VERSION "HNNBNNNYNNNNNNNNNNNNNNNNNNNNNNNNNNNNNNNNNN/4/%%%/4/'%**4NNN///"

NS_ :

BS_:

BU_: BAP_Tester BCM1 Gateway Gateway_PAG Klima_MSB Lift_VA VAS_L VAS_R

BO_ 2589283621 Klima_17: 8 BCM1
 SG_ KL_NV_Energie_Anf : 12|8@1+ (10,0) [0|2530] "Unit_WattHour"  Gateway,Gateway_PAG
 SG_ KL_FlHz_Soll_VL : 20|3@1+ (1,0) [0|6] "Unit_None"  BCM1,Gateway,Gateway_PAG
 SG_ KL_FlHz_Soll_HL : 23|3@1+ (1,0) [0|6] "Unit_None"  BCM1,Gateway,Gateway_PAG
 SG_ KL_FlHz_Soll_VR : 26|3@1+ (1,0) [0|6] "Unit_None"  BCM1,Gateway,Gateway_PAG
 SG_ KL_FlHz_Soll_HR : 29|3@1+ (1,0) [0|6] "Unit_None"  BCM1,Gateway,Gateway_PAG
 SG_ KL_Umluft_Connect_status : 32|3@1+ (1.0,0.0) [0.0|7] ""  Gateway,Gateway_PAG
 SG_ KL_ECO_PRO_Aktiv : 35|1@1+ (1.0,0.0) [0.0|1] ""  Gateway,Gateway_PAG
 SG_ KL_QBit_Sonnenintensitaet : 36|1@1+ (1.0,0.0) [0.0|1] ""  Gateway,Gateway_PAG
 SG_ KL_ZR_Anforderung : 37|2@1+ (1.0,0.0) [0.0|3] ""  Gateway,Gateway_PAG
 SG_ KL_ACmax_Aktiv : 39|1@1+ (1.0,0.0) [0.0|1] ""  Gateway,Gateway_PAG
 SG_ KL_Defrost_Aktiv : 40|1@1+ (1.0,0.0) [0.0|1] ""  Gateway,Gateway_PAG
 SG_ KL_ECO_Aktiv : 41|1@1+ (1.0,0.0) [0.0|1] ""  Gateway,Gateway_PAG
 SG_ KL_Status_Klimastil : 42|2@1+ (1.0,0.0) [0.0|3] ""  Gateway,Gateway_PAG
 SG_ KL_Kundeneingriff_Geblaese : 44|1@1+ (1.0,0.0) [0.0|1] ""  Gateway,Gateway_PAG
 SG_ KL_Thermischer_Bedarf : 45|3@1+ (1.0,0.0) [0.0|7] ""  Gateway,Gateway_PAG
 SG_ KL_Eps_Innen : 48|8@1+ (0.5,-50) [-50.0|50.0] "Unit_DegreCelsi"  Gateway,Gateway_PAG
 SG_ KL_Sonnenintensitaet : 56|8@1+ (10,0) [0|1000] "Unit_WattPerMeterSquar"  Gateway,Gateway_PAG

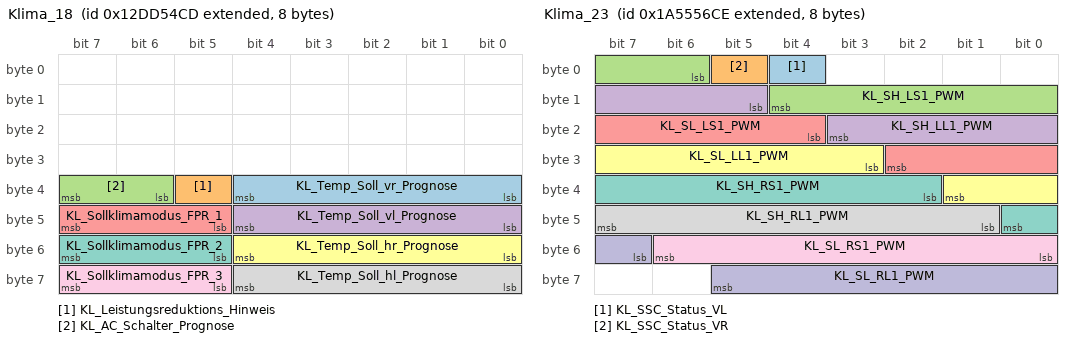
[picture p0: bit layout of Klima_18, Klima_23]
BO_ 2463978701 Klima_18: 8 BCM1
 SG_ KL_Temp_Soll_vr_Prognose : 32|5@1+ (0.5,15.5) [15.5|30.0] "Unit_DegreCelsi"  Gateway,Gateway_PAG
 SG_ KL_Leistungsreduktions_Hinweis : 37|1@1+ (1.0,0.0) [0.0|1] ""  Gateway,Gateway_PAG
 SG_ KL_AC_Schalter_Prognose : 38|2@1+ (1.0,0.0) [0.0|3] ""  Gateway,Gateway_PAG
 SG_ KL_Temp_Soll_vl_Prognose : 40|5@1+ (0.5,15.5) [15.5|30.0] "Unit_DegreCelsi"  Gateway,Gateway_PAG
 SG_ KL_Sollklimamodus_FPR_1 : 45|3@1+ (1.0,0.0) [0.0|7] ""  Gateway,Gateway_PAG
 SG_ KL_Temp_Soll_hr_Prognose : 48|5@1+ (0.5,15.5) [15.5|30.0] "Unit_DegreCelsi"  Gateway,Gateway_PAG
 SG_ KL_Sollklimamodus_FPR_2 : 53|3@1+ (1.0,0.0) [0.0|7] ""  Gateway,Gateway_PAG
 SG_ KL_Temp_Soll_hl_Prognose : 56|5@1+ (0.5,15.5) [15.5|30.0] "Unit_DegreCelsi"  Gateway,Gateway_PAG
 SG_ KL_Sollklimamodus_FPR_3 : 61|3@1+ (1.0,0.0) [0.0|7] ""  Gateway,Gateway_PAG

BO_ 2589283689 Klima_19: 8 Klima_MSB
 SG_ KL_FANonly_Aktiv : 63|1@1+ (1.0,0.0) [0.0|1] ""  Gateway_PAG

BO_ 2589284046 Klima_23: 8 Klima_MSB
 SG_ KL_SSC_Status_VL : 4|1@1+ (1.0,0.0) [0.0|1] ""  BCM1
 SG_ KL_SSC_Status_VR : 5|1@1+ (1.0,0.0) [0.0|1] ""  BCM1
 SG_ KL_SH_LS1_PWM : 6|7@1+ (1,0) [0|100] "Unit_PerCent"  BCM1
 SG_ KL_SH_LL1_PWM : 13|7@1+ (1,0) [0|100] "Unit_PerCent"  BCM1
 SG_ KL_SL_LS1_PWM : 20|7@1+ (1,0) [0|100] "Unit_PerCent"  BCM1
 SG_ KL_SL_LL1_PWM : 27|7@1+ (1,0) [0|100] "Unit_PerCent"  BCM1
 SG_ KL_SH_RS1_PWM : 34|7@1+ (1,0) [0|100] "Unit_PerCent"  BCM1
 SG_ KL_SH_RL1_PWM : 41|7@1+ (1,0) [0|100] "Unit_PerCent"  BCM1
 SG_ KL_SL_RS1_PWM : 48|7@1+ (1,0) [0|100] "Unit_PerCent"  BCM1
 SG_ KL_SL_RL1_PWM : 55|7@1+ (1,0) [0|100] "Unit_PerCent"  BCM1

BO_ 992 Klima_hinten_01: 8 BCM1
 SG_ KL_Fond_Fuss_Temp_hl : 0|10@1+ (0.1,-5) [-5.0|97.1] "Unit_DegreCelsi"  Gateway,Gateway_PAG
 SG_ KL_SL_Soll_hl : 10|3@1+ (1.0,0.0) [0.0|7] ""  BCM1,Gateway,Gateway_PAG
 SG_ KL_SL_Soll_hr : 13|3@1+ (1.0,0.0) [0.0|7] ""  BCM1,Gateway,Gateway_PAG
 SG_ KL_Fond_Fuss_Temp_hr : 16|10@1+ (0.1,-5) [-5.0|97.1] "Unit_DegreCelsi"  Gateway,Gateway_PAG
 SG_ KL_SH_Soll_hl : 26|3@1+ (1.0,0.0) [0.0|7] ""  BCM1,Gateway,Gateway_PAG
 SG_ KL_SH_Soll_hr : 29|3@1+ (1.0,0.0) [0.0|7] ""  BCM1,Gateway,Gateway_PAG
 SG_ KL_MA_Temp_hl : 32|10@1+ (0.1,-5) [-5.0|97.1] "Unit_DegreCelsi"  Gateway,Gateway_PAG
 SG_ KL_SIH_Takt_hl : 42|1@1+ (1.0,0.0) [0.0|1] ""  Gateway,Gateway_PAG
 SG_ KL_SIH_Takt_hr : 43|1@1+ (1.0,0.0) [0.0|1] ""  Gateway,Gateway_PAG
 SG_ KL_Fehler_Umluft : 44|1@1+ (1.0,0.0) [0.0|1] ""  Gateway,Gateway_PAG
 SG_ KL_RAB : 45|1@1+ (1.0,0.0) [0.0|1] ""  Gateway,Gateway_PAG
 SG_ KL_Fond_Absperrventil : 46|1@1+ (1.0,0.0) [0.0|1] ""  Gateway,Gateway_PAG
 SG_ KL_Fond_KD_Fehler : 47|1@1+ (1.0,0.0) [0.0|1] ""  Gateway,Gateway_PAG
 SG_ KL_MA_Temp_hr : 48|10@1+ (0.1,-5) [-5.0|97.1] "Unit_DegreCelsi"  Gateway,Gateway_PAG
 SG_ KL_Fehler_Fussraum_Klappen : 58|2@1+ (1.0,0.0) [0.0|3] ""  Gateway,Gateway_PAG
 SG_ KL_Fehler_Temp_Klappen : 60|2@1+ (1.0,0.0) [0.0|3] ""  Gateway,Gateway_PAG
 SG_ KL_Fehler_Temp_MA_Klappen : 62|2@1+ (1.0,0.0) [0.0|3] ""  Gateway,Gateway_PAG

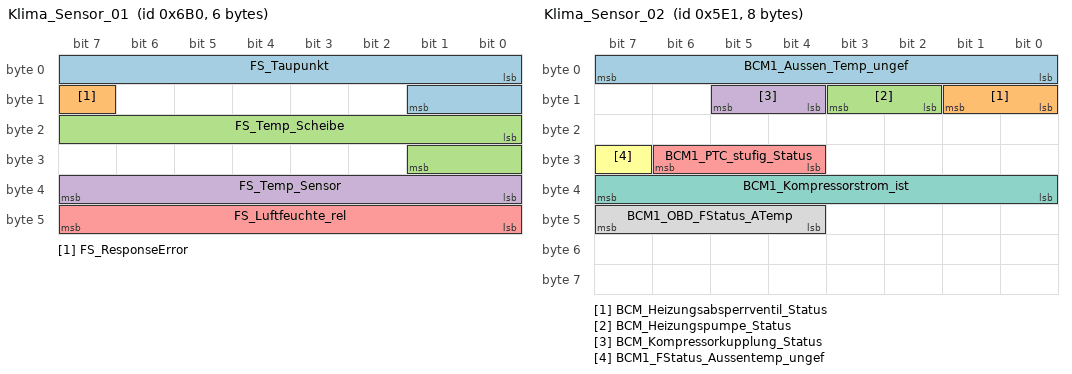
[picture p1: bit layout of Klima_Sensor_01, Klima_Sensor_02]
BO_ 1712 Klima_Sensor_01: 6 BCM1
 SG_ FS_Taupunkt : 0|10@1+ (0.1,-39.6) [-39.5|60.4] "Unit_DegreCelsi"  Gateway,Gateway_PAG,Klima_MSB
 SG_ FS_ResponseError : 15|1@1+ (1.0,0.0) [0.0|1] ""  Gateway,Gateway_PAG,Klima_MSB
 SG_ FS_Temp_Scheibe : 16|10@1+ (0.1,-39.6) [-39.5|60.4] "Unit_DegreCelsi"  Gateway,Gateway_PAG,Klima_MSB
 SG_ FS_Temp_Sensor : 32|8@1+ (0.5,-40) [-39.5|87.0] "Unit_DegreCelsi"  Gateway,Gateway_PAG,Klima_MSB
 SG_ FS_Luftfeuchte_rel : 40|8@1+ (0.5,-0.5) [0.0|100.0] "Unit_PerCent"  Gateway,Gateway_PAG,Klima_MSB

BO_ 1505 Klima_Sensor_02: 8 BCM1
 SG_ BCM1_Aussen_Temp_ungef : 0|8@1+ (0.5,-50) [-50.0|76.0] "Unit_DegreCelsi"  Gateway,Gateway_PAG,Klima_MSB,VAS_L,VAS_R
 SG_ BCM_Heizungsabsperrventil_Status : 8|2@1+ (1.0,0.0) [0.0|3] ""  Gateway,Gateway_PAG,Klima_MSB
 SG_ BCM_Heizungspumpe_Status : 10|2@1+ (1.0,0.0) [0.0|3] ""  Gateway,Gateway_PAG,Klima_MSB
 SG_ BCM_Kompressorkupplung_Status : 12|2@1+ (1.0,0.0) [0.0|3] ""  Gateway,Gateway_PAG,Klima_MSB
 SG_ BCM1_PTC_stufig_Status : 28|3@1+ (1.0,0.0) [0.0|7] ""  Gateway,Gateway_PAG,Klima_MSB
 SG_ BCM1_FStatus_Aussentemp_ungef : 31|1@1+ (1.0,0.0) [0.0|1] ""  Gateway,Gateway_PAG,Klima_MSB,VAS_L,VAS_R
 SG_ BCM1_Kompressorstrom_ist : 32|8@1+ (4,0) [0|1000] "Unit_MilliAmper"  Gateway,Gateway_PAG,Klima_MSB
 SG_ BCM1_OBD_FStatus_ATemp : 44|4@1+ (1.0,0.0) [0.0|15] ""  Gateway,Gateway_PAG,Klima_MSB

BO_ 1717 Klima_Sensor_03: 8 BCM1
 SG_ FSA_Taupunkt : 0|10@1+ (0.1,-40) [-40.0|60.0] "Unit_DegreCelsi"  Gateway,Gateway_PAG
 SG_ FSA_Err_Defekt_Tsens_TF : 10|1@1+ (1.0,0.0) [0.0|1] ""  Gateway,Gateway_PAG
 SG_ FSA_Luftfeuchte_TNCTOC : 11|1@1+ (1.0,0.0) [0.0|1] ""  Gateway,Gateway_PAG
 SG_ FSA_Luftfeuchte_TF : 12|1@1+ (1.0,0.0) [0.0|1] ""  Gateway,Gateway_PAG
 SG_ FSA_Err_Unterspannung_TF : 13|1@1+ (1.0,0.0) [0.0|1] ""  Gateway,Gateway_PAG
 SG_ FSA_Err_RAMROM_Check_TF : 14|1@1+ (1.0,0.0) [0.0|1] ""  Gateway,Gateway_PAG
 SG_ FSA_ResponseError : 15|1@1+ (1.0,0.0) [0.0|1] ""  Gateway,Gateway_PAG
 SG_ FSA_Temp_Luft : 16|10@1+ (0.1,-40) [-40.0|61.0] "Unit_DegreCelsi"  Gateway,Gateway_PAG
 SG_ FSA_Err_RAMROM_Check_TNCTOC : 26|1@1+ (1.0,0.0) [0.0|1] ""  Gateway,Gateway_PAG
 SG_ FSA_Lokal_Bus_elektr_Fehler : 27|1@1+ (1.0,0.0) [0.0|1] ""  Gateway,Gateway_PAG
 SG_ FSA_Timeout : 28|1@1+ (1.0,0.0) [0.0|1] ""  Gateway,Gateway_PAG
 SG_ FSA_Lokal_Bus_Unterbrechung : 29|1@1+ (1.0,0.0) [0.0|1] ""  Gateway,Gateway_PAG
 SG_ FSA_Err_Ueberspannung_TF : 30|1@1+ (1.0,0.0) [0.0|1] ""  Gateway,Gateway_PAG
 SG_ FSA_Luftfeuchte_rel : 32|8@1+ (0.5,0) [0.0|126.0] "Unit_PerCent"  Gateway,Gateway_PAG
 SG_ FSA_HW : 40|4@1+ (1,0) [0|15] ""  Gateway,Gateway_PAG
 SG_ FSA_SW : 44|4@1+ (1,0) [0|15] ""  Gateway,Gateway_PAG
 SG_ FSA_Temp_Sensor : 48|11@1+ (0.1,-40) [-40.0|90.0] "Unit_DegreCelsi"  Gateway,Gateway_PAG
 SG_ FSA_Sensorheizung_Status : 59|1@1+ (1.0,0.0) [0.0|1] ""  Gateway,Gateway_PAG
 SG_ FSA_Err_Defekt_HumSense_TF : 60|1@1+ (1.0,0.0) [0.0|1] ""  Gateway,Gateway_PAG
 SG_ FSA_Err_Defekt_HumSens_TNCTOC : 61|1@1+ (1.0,0.0) [0.0|1] ""  Gateway,Gateway_PAG
 SG_ FSA_ErrMemState : 62|2@1+ (1.0,0.0) [0.0|3] ""  Gateway,Gateway_PAG

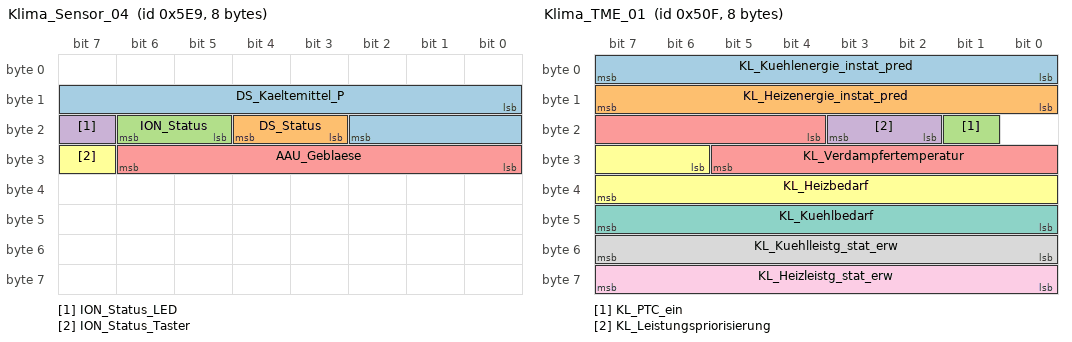
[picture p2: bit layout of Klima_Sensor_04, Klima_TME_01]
BO_ 1513 Klima_Sensor_04: 8 BCM1
 SG_ DS_Kaeltemittel_P : 8|11@1+ (0.0161,0) [0.0000|32.9245] "Unit_Bar"  Gateway,Gateway_PAG
 SG_ DS_Status : 19|2@1+ (1.0,0.0) [0.0|3] ""  Gateway,Gateway_PAG
 SG_ ION_Status : 21|2@1+ (1.0,0.0) [0.0|3] ""  Gateway,Gateway_PAG
 SG_ ION_Status_LED : 23|1@1+ (1.0,0.0) [0.0|1] ""  Gateway,Gateway_PAG
 SG_ AAU_Geblaese : 24|7@1+ (1,0) [0|100] "Unit_PerCent"  Gateway,Gateway_PAG
 SG_ ION_Status_Taster : 31|1@1+ (1.0,0.0) [0.0|1] ""  Gateway,Gateway_PAG

BO_ 1295 Klima_TME_01: 8 BCM1
 SG_ KL_Kuehlenergie_instat_pred : 0|8@1+ (25,0) [0|6325] "Unit_WattHour"  Gateway,Gateway_PAG
 SG_ KL_Heizenergie_instat_pred : 8|8@1+ (25,0) [0|6325] "Unit_WattHour"  Gateway,Gateway_PAG
 SG_ KL_PTC_ein : 17|1@1+ (1.0,0.0) [0.0|1] ""  Gateway,Gateway_PAG
 SG_ KL_Leistungspriorisierung : 18|2@1+ (1.0,0.0) [0.0|3] ""  Gateway,Gateway_PAG
 SG_ KL_Verdampfertemperatur : 20|10@1+ (0.1,-20) [-20.0|70.0] "Unit_DegreCelsi"  Gateway,Gateway_PAG
 SG_ KL_Heizbedarf : 30|10@1+ (0.1,0) [0.1|90.0] "Unit_DegreCelsi"  Gateway,Gateway_PAG
 SG_ KL_Kuehlbedarf : 40|8@1+ (0.1,0) [0.0|25.0] "Unit_DegreCelsi"  Gateway,Gateway_PAG
 SG_ KL_Kuehlleistg_stat_erw : 48|8@1+ (50,0) [0|12650] "Unit_Watt"  Gateway,Gateway_PAG
 SG_ KL_Heizleistg_stat_erw : 56|8@1+ (50,0) [0|12650] "Unit_Watt"  Gateway,Gateway_PAG

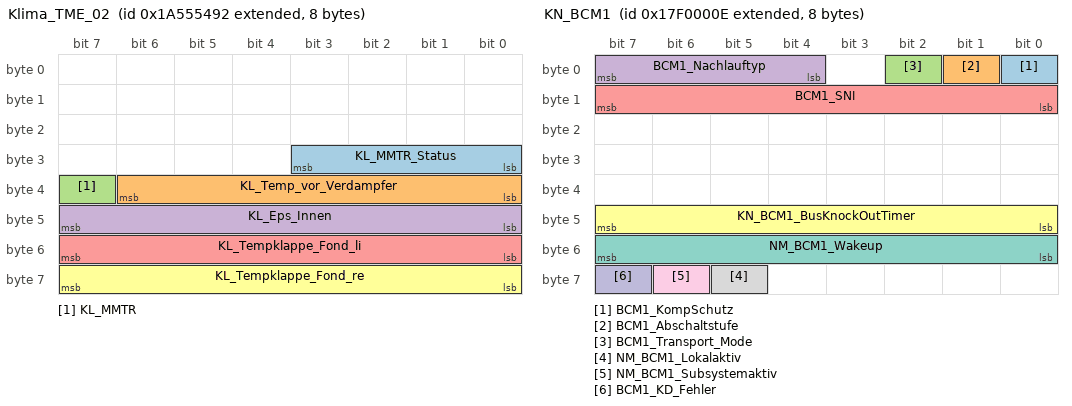
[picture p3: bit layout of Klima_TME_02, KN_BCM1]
BO_ 2589283474 Klima_TME_02: 8 BCM1
 SG_ KL_MMTR_Status : 24|4@1+ (1.0,0.0) [0.0|15] ""  Gateway,Gateway_PAG
 SG_ KL_Temp_vor_Verdampfer : 32|7@1+ (1,-20) [-20|70] "Unit_DegreCelsi"  Gateway,Gateway_PAG
 SG_ KL_MMTR : 39|1@1+ (1.0,0.0) [0.0|1] ""  Gateway,Gateway_PAG
 SG_ KL_Eps_Innen : 40|8@1+ (0.5,-50) [-50.0|50.0] "Unit_DegreCelsi"  Gateway,Gateway_PAG
 SG_ KL_Tempklappe_Fond_li : 48|8@1+ (0.5,0) [0.0|100.0] "Unit_PerCent"  Gateway,Gateway_PAG
 SG_ KL_Tempklappe_Fond_re : 56|8@1+ (0.5,0) [0.0|100.0] "Unit_PerCent"  Gateway,Gateway_PAG

BO_ 2549088270 KN_BCM1: 8 BCM1
 SG_ BCM1_KompSchutz : 0|1@1+ (1.0,0.0) [0.0|1] ""  Vector__XXX
 SG_ BCM1_Abschaltstufe : 1|1@1+ (1.0,0.0) [0.0|1] ""  Vector__XXX
 SG_ BCM1_Transport_Mode : 2|1@1+ (1.0,0.0) [0.0|1] ""  Vector__XXX
 SG_ BCM1_Nachlauftyp : 4|4@1+ (1.0,0.0) [0.0|15] ""  Gateway,Gateway_PAG
 SG_ BCM1_SNI : 8|8@1+ (1.0,0.0) [0.0|255] ""  Gateway,Gateway_PAG
 SG_ KN_BCM1_BusKnockOutTimer : 40|8@1+ (1,0) [0|254] "Unit_Minut"  Gateway,Gateway_PAG
 SG_ NM_BCM1_Wakeup : 48|8@1+ (1.0,0.0) [0.0|255] ""  Vector__XXX
 SG_ NM_BCM1_Lokalaktiv : 61|1@1+ (1.0,0.0) [0.0|1] ""  Gateway,Gateway_PAG
 SG_ NM_BCM1_Subsystemaktiv : 62|1@1+ (1.0,0.0) [0.0|1] ""  Gateway,Gateway_PAG
 SG_ BCM1_KD_Fehler : 63|1@1+ (1.0,0.0) [0.0|1] ""  Gateway,Gateway_PAG

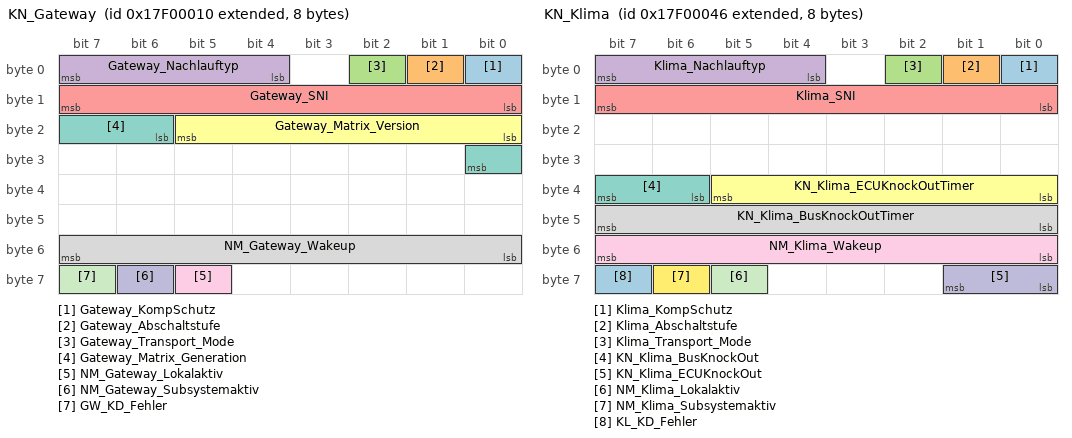
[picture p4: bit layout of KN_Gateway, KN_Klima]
BO_ 2549088272 KN_Gateway: 8 Gateway
 SG_ Gateway_KompSchutz : 0|1@1+ (1.0,0.0) [0.0|1] ""  Vector__XXX
 SG_ Gateway_Abschaltstufe : 1|1@1+ (1.0,0.0) [0.0|1] ""  Vector__XXX
 SG_ Gateway_Transport_Mode : 2|1@1+ (1.0,0.0) [0.0|1] ""  Vector__XXX
 SG_ Gateway_Nachlauftyp : 4|4@1+ (1.0,0.0) [0.0|15] ""  Vector__XXX
 SG_ Gateway_SNI : 8|8@1+ (1.0,0.0) [0.0|255] ""  Vector__XXX
 SG_ Gateway_Matrix_Version : 16|6@1+ (1,0) [0|63] "Unit_None"  Vector__XXX
 SG_ Gateway_Matrix_Generation : 22|3@1+ (1,0) [0|7] "Unit_None"  Vector__XXX
 SG_ NM_Gateway_Wakeup : 48|8@1+ (1.0,0.0) [0.0|255] ""  Vector__XXX
 SG_ NM_Gateway_Lokalaktiv : 61|1@1+ (1.0,0.0) [0.0|1] ""  Vector__XXX
 SG_ NM_Gateway_Subsystemaktiv : 62|1@1+ (1.0,0.0) [0.0|1] ""  Vector__XXX
 SG_ GW_KD_Fehler : 63|1@1+ (1.0,0.0) [0.0|1] ""  Vector__XXX

BO_ 2549088326 KN_Klima: 8 Klima_MSB
 SG_ Klima_KompSchutz : 0|1@1+ (1.0,0.0) [0.0|1] ""  Vector__XXX
 SG_ Klima_Abschaltstufe : 1|1@1+ (1.0,0.0) [0.0|1] ""  Vector__XXX
 SG_ Klima_Transport_Mode : 2|1@1+ (1.0,0.0) [0.0|1] ""  Vector__XXX
 SG_ Klima_Nachlauftyp : 4|4@1+ (1.0,0.0) [0.0|15] ""  Gateway,Gateway_PAG
 SG_ Klima_SNI : 8|8@1+ (1.0,0.0) [0.0|255] ""  Gateway,Gateway_PAG
 SG_ KN_Klima_ECUKnockOutTimer : 32|6@1+ (1,0) [0|62] "Unit_Minut"  Gateway,Gateway_PAG
 SG_ KN_Klima_BusKnockOut : 38|2@1+ (1.0,0.0) [0.0|3] ""  Gateway,Gateway_PAG
 SG_ KN_Klima_BusKnockOutTimer : 40|8@1+ (1,0) [0|254] ""  Gateway,Gateway_PAG
 SG_ NM_Klima_Wakeup : 48|8@1+ (1.0,0.0) [0.0|255] ""  Vector__XXX
 SG_ KN_Klima_ECUKnockOut : 56|2@1+ (1.0,0.0) [0.0|3] ""  Gateway,Gateway_PAG
 SG_ NM_Klima_Lokalaktiv : 61|1@1+ (1.0,0.0) [0.0|1] ""  Gateway,Gateway_PAG
 SG_ NM_Klima_Subsystemaktiv : 62|1@1+ (1.0,0.0) [0.0|1] ""  Gateway,Gateway_PAG
 SG_ KL_KD_Fehler : 63|1@1+ (1.0,0.0) [0.0|1] ""  Gateway,Gateway_PAG

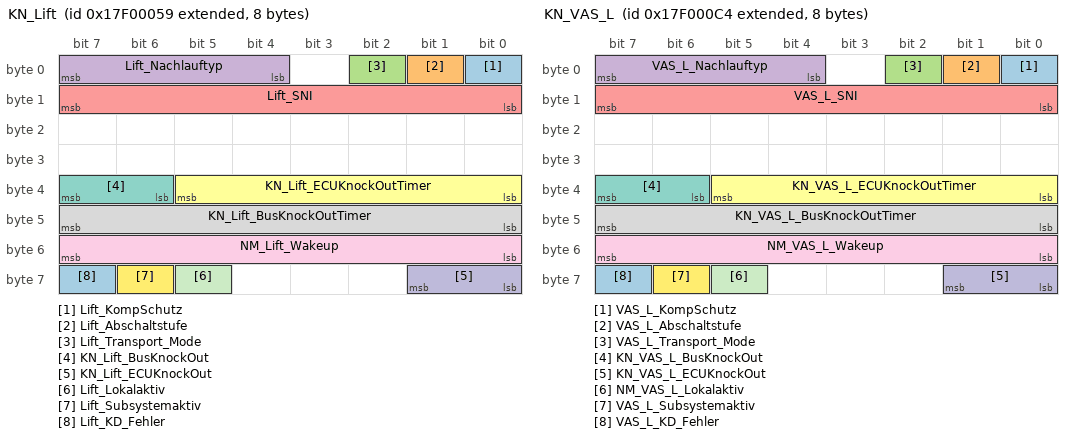
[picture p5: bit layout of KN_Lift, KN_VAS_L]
BO_ 2549088345 KN_Lift: 8 Lift_VA
 SG_ Lift_KompSchutz : 0|1@1+ (1.0,0.0) [0.0|1] ""  Vector__XXX
 SG_ Lift_Abschaltstufe : 1|1@1+ (1.0,0.0) [0.0|1] ""  Vector__XXX
 SG_ Lift_Transport_Mode : 2|1@1+ (1.0,0.0) [0.0|1] ""  Vector__XXX
 SG_ Lift_Nachlauftyp : 4|4@1+ (1.0,0.0) [0.0|15] ""  Gateway,Gateway_PAG
 SG_ Lift_SNI : 8|8@1+ (1.0,0.0) [0.0|255] ""  Gateway,Gateway_PAG
 SG_ KN_Lift_ECUKnockOutTimer : 32|6@1+ (1,0) [0|62] "Unit_Minut"  Gateway
 SG_ KN_Lift_BusKnockOut : 38|2@1+ (1.0,0.0) [0.0|3] ""  Gateway
 SG_ KN_Lift_BusKnockOutTimer : 40|8@1+ (1,0) [0|254] ""  Gateway
 SG_ NM_Lift_Wakeup : 48|8@1+ (1.0,0.0) [0.0|255] ""  Vector__XXX
 SG_ KN_Lift_ECUKnockOut : 56|2@1+ (1.0,0.0) [0.0|3] ""  Gateway
 SG_ Lift_Lokalaktiv : 61|1@1+ (1.0,0.0) [0.0|1] ""  Gateway,Gateway_PAG
 SG_ Lift_Subsystemaktiv : 62|1@1+ (1.0,0.0) [0.0|1] ""  Gateway
 SG_ Lift_KD_Fehler : 63|1@1+ (1.0,0.0) [0.0|1] ""  Gateway,Gateway_PAG

BO_ 2549088452 KN_VAS_L: 8 VAS_L
 SG_ VAS_L_KompSchutz : 0|1@1+ (1.0,0.0) [0.0|1] ""  Vector__XXX
 SG_ VAS_L_Abschaltstufe : 1|1@1+ (1.0,0.0) [0.0|1] ""  Vector__XXX
 SG_ VAS_L_Transport_Mode : 2|1@1+ (1.0,0.0) [0.0|1] ""  Vector__XXX
 SG_ VAS_L_Nachlauftyp : 4|4@1+ (1.0,0.0) [0.0|15] ""  Gateway,Gateway_PAG
 SG_ VAS_L_SNI : 8|8@1+ (1.0,0.0) [0.0|255] ""  Gateway,Gateway_PAG
 SG_ KN_VAS_L_ECUKnockOutTimer : 32|6@1+ (1,0) [0|62] ""  Gateway,Gateway_PAG
 SG_ KN_VAS_L_BusKnockOut : 38|2@1+ (1.0,0.0) [0.0|3] ""  Gateway,Gateway_PAG
 SG_ KN_VAS_L_BusKnockOutTimer : 40|8@1+ (1,0) [0|254] ""  Gateway,Gateway_PAG
 SG_ NM_VAS_L_Wakeup : 48|8@1+ (1.0,0.0) [0.0|255] ""  Vector__XXX
 SG_ KN_VAS_L_ECUKnockOut : 56|2@1+ (1.0,0.0) [0.0|3] ""  Gateway,Gateway_PAG
 SG_ NM_VAS_L_Lokalaktiv : 61|1@1+ (1.0,0.0) [0.0|1] ""  Gateway,Gateway_PAG
 SG_ VAS_L_Subsystemaktiv : 62|1@1+ (1.0,0.0) [0.0|1] ""  Vector__XXX
 SG_ VAS_L_KD_Fehler : 63|1@1+ (1.0,0.0) [0.0|1] ""  Gateway,Gateway_PAG

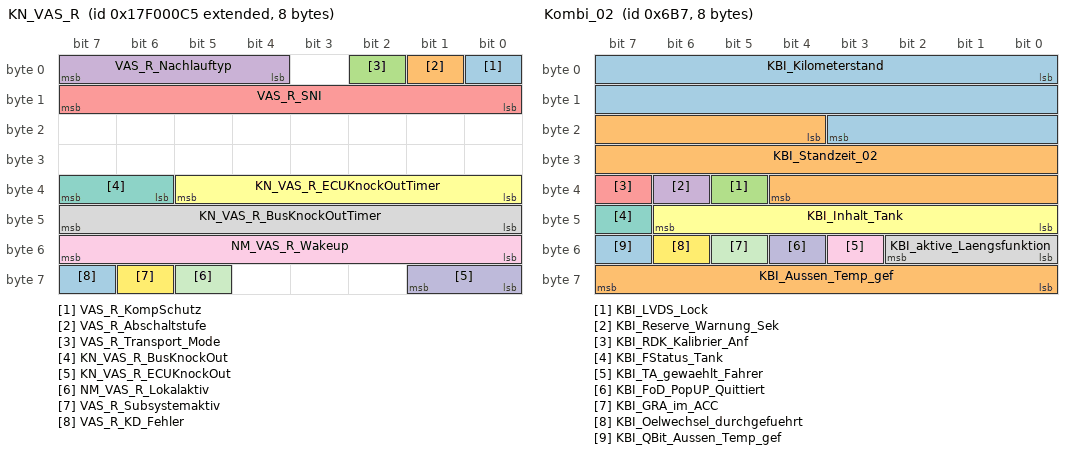
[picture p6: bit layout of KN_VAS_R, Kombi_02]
BO_ 2549088453 KN_VAS_R: 8 VAS_R
 SG_ VAS_R_KompSchutz : 0|1@1+ (1.0,0.0) [0.0|1] ""  Vector__XXX
 SG_ VAS_R_Abschaltstufe : 1|1@1+ (1.0,0.0) [0.0|1] ""  Vector__XXX
 SG_ VAS_R_Transport_Mode : 2|1@1+ (1.0,0.0) [0.0|1] ""  Vector__XXX
 SG_ VAS_R_Nachlauftyp : 4|4@1+ (1.0,0.0) [0.0|15] ""  Gateway,Gateway_PAG
 SG_ VAS_R_SNI : 8|8@1+ (1.0,0.0) [0.0|255] ""  Gateway,Gateway_PAG
 SG_ KN_VAS_R_ECUKnockOutTimer : 32|6@1+ (1,0) [0|62] ""  Gateway,Gateway_PAG
 SG_ KN_VAS_R_BusKnockOut : 38|2@1+ (1.0,0.0) [0.0|3] ""  Gateway,Gateway_PAG
 SG_ KN_VAS_R_BusKnockOutTimer : 40|8@1+ (1,0) [0|254] ""  Gateway,Gateway_PAG
 SG_ NM_VAS_R_Wakeup : 48|8@1+ (1.0,0.0) [0.0|255] ""  Vector__XXX
 SG_ KN_VAS_R_ECUKnockOut : 56|2@1+ (1.0,0.0) [0.0|3] ""  Gateway,Gateway_PAG
 SG_ NM_VAS_R_Lokalaktiv : 61|1@1+ (1.0,0.0) [0.0|1] ""  Gateway,Gateway_PAG
 SG_ VAS_R_Subsystemaktiv : 62|1@1+ (1.0,0.0) [0.0|1] ""  Vector__XXX
 SG_ VAS_R_KD_Fehler : 63|1@1+ (1.0,0.0) [0.0|1] ""  Gateway,Gateway_PAG

BO_ 779 Kombi_01: 8 Gateway
 SG_ KBI_ABS_Lampe : 0|1@1+ (1.0,0.0) [0.0|1] ""  Vector__XXX
 SG_ KBI_ESP_Lampe : 1|1@1+ (1.0,0.0) [0.0|1] ""  BCM1
 SG_ KBI_BKL_Lampe : 2|1@1+ (1.0,0.0) [0.0|1] ""  Vector__XXX
 SG_ KBI_Airbag_Lampe : 3|1@1+ (1.0,0.0) [0.0|1] ""  Vector__XXX
 SG_ KBI_SILA_gueltig : 4|1@1+ (1.0,0.0) [0.0|1] ""  Vector__XXX
 SG_ KBI_Lenkung_Lampe : 5|1@1+ (1,0) [0|1] ""  Vector__XXX
 SG_ KBI_Vorglueh_System_Lampe : 6|1@1+ (1.0,0.0) [0.0|1] ""  Vector__XXX
 SG_ KBI_NV_in_Anzeige : 7|1@1+ (1.0,0.0) [0.0|1] ""  Vector__XXX
 SG_ Kombi_01_BZ : 8|4@1+ (1,0) [0|15] ""  Vector__XXX
 SG_ KBI_Anzeigestatus_ACC : 12|1@1+ (1.0,0.0) [0.0|1] ""  Vector__XXX
 SG_ KBI_Anzeigestatus_GRA : 13|2@1+ (1.0,0.0) [0.0|3] ""  Vector__XXX
 SG_ KBI_Tankwarnung : 16|1@1+ (1.0,0.0) [0.0|1] ""  BCM1,Klima_MSB
 SG_ KBI_MFA_v_Einheit_01 : 17|1@1+ (1.0,0.0) [0.0|1] ""  Vector__XXX
 SG_ KBI_im_Stellgliedtest : 18|1@1+ (1.0,0.0) [0.0|1] ""  Vector__XXX
 SG_ KBI_Anzeigefehler_LDW : 19|2@1+ (1.0,0.0) [0.0|3] ""  Vector__XXX
 SG_ KBI_Tankwarnung_ungueltig : 21|1@1+ (1.0,0.0) [0.0|1] ""  Vector__XXX
 SG_ KBI_Handbremse : 23|1@1+ (1.0,0.0) [0.0|1] ""  Vector__XXX
 SG_ KBI_V_Digital : 24|9@1+ (1,0) [0|511] ""  Vector__XXX
 SG_ KBI_PLA_in_Anzeige : 33|1@1+ (1.0,0.0) [0.0|1] ""  BCM1
 SG_ KBI_Anzeigefehler_NV : 34|1@1+ (1.0,0.0) [0.0|1] ""  Vector__XXX
 SG_ KBI_Anzeigestatus_LIM : 35|2@1+ (1.0,0.0) [0.0|3] ""  Vector__XXX
 SG_ KBI_ARA_in_Anzeige : 37|1@1+ (1.0,0.0) [0.0|1] ""  BCM1
 SG_ KBI_Taster_Lift : 38|1@1+ (1.0,0.0) [0.0|1] ""  Vector__XXX
 SG_ KBI_Taster_Fahrwerk : 39|1@1+ (1.0,0.0) [0.0|1] ""  Vector__XXX
 SG_ KBI_GRA_Hauptschalter : 40|2@1+ (1.0,0.0) [0.0|3] ""  Vector__XXX
 SG_ KBI_Bestaetigung_ESP_Off : 42|2@1+ (1.0,0.0) [0.0|3] ""  Vector__XXX
 SG_ KBI_angez_Geschw : 48|10@1+ (0.32,0) [0.00|325.12] "Unit_KiloMeterPerHour"  Vector__XXX
 SG_ KBI_Einheit_Tacho : 58|1@1+ (1.0,0.0) [0.0|1] ""  Vector__XXX
 SG_ KBI_Konsistenz_ACC : 59|1@1+ (1.0,0.0) [0.0|1] ""  Vector__XXX
 SG_ KBI_Fehler_Anzeige_ACC : 60|1@1+ (1.0,0.0) [0.0|1] ""  Vector__XXX
 SG_ KBI_Anzeigefehler_SWA : 61|2@1+ (1.0,0.0) [0.0|3] ""  Vector__XXX
 SG_ KBI_Systemstatus : 63|1@1+ (1.0,0.0) [0.0|1] ""  Vector__XXX

BO_ 1719 Kombi_02: 8 Gateway
 SG_ KBI_Kilometerstand : 0|20@1+ (1,0) [0|1048573] "Unit_KiloMeter"  Vector__XXX
 SG_ KBI_Standzeit_02 : 20|17@1+ (1,0) [0|131068] "Unit_Secon"  BCM1,Klima_MSB
 SG_ KBI_LVDS_Lock : 37|1@1+ (1.0,0.0) [0.0|1] ""  Vector__XXX
 SG_ KBI_Reserve_Warnung_Sek : 38|1@1+ (1.0,0.0) [0.0|1] ""  Vector__XXX
 SG_ KBI_RDK_Kalibrier_Anf : 39|1@1+ (1.0,0.0) [0.0|1] ""  Vector__XXX
 SG_ KBI_Inhalt_Tank : 40|7@1+ (1,0) [0|125] "Unit_Liter"  Vector__XXX
 SG_ KBI_FStatus_Tank : 47|1@1+ (1.0,0.0) [0.0|1] ""  Vector__XXX
 SG_ KBI_aktive_Laengsfunktion : 48|3@1+ (1.0,0.0) [0.0|7] ""  Vector__XXX
 SG_ KBI_TA_gewaehlt_Fahrer : 51|1@1+ (1.0,0.0) [0.0|1] ""  Vector__XXX
 SG_ KBI_FoD_PopUP_Quittiert : 52|1@1+ (1.0,0.0) [0.0|1] ""  Vector__XXX
 SG_ KBI_GRA_im_ACC : 53|1@1+ (1.0,0.0) [0.0|1] ""  Vector__XXX
 SG_ KBI_Oelwechsel_durchgefuehrt : 54|1@1+ (1.0,0.0) [0.0|1] ""  Vector__XXX
 SG_ KBI_QBit_Aussen_Temp_gef : 55|1@1+ (1.0,0.0) [0.0|1] ""  BCM1,Klima_MSB
 SG_ KBI_Aussen_Temp_gef : 56|8@1+ (0.5,-50) [-50.0|75.0] "Unit_DegreCelsi"  BCM1,Klima_MSB,Lift_VA,VAS_L,VAS_R

BO_ 2549874958 KS_BCM1_Req: 8 Gateway
 SG_ KS_BCM1_Req_Data : 0|64@1+ (1.0,0.0) [0.0|18446744073709551615] ""  BCM1

BO_ 2550006030 KS_BCM1_Resp: 8 BCM1
 SG_ KS_BCM1_Resp_Data : 0|64@1+ (1.0,0.0) [0.0|18446744073709551615] ""  Gateway,Gateway_PAG

BO_ 2549875140 KS_VAS_L_Req: 8 Gateway
 SG_ KS_VAS_L_Req_Data : 0|64@1+ (1,0) [0|1] ""  VAS_L

BO_ 2550006212 KS_VAS_L_Resp: 8 VAS_L
 SG_ KS_VAS_L_Resp_Data : 0|64@1+ (1,0) [0|1] ""  Gateway,Gateway_PAG

BO_ 2549875141 KS_VAS_R_Req: 8 Gateway
 SG_ KS_VAS_R_Req_Data : 0|64@1+ (1,0) [0|1] ""  VAS_R

BO_ 2550006213 KS_VAS_R_Resp: 8 VAS_R
 SG_ KS_VAS_R_Resp_Data : 0|64@1+ (1,0) [0|1] ""  Gateway,Gateway_PAG

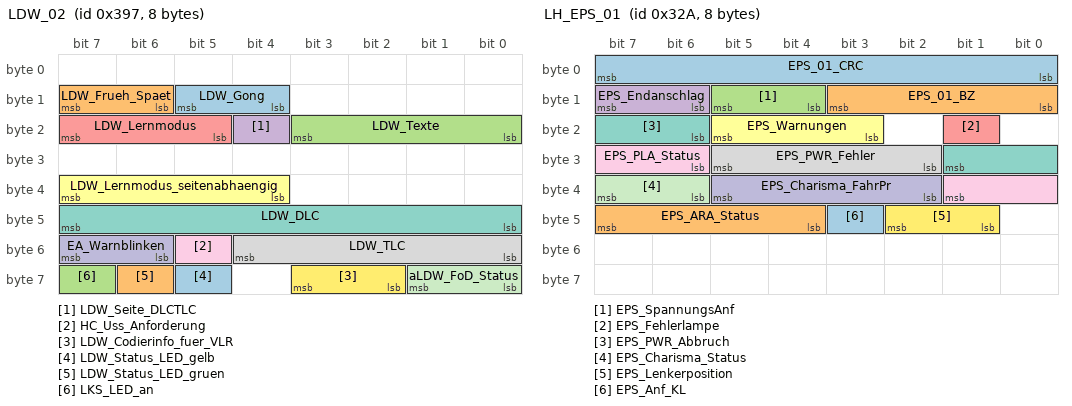
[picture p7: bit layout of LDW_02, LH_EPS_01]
BO_ 919 LDW_02: 8 Gateway
 SG_ LDW_Gong : 12|2@1+ (1.0,0.0) [0.0|3] ""  Vector__XXX
 SG_ LDW_Frueh_Spaet : 14|2@1+ (1.0,0.0) [0.0|3] ""  Vector__XXX
 SG_ LDW_Texte : 16|4@1+ (1.0,0.0) [0.0|15] ""  Vector__XXX
 SG_ LDW_Seite_DLCTLC : 20|1@1+ (1.0,0.0) [0.0|1] ""  Vector__XXX
 SG_ LDW_Lernmodus : 21|3@1+ (1.0,0.0) [0.0|7] ""  Vector__XXX
 SG_ LDW_Lernmodus_seitenabhaengig : 36|4@1+ (1.0,0.0) [0.0|15] ""  Vector__XXX
 SG_ LDW_DLC : 40|8@1+ (0.01,-1.25) [-1.25|1.25] "Unit_Meter"  Vector__XXX
 SG_ LDW_TLC : 48|5@1+ (0.1,0) [0.0|3.0] "Unit_Secon"  Vector__XXX
 SG_ HC_Uss_Anforderung : 53|1@1+ (1.0,0.0) [0.0|1] ""  BCM1
 SG_ EA_Warnblinken : 54|2@1+ (1.0,0.0) [0.0|3] ""  Vector__XXX
 SG_ aLDW_FoD_Status : 56|2@1+ (1.0,0.0) [0.0|3] ""  Vector__XXX
 SG_ LDW_Codierinfo_fuer_VLR : 58|2@1+ (1.0,0.0) [0.0|3] ""  Vector__XXX
 SG_ LDW_Status_LED_gelb : 61|1@1+ (1.0,0.0) [0.0|1] ""  Vector__XXX
 SG_ LDW_Status_LED_gruen : 62|1@1+ (1.0,0.0) [0.0|1] ""  Vector__XXX
 SG_ LKS_LED_an : 63|1@1+ (1.0,0.0) [0.0|1] ""  BCM1

BO_ 810 LH_EPS_01: 8 Gateway
 SG_ EPS_01_CRC : 0|8@1+ (1,0) [0|255] ""  BCM1
 SG_ EPS_01_BZ : 8|4@1+ (1,0) [0|15] ""  BCM1
 SG_ EPS_SpannungsAnf : 12|2@1+ (1.0,0.0) [0.0|3] ""  Vector__XXX
 SG_ EPS_Endanschlag : 14|2@1+ (1.0,0.0) [0.0|3] ""  Vector__XXX
 SG_ EPS_Fehlerlampe : 17|1@1+ (1.0,0.0) [0.0|1] ""  Vector__XXX
 SG_ EPS_Warnungen : 19|3@1+ (1.0,0.0) [0.0|7] ""  Vector__XXX
 SG_ EPS_PWR_Abbruch : 22|4@1+ (1.0,0.0) [0.0|15] ""  BCM1
 SG_ EPS_PWR_Fehler : 26|4@1+ (1.0,0.0) [0.0|15] ""  BCM1
 SG_ EPS_PLA_Status : 30|4@1+ (1.0,0.0) [0.0|15] ""  BCM1
 SG_ EPS_Charisma_FahrPr : 34|4@1+ (1.0,0.0) [0.0|15] ""  Vector__XXX
 SG_ EPS_Charisma_Status : 38|2@1+ (1.0,0.0) [0.0|3] ""  Vector__XXX
 SG_ EPS_Lenkerposition : 41|2@1+ (1.0,0.0) [0.0|3] ""  Vector__XXX
 SG_ EPS_Anf_KL : 43|1@1+ (1.0,0.0) [0.0|1] ""  Vector__XXX
 SG_ EPS_ARA_Status : 44|4@1+ (1.0,0.0) [0.0|15] ""  BCM1

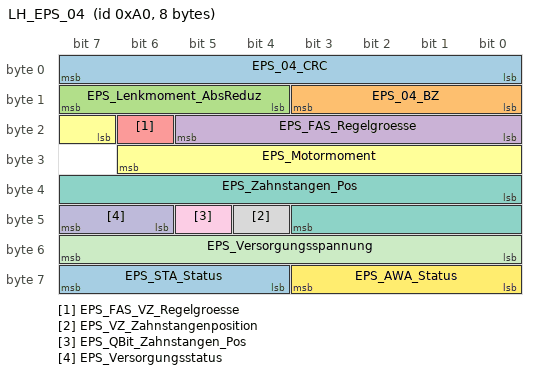
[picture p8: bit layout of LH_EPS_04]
BO_ 160 LH_EPS_04: 8 Gateway
 SG_ EPS_04_CRC : 0|8@1+ (1,0) [0|255] ""  BCM1
 SG_ EPS_04_BZ : 8|4@1+ (1,0) [0|15] ""  BCM1
 SG_ EPS_Lenkmoment_AbsReduz : 12|4@1+ (0.62,0.61) [0.61|8.05] "Unit_NewtoMeter"  BCM1
 SG_ EPS_FAS_Regelgroesse : 16|6@1+ (2,0) [0|100] "Unit_PerCent"  Vector__XXX
 SG_ EPS_FAS_VZ_Regelgroesse : 22|1@1+ (1.0,0.0) [0.0|1] ""  Vector__XXX
 SG_ EPS_Motormoment : 23|8@1+ (0.2,-16.2) [-16.0|16.0] "Unit_NewtoMeter"  Vector__XXX
 SG_ EPS_Zahnstangen_Pos : 32|12@1+ (0.02,0) [0.00|81.86] "Unit_MilliMeter"  BCM1
 SG_ EPS_VZ_Zahnstangenposition : 44|1@1+ (1.0,0.0) [0.0|1] ""  BCM1
 SG_ EPS_QBit_Zahnstangen_Pos : 45|1@1+ (1.0,0.0) [0.0|1] ""  BCM1
 SG_ EPS_Versorgungsstatus : 46|2@1+ (1.0,0.0) [0.0|3] ""  Vector__XXX
 SG_ EPS_Versorgungsspannung : 48|8@1+ (0.05,5.05) [5.05|17.70] "Unit_Volt"  Vector__XXX
 SG_ EPS_AWA_Status : 56|4@1+ (1.0,0.0) [0.0|15] ""  Vector__XXX
 SG_ EPS_STA_Status : 60|4@1+ (1.0,0.0) [0.0|15] ""  Vector__XXX

BO_ 981 Licht_Anf_01: 8 BCM1
 SG_ Licht_Anf_01_CRC : 0|8@1+ (1,0) [0|255] ""  Gateway,Gateway_PAG
 SG_ Licht_Anf_01_BZ : 8|4@1+ (1,0) [0|15] ""  Gateway,Gateway_PAG
 SG_ BCM1_Kurvenlicht_links_Anf : 12|1@1+ (1.0,0.0) [0.0|1] ""  Gateway,Gateway_PAG
 SG_ BCM1_Kurvenlicht_rechts_Anf : 13|1@1+ (1.0,0.0) [0.0|1] ""  Gateway,Gateway_PAG
 SG_ BCM1_Standlicht_Anf : 14|1@1+ (1.0,0.0) [0.0|1] ""  Gateway,Gateway_PAG
 SG_ BCM1_Abblendlicht_Anf : 15|1@1+ (1.0,0.0) [0.0|1] ""  Gateway,Gateway_PAG
 SG_ BCM1_Fernlicht_Anf : 16|1@1+ (1.0,0.0) [0.0|1] ""  Gateway,Gateway_PAG
 SG_ BCM1_Nebellicht_Anf : 17|1@1+ (1.0,0.0) [0.0|1] ""  Gateway,Gateway_PAG
 SG_ BCM1_Parklicht_li_Anf : 18|1@1+ (1.0,0.0) [0.0|1] ""  Gateway,Gateway_PAG
 SG_ BCM1_Parklicht_re_Anf : 19|1@1+ (1.0,0.0) [0.0|1] ""  Gateway,Gateway_PAG
 SG_ BCM1_Nebelschluss_Ahg_Anf : 20|1@1+ (1.0,0.0) [0.0|1] ""  Gateway,Gateway_PAG
 SG_ BCM1_Nebelschluss_Fzg_Anf : 21|1@1+ (1.0,0.0) [0.0|1] ""  Gateway,Gateway_PAG
 SG_ BCM1_Schlusslicht_Anf : 22|1@1+ (1.0,0.0) [0.0|1] ""  Gateway,Gateway_PAG
 SG_ BCM_Rueckfahrlicht_Anf : 23|1@1+ (1.0,0.0) [0.0|1] ""  Gateway,Gateway_PAG
 SG_ BCM1_Signaturlicht_Anf : 24|1@1+ (1.0,0.0) [0.0|1] ""  Gateway,Gateway_PAG
 SG_ BCM1_Umfeldleuchten_Anf : 25|1@1+ (1.0,0.0) [0.0|1] ""  Gateway,Gateway_PAG
 SG_ BCM1_Tagfahrlicht_Anf : 26|1@1+ (1.0,0.0) [0.0|1] ""  Gateway,Gateway_PAG
 SG_ BCM1_Regenlicht_Anf : 27|1@1+ (1.0,0.0) [0.0|1] ""  Gateway,Gateway_PAG
 SG_ BCM1_Autobahnlicht_Anf : 28|1@1+ (1.0,0.0) [0.0|1] ""  Gateway,Gateway_PAG
 SG_ BCM1_Touristen_Licht_Anf : 29|1@1+ (1.0,0.0) [0.0|1] ""  Gateway,Gateway_PAG
 SG_ BCM1_CH_aktiv : 30|1@1+ (1.0,0.0) [0.0|1] ""  Gateway,Gateway_PAG
 SG_ BCM1_LH_aktiv : 31|1@1+ (1.0,0.0) [0.0|1] ""  Gateway,Gateway_PAG
 SG_ BCM1_Gleitende_Leuchtw_Anf : 32|1@1+ (1.0,0.0) [0.0|1] ""  Gateway,Gateway_PAG
 SG_ BCM1_GLW_Fernlicht_Anf : 33|1@1+ (1.0,0.0) [0.0|1] ""  Gateway,Gateway_PAG
 SG_ BCM1_Adaptive_Lichtvert_Anf : 34|1@1+ (1.0,0.0) [0.0|1] ""  Gateway,Gateway_PAG
 SG_ BCM1_FoD_Sperrung_WiBli : 35|2@1+ (1.0,0.0) [0.0|3] ""  Gateway,Gateway_PAG
 SG_ BCM1_FOD_Sperrung_Animationen_HL : 37|2@1+ (1.0,0.0) [0.0|3] ""  Gateway,Gateway_PAG
 SG_ BCM1_Animationssperrung : 39|1@1+ (1.0,0.0) [0.0|1] ""  Gateway,Gateway_PAG
 SG_ BCM1_CH_LH_aktiv : 40|1@1+ (1.0,0.0) [0.0|1] ""  Gateway,Gateway_PAG
 SG_ BCM1_Allwetterlicht_Anf : 41|1@1+ (1.0,0.0) [0.0|1] ""  Gateway,Gateway_PAG
 SG_ BCM1_Schlusslicht_Signatur : 60|4@1+ (1.0,0.0) [0.0|15] ""  Gateway,Gateway_PAG

BO_ 982 Licht_hinten_01: 8 Gateway
 SG_ BCM2_Bremsl_durch_ECD : 5|1@1+ (1.0,0.0) [0.0|1] ""  Vector__XXX
 SG_ LH_Aussenlicht_def : 7|1@1+ (1.0,0.0) [0.0|1] ""  VAS_L,VAS_R
 SG_ LH_Standlicht_H_aktiv : 8|1@1+ (1.0,0.0) [0.0|1] ""  VAS_L,VAS_R
 SG_ LH_Parklicht_HL_aktiv : 9|1@1+ (1.0,0.0) [0.0|1] ""  VAS_L,VAS_R
 SG_ LH_Parklicht_HR_aktiv : 10|1@1+ (1.0,0.0) [0.0|1] ""  VAS_L,VAS_R
 SG_ LH_Bremslicht_H_aktiv : 11|1@1+ (1.0,0.0) [0.0|1] ""  VAS_L,VAS_R
 SG_ LH_Nebelschluss_aktiv : 12|1@1+ (1.0,0.0) [0.0|1] ""  BCM1,VAS_L,VAS_R
 SG_ LH_Rueckfahrlicht_aktiv : 13|1@1+ (1.0,0.0) [0.0|1] ""  VAS_L,VAS_R
 SG_ LH_Blinker_HL_akt : 14|1@1+ (1.0,0.0) [0.0|1] ""  VAS_L,VAS_R
 SG_ LH_Blinker_HR_akt : 15|1@1+ (1.0,0.0) [0.0|1] ""  VAS_L,VAS_R
 SG_ LH_Blinker_li_def : 16|1@1+ (1.0,0.0) [0.0|1] ""  VAS_L,VAS_R
 SG_ LH_Bremsl_li_def : 17|1@1+ (1.0,0.0) [0.0|1] ""  VAS_L,VAS_R
 SG_ LH_Schlusslicht_li_def : 18|1@1+ (1.0,0.0) [0.0|1] ""  VAS_L,VAS_R
 SG_ LH_Rueckf_li_def : 19|1@1+ (1.0,0.0) [0.0|1] ""  VAS_L,VAS_R
 SG_ LH_Nebel_li_def : 20|1@1+ (1.0,0.0) [0.0|1] ""  VAS_L,VAS_R
 SG_ LH_Schluss_Brems_Nebel_li_def : 21|1@1+ (1.0,0.0) [0.0|1] ""  VAS_L,VAS_R
 SG_ LH_Schluss_Brems_Nebel_re_def : 22|1@1+ (1.0,0.0) [0.0|1] ""  VAS_L,VAS_R
 SG_ LH_Zusatzschlussl_def : 23|1@1+ (1.0,0.0) [0.0|1] ""  VAS_L,VAS_R
 SG_ LH_Schluss_Brems_li_def : 24|1@1+ (1.0,0.0) [0.0|1] ""  VAS_L,VAS_R
 SG_ LH_Schluss_Nebel_li_def : 25|1@1+ (1.0,0.0) [0.0|1] ""  VAS_L,VAS_R
 SG_ LH_SL_BRL_BLK_li_def : 26|1@1+ (1.0,0.0) [0.0|1] ""  VAS_L,VAS_R
 SG_ LH_Brems_Blk_li_def : 27|1@1+ (1.0,0.0) [0.0|1] ""  VAS_L,VAS_R
 SG_ LH_Diag_Status_re_def : 28|1@1+ (1.0,0.0) [0.0|1] ""  Vector__XXX
 SG_ LH_Diag_Status_li_def : 29|1@1+ (1.0,0.0) [0.0|1] ""  Vector__XXX
 SG_ LH_Diag_LED_li_def : 30|1@1+ (1.0,0.0) [0.0|1] ""  Vector__XXX
 SG_ LH_Diag_LED_re_def : 31|1@1+ (1.0,0.0) [0.0|1] ""  Vector__XXX
 SG_ LH_Blinker_re_def : 32|1@1+ (1.0,0.0) [0.0|1] ""  VAS_L,VAS_R
 SG_ LH_Bremsl_re_def : 33|1@1+ (1.0,0.0) [0.0|1] ""  VAS_L,VAS_R
 SG_ LH_Schlusslicht_re_def : 34|1@1+ (1.0,0.0) [0.0|1] ""  VAS_L,VAS_R
 SG_ LH_Rueckf_re_def : 35|1@1+ (1.0,0.0) [0.0|1] ""  VAS_L,VAS_R
 SG_ LH_Nebel_re_def : 36|1@1+ (1.0,0.0) [0.0|1] ""  VAS_L,VAS_R
 SG_ LH_Schluss_Brems_mi_def : 37|1@1+ (1.0,0.0) [0.0|1] ""  VAS_L,VAS_R
 SG_ LH_Schluss_Brems_re_def : 40|1@1+ (1.0,0.0) [0.0|1] ""  VAS_L,VAS_R
 SG_ LH_Schluss_Nebel_re_def : 41|1@1+ (1.0,0.0) [0.0|1] ""  VAS_L,VAS_R
 SG_ LH_SL_BRL_BLK_re_def : 42|1@1+ (1.0,0.0) [0.0|1] ""  VAS_L,VAS_R
 SG_ LH_Brems_Blk_re_def : 43|1@1+ (1.0,0.0) [0.0|1] ""  VAS_L,VAS_R
 SG_ LH_Kennzl_def : 48|1@1+ (1.0,0.0) [0.0|1] ""  VAS_L,VAS_R
 SG_ LH_3_Bremsl_def : 49|1@1+ (1.0,0.0) [0.0|1] ""  VAS_L,VAS_R
 SG_ LH_Nebel_mi_def : 50|1@1+ (1.0,0.0) [0.0|1] ""  VAS_L,VAS_R
 SG_ LH_Rueckf_mi_def : 51|1@1+ (1.0,0.0) [0.0|1] ""  VAS_L,VAS_R
 SG_ LH_Schlusslicht_mi_def : 52|1@1+ (1.0,0.0) [0.0|1] ""  VAS_L,VAS_R
 SG_ LH_Bremsl_mi_def : 53|1@1+ (1.0,0.0) [0.0|1] ""  VAS_L,VAS_R
 SG_ LH_Bremsl_li_ges_def : 54|1@1+ (1.0,0.0) [0.0|1] ""  VAS_L,VAS_R
 SG_ LH_Bremsl_re_ges_def : 55|1@1+ (1.0,0.0) [0.0|1] ""  VAS_L,VAS_R

BO_TX_BU_ 2589283621 :BCM1,Klima_MSB;
BO_TX_BU_ 2463978701 :BCM1,Klima_MSB;
BO_TX_BU_ 1717 :BCM1,Klima_MSB;
BO_TX_BU_ 1513 :BCM1,Klima_MSB;
BO_TX_BU_ 1295 :BCM1,Klima_MSB;
BO_TX_BU_ 2589283474 :BCM1,Klima_MSB;
BO_TX_BU_ 2549088272 :Gateway,Gateway_PAG;
BO_TX_BU_ 779 :Gateway,Gateway_PAG;
BO_TX_BU_ 1719 :Gateway,Gateway_PAG;
BO_TX_BU_ 2549874958 :Gateway,Gateway_PAG;
BO_TX_BU_ 2549875140 :Gateway,Gateway_PAG;
BO_TX_BU_ 2549875141 :Gateway,Gateway_PAG;
BO_TX_BU_ 919 :Gateway,Gateway_PAG;
BO_TX_BU_ 810 :Gateway,Gateway_PAG;
BO_TX_BU_ 160 :Gateway,Gateway_PAG;
BO_TX_BU_ 982 :Gateway,Gateway_PAG;
CM_ BO_ 1712 "D4 und B8-PA

1:1 LIN-CAN Botschaft, nur bei Kl.15 EIN gesendet";
CM_ BO_ 1505 "ab MQB 7.3";
CM_ BO_ 1717 "ab D4 gültig  --  geänderter Wertebereich und Signalnamen
1:1 LIN-CAN Botschaft vom BCM1, nur bei Kl.15 EIN gesendet";
CM_ BO_ 779 "MQB";
CM_ BO_ 919 "ab MQB ohne CHK/BZ, LDW_SW_Warnung_links/rechts, KD-Fehler und mit Zyklus 100ms";
CM_ BO_ 810 "MQB: 50ms (für CAN-SG), geändertes Charisma, Entfall KD-Fehler";
CM_ BO_ 982 "MQB";

CM_ SG_ 2589283621 KL_ACmax_Aktiv "Funktion ACmax durch Kundeneingriff aktiviert";
CM_ SG_ 2589283621 KL_Defrost_Aktiv "Funktion Defrost durch Kundeneingriff aktiviert";
CM_ SG_ 2589283621 KL_ECO_Aktiv "Funktion Eco durch Kundeneingriff aktiviert";
CM_ SG_ 2589283621 KL_ECO_PRO_Aktiv "Funktion ECO-PRO durch Kundeneingriff aktiviert";
CM_ SG_ 2589283621 KL_Eps_Innen "mittlerer Wert der Klima Regelabweichung";
CM_ SG_ 2589283621 KL_FlHz_Soll_HL "Sollwertvorgabe für Flächenheizung hinten links";
CM_ SG_ 2589283621 KL_FlHz_Soll_HR "Sollwertvorgabe für Flächenheizung hinten rechts";
CM_ SG_ 2589283621 KL_FlHz_Soll_VL "Sollwertvorgabe für Flächenheizung vorne links";
CM_ SG_ 2589283621 KL_FlHz_Soll_VR "Sollwertvorgabe für Flächenheizung vorne rechts";
CM_ SG_ 2589283621 KL_Kundeneingriff_Geblaese "Manueller Kundeneingriff in die Geblaeseregelung";
CM_ SG_ 2589283621 KL_NV_Energie_Anf "Benötigte Energie (12V) für die Erweiterte Vorkonditionierung";
CM_ SG_ 2589283621 KL_QBit_Sonnenintensitaet "Gültigkeitsbit für Signal KL_Sonenintensität
Gesetzt bei Ersatzwert, Init oder Fehler.";
CM_ SG_ 2589283621 KL_Sonnenintensitaet "gemittelte eingestrahlte Leistung in W/m2";
CM_ SG_ 2589283621 KL_Status_Klimastil "Signal für aktuelles Programm des KBT";
CM_ SG_ 2589283621 KL_Thermischer_Bedarf "Temperierungsbedarf zur Innenraumklimatisierung";
CM_ SG_ 2589283621 KL_Umluft_Connect_status "Umluft Status zum Backend Server";
CM_ SG_ 2589283621 KL_ZR_Anforderung "Anforderung an MIB die Displays zu aktivieren";

CM_ SG_ 2463978701 KL_AC_Schalter_Prognose "Erwarteter Zustand des Klimakompressorwunschs bei einem Fahrprogramm-Wechsel";
CM_ SG_ 2463978701 KL_Leistungsreduktions_Hinweis "Signal zum Auslösen der Kombi-Meldung das bei einem Klima Defizit die Leistung der Klimatisierung reduziert wird.";
CM_ SG_ 2463978701 KL_Sollklimamodus_FPR_1 "Ziel Modus der Klimatisierung für ein definierbares Fahrprogramm.";
CM_ SG_ 2463978701 KL_Sollklimamodus_FPR_2 "Ziel Modus der Klimatisierung für ein definierbares Fahrprogramm.";
CM_ SG_ 2463978701 KL_Sollklimamodus_FPR_3 "Ziel Modus der Klimatisierung für ein definierbares Fahrprogramm.";
CM_ SG_ 2463978701 KL_Temp_Soll_hl_Prognose "Solltemperatur (Kundenwunsch) für die Prognose bei einem Fahrprogrammwechsel im BEV";
CM_ SG_ 2463978701 KL_Temp_Soll_hr_Prognose "Solltemperatur hinten rechts (Kundenwunsch) für die Prognose bei einem Fahrprogrammwechsel im BEV";
CM_ SG_ 2463978701 KL_Temp_Soll_vl_Prognose "Solltemperatur vorne links (Kundenwunsch) für die Prognose bei einem Fahrprogrammwechsel im BEV";
CM_ SG_ 2463978701 KL_Temp_Soll_vr_Prognose "Solltemperatur vorne rechts (Kundenwunsch) für die Prognose bei einem Fahrprogrammwechsel im BEV";

CM_ SG_ 2589283689 KL_FANonly_Aktiv "Zustand des Klimasystems befindet sich in FANonly (Neu BEV Funktion)";

CM_ SG_ 2589284046 KL_SH_LL1_PWM "Left Front Seat Backrest Heating PWM to Support Smart Seat climate

Flachenheizung: Leistungsvorgabe
0-100: PWM in Prozent (SpannungsKompensiert)
101: 100% PWM nicht Spannungskompensiert";
CM_ SG_ 2589284046 KL_SH_LS1_PWM "Left Front Seat Cushion Heating PWM to Support Smart Seat climate

Flachenheizung: Leistungsvorgabe
0-100: PWM in Prozent (SpannungsKompensiert)
101: 100% PWM nicht Spannungskompensiert";
CM_ SG_ 2589284046 KL_SH_RL1_PWM "Right Front Seat Backrest Heating PWM to Support Smart Seat climate

Flachenheizung: Leistungsvorgabe
0-100: PWM in Prozent (SpannungsKompensiert)
101: 100% PWM nicht Spannungskompensiert";
CM_ SG_ 2589284046 KL_SH_RS1_PWM "Right Front Seat Cushion Heating PWM to Support Smart Seat climate

Flachenheizung: Leistungsvorgabe
0-100: PWM in Prozent (SpannungsKompensiert)
101: 100% PWM nicht Spannungskompensiert";
CM_ SG_ 2589284046 KL_SL_LL1_PWM "Left Front Seat Backrest Ventilation Fan PWM to Support Smart Seat climate

Flachenheizung: Leistungsvorgabe
0-100: PWM in Prozent (SpannungsKompensiert)
101: 100% PWM nicht Spannungskompensiert";
CM_ SG_ 2589284046 KL_SL_LS1_PWM "Left Front Seat Cushion Ventilation Fan PWM to Support Smart Seat climate

Flachenheizung: Leistungsvorgabe
0-100: PWM in Prozent (SpannungsKompensiert)
101: 100% PWM nicht Spannungskompensiert";
CM_ SG_ 2589284046 KL_SL_RL1_PWM "Right Front Seat Backrest Ventilation Fan PWM to Support Smart Seat climate

Flachenheizung: Leistungsvorgabe
0-100: PWM in Prozent (SpannungsKompensiert)
101: 100% PWM nicht Spannungskompensiert";
CM_ SG_ 2589284046 KL_SL_RS1_PWM "Right Front Seat Cushion Ventilation Fan PWM to Support Smart Seat climate

Flachenheizung: Leistungsvorgabe
0-100: PWM in Prozent (SpannungsKompensiert)
101: 100% PWM nicht Spannungskompensiert";
CM_ SG_ 2589284046 KL_SSC_Status_VL "Left Front Smart Seat Climate Status";
CM_ SG_ 2589284046 KL_SSC_Status_VR "Right Front Smart Seat Climate Status";

CM_ SG_ 992 KL_Fehler_Fussraum_Klappen "Fehler in den Fußraumklappen werden gemeldet";
CM_ SG_ 992 KL_Fehler_Temp_Klappen "Fehler in den Temperaturklappen werden gemeldet";
CM_ SG_ 992 KL_Fehler_Temp_MA_Klappen "Fehler in den MA-Klappen werden gemeldet";
CM_ SG_ 992 KL_Fehler_Umluft "Status Umluftklappe";
CM_ SG_ 992 KL_Fond_Absperrventil "Absperrventil";
CM_ SG_ 992 KL_Fond_Fuss_Temp_hl "Fussraumtemperatur hinten links";
CM_ SG_ 992 KL_Fond_Fuss_Temp_hr "Fussraumtemperatur hinten rechts";
CM_ SG_ 992 KL_Fond_KD_Fehler "Status Kundendienstfehlerspeichereinträge

";
CM_ SG_ 992 KL_MA_Temp_hl "Mannanstroemer hinten links Temperatur";
CM_ SG_ 992 KL_MA_Temp_hr "Mannanstroemer hinten rechts Temperatur";
CM_ SG_ 992 KL_RAB "Risiko-Abschätzungs- und Bewertungs-Bit";
CM_ SG_ 992 KL_SH_Soll_hl "Einstellung Sitzheizung hinten links (0...6)";
CM_ SG_ 992 KL_SH_Soll_hr "Einstellung Sitzheizung hinten rechts (0...6)";
CM_ SG_ 992 KL_SIH_Takt_hl "Ein-Aus Taktung Sitzheizung hinten links";
CM_ SG_ 992 KL_SIH_Takt_hr "Ein-Aus Taktung Sitzheizung hinten rechts";
CM_ SG_ 992 KL_SL_Soll_hl "Einstellung Sitzlüftung hinten links (0...6)";
CM_ SG_ 992 KL_SL_Soll_hr "Einstellung Sitzlüftung hinten rechts (0...6)";

CM_ SG_ 1712 FS_Luftfeuchte_rel "gemessene relative Luftfeuchte";
CM_ SG_ 1712 FS_ResponseError "siehe LIN2.0-Specification
(Darf nicht über ein Fehlergueltigkeitsbit abgesichtert werden!)";
CM_ SG_ 1712 FS_Taupunkt "berechneter Taupunkt";
CM_ SG_ 1712 FS_Temp_Scheibe "gemessene Frontscheibentemperatur";
CM_ SG_ 1712 FS_Temp_Sensor "gemessene Sensortemperatur";

CM_ SG_ 1505 BCM1_Aussen_Temp_ungef "ungefilterter Wert des Aussentemperatursensors
";
CM_ SG_ 1505 BCM1_FStatus_Aussentemp_ungef "Fehlerstatus für Aussentemperatur (Kombianzeige)";
CM_ SG_ 1505 BCM1_Kompressorstrom_ist "IST-Strom vom Klima-Kompressor";
CM_ SG_ 1505 BCM1_OBD_FStatus_ATemp "Fehlerstatus Umgebungstemperatursensor (OBD relevanter Sensor)
";
CM_ SG_ 1505 BCM1_PTC_stufig_Status "Status des BCM1-Heizverbrauchers PTC (stufig)";
CM_ SG_ 1505 BCM_Heizungsabsperrventil_Status "Das Signal beschreibt den Zustand des Heizungsabsperrventils, welches als Portexpander vom BCM1 elektrisch angesteuert wird.";
CM_ SG_ 1505 BCM_Heizungspumpe_Status "Das Signal beschreibt den Zustand der Heizungspumpe, welche als Portexpander vom BCM1 elektrisch angesteuert wird.";
CM_ SG_ 1505 BCM_Kompressorkupplung_Status "Das Signal beschreibt den Zustand der Klimakompressorkupplung, welche als Portexpander vom BCM1 elektrisch angesteuert wird.";

CM_ SG_ 1717 FSA_Err_Defekt_HumSens_TNCTOC "OBD TestNotCompletedThisOperationCycle nach LIN LAH für Feuchteelement, testNotCompletedThisOperationCycle (TNCTOC)";
CM_ SG_ 1717 FSA_Err_Defekt_HumSense_TF "OBD TestFailed Flag, Statusbotschaft für Feuchtesensor außen, testFailed (TF)";
CM_ SG_ 1717 FSA_Err_Defekt_Tsens_TF "OBD TestFailed Flag, Statusbotschaft für diden Feuchtesensor, testFailed (TF)";
CM_ SG_ 1717 FSA_Err_RAMROM_Check_TF "OBD TestFailed Flag, Statusbotschaft für den Feuchtesensor, testFailed (TF)";
CM_ SG_ 1717 FSA_Err_RAMROM_Check_TNCTOC "Signal meldet den Status der Diagnosen nach OBD LIN-LAH, testNotCompletedThisOperationCycle (TNCTOC)";
CM_ SG_ 1717 FSA_Err_Ueberspannung_TF "OBD TestFailed Flag, Statusbotschaft für den Feuchtesensor Außen, testFailed (TF)";
CM_ SG_ 1717 FSA_Err_Unterspannung_TF "OBD TestFailed Flag, Statusbotschaft für den Feuchtesensor, testFailed (TF)";
CM_ SG_ 1717 FSA_ErrMemState "OBD Signal statusbotschaft für den Feuchtesensor außen";
CM_ SG_ 1717 FSA_HW "Hardwarestand";
CM_ SG_ 1717 FSA_Lokal_Bus_elektr_Fehler "Bit wird gesetzt, wenn fuer lokaler Datenbus elektr. Fehler eingetragen wird";
CM_ SG_ 1717 FSA_Lokal_Bus_Unterbrechung "Bit wird gesetzt, wenn fuer lokaler Datenbus DTC wegen Unterbrechung eingetragen wird";
CM_ SG_ 1717 FSA_Luftfeuchte_rel "Maximaler Feuchtebereich bis 126% für theoretisch errechnete Feuchtewerte des Sensors. Signalwerte >100% bedeuten  rel. Feuchte = 100%";
CM_ SG_ 1717 FSA_Luftfeuchte_TF "OBD TestFailed Flag, Statusbotschaft für den Feuchtesensor, testFailed (TF)";
CM_ SG_ 1717 FSA_Luftfeuchte_TNCTOC "Signal meldet den Status der Diagnosen nach OBD LIN-LAH, testNotCompletedThisOperationCycle (TNCTOC)";
CM_ SG_ 1717 FSA_ResponseError "siehe LIN2.0-Specification
(Darf nicht über ein Fehlergueltigkeitsbit abgesichtert werden!)";
CM_ SG_ 1717 FSA_Sensorheizung_Status "Status der Heizung im Feuchteelement (z.B. SHT10).
0 (=inaktiv) auch bei nicht verbaut";
CM_ SG_ 1717 FSA_SW "Softwarestand";
CM_ SG_ 1717 FSA_Taupunkt "'Init' falls nicht verbaut";
CM_ SG_ 1717 FSA_Temp_Luft "gemessene Temperatur im Luftstrom (z.B. NTC am Sensor)
'Init' falls nicht verbaut
(+61°C bedeutet: Temp_Luft > 60,9°C !)";
CM_ SG_ 1717 FSA_Timeout "Bit wird gesetzt, wenn Time-Out DTC eingetragen wird";

CM_ SG_ 1513 AAU_Geblaese "Ansteuergrad des Gebläses";
CM_ SG_ 1513 DS_Kaeltemittel_P "Drucksensor Kältemittel Druck, das Signal wird bei Kl.15 AUS mit dem letzten empfangenen Wert gesendet";
CM_ SG_ 1513 DS_Status "Status des Drucksensors (= LIN-Slave BCM1);
bei Kl.15 AUS wird für 4s noch der letzte Wert gesendet, danach wird das Signal mit dem Wert 3 (= Fehler) gesendet";
CM_ SG_ 1513 ION_Status "Status Hochspannung Ionisator";
CM_ SG_ 1513 ION_Status_LED "Status Funktions LED";
CM_ SG_ 1513 ION_Status_Taster "Status Kundenwunsch (Bedientaster) Ionisator";

CM_ SG_ 1295 KL_Heizbedarf "Bedarf an Heizmenge für Innenraumklimatisierung";
CM_ SG_ 1295 KL_Heizenergie_instat_pred "Erwartete thermische Energie für den instationären Heizbetrieb bis zum Übergang in den stationären Betrieb";
CM_ SG_ 1295 KL_Heizleistg_stat_erw "Erwartete thermische Heizleistungsaufnahme für den stationären Klimabetrieb bei aktuellen klimatischen Bedingungen";
CM_ SG_ 1295 KL_Kuehlbedarf "Bedarf an Kühlmenge für Innenraumklimatisierung";
CM_ SG_ 1295 KL_Kuehlenergie_instat_pred "Erwartete thermische Energie für den instationären Kühlbetrieb bis zum Übergang in den stationären Betrieb";
CM_ SG_ 1295 KL_Kuehlleistg_stat_erw "Erwartete thermische Kühlleistungsaufnahme für den stationären Klimabetrieb bei aktuellen klimatischen Bedingungen";
CM_ SG_ 1295 KL_Leistungspriorisierung "Priorisierungsvorgaben";
CM_ SG_ 1295 KL_PTC_ein "PTC Aus/Ein";
CM_ SG_ 1295 KL_Verdampfertemperatur "Istwert der Verdampfertemperatur";

CM_ SG_ 2589283474 KL_Eps_Innen "mittlerer Wert der Klima Regelabweichung";
CM_ SG_ 2589283474 KL_MMTR "Signal zum TME-SG zur Aktivierung der Funktion Make me track ready";
CM_ SG_ 2589283474 KL_MMTR_Status "Status der Funktion Make me track ready";
CM_ SG_ 2589283474 KL_Temp_vor_Verdampfer "Ist Lufttemperatur vor Verdampfer";
CM_ SG_ 2589283474 KL_Tempklappe_Fond_li "Sollwert der Temperaturklappe Fond links";
CM_ SG_ 2589283474 KL_Tempklappe_Fond_re "Sollwert der Temperaturklappe Fond rechts";

CM_ SG_ 2549088270 BCM1_Abschaltstufe "Funktionseinschränkung aufgrund aktiver Abschaltstufe";
CM_ SG_ 2549088270 BCM1_KD_Fehler "Bei gesetztem Bit ist mindestens ein Kundendienstfehler eingetragen";
CM_ SG_ 2549088270 BCM1_KompSchutz "Funktionseinschränkung aufgrund Komponentenschutz aktiv";
CM_ SG_ 2549088270 BCM1_Nachlauftyp "Abgebildet wird die von der Hardware vorgegebene Möglichkeit, die Kommunikation nach Klemme 15 = AUS aufrecht zu erhalten. Es wird ein Init-Wert gesendet.";
CM_ SG_ 2549088270 BCM1_SNI "Das Signal beinhaltet den Source Node Identifier (Knotenadresse, die auch in der Abbildungsvorschrift zur CAN-ID für die NM-High Botschaft verwendet wird).";
CM_ SG_ 2549088270 BCM1_Transport_Mode "Funktionseinschränkung aufgrund aktivem Transport Mode und/oder Transport Schutz";
CM_ SG_ 2549088270 KN_BCM1_BusKnockOutTimer "Ausgabe des BusKnockOut-Timer";
CM_ SG_ 2549088270 NM_BCM1_Lokalaktiv "Zeigt an ob das SG nach Klemme15 AUS und nach entsprechender MAX Aktivzeit noch aktiv war.";
CM_ SG_ 2549088270 NM_BCM1_Subsystemaktiv "Zeigt an ob ein Subsystem des SGs nach Klemme15 AUS und nach entsprechender MAX Aktivzeit noch aktiv war";
CM_ SG_ 2549088270 NM_BCM1_Wakeup "enthält die Weckursache; stehen mehrere Weckursachen parallel an, dann muss der kleinste Wert übertragen werden";

CM_ SG_ 2549088272 Gateway_Abschaltstufe "Funktionseinschränkung aufgrund aktiver Abschaltstufe";
CM_ SG_ 2549088272 Gateway_KompSchutz "Funktionseinschränkung aufgrund Komponentenschutz aktiv";
CM_ SG_ 2549088272 Gateway_Matrix_Generation "Signal gibt an welche Matrix-Generation umgesetzt ist";
CM_ SG_ 2549088272 Gateway_Matrix_Version "Signal gibt an welche Matrix-Version des Baukasten umgesetzt ist.
z.B. V.08.xx, das Signal gibt den Wert für xx an";
CM_ SG_ 2549088272 Gateway_Nachlauftyp "Abgebildet wird die von der Hardware vorgegebene Möglichkeit, die Kommunikation nach Klemme 15 = AUS aufrecht zu erhalten. Es wird ein Init-Wert gesendet.";
CM_ SG_ 2549088272 Gateway_SNI "Das Signal beinhaltet den Source Node Identifier (Knotenadresse, die auch in der Abbildungsvorschrift zur CAN-ID für die NM-High Botschaft verwendet wird).";
CM_ SG_ 2549088272 Gateway_Transport_Mode "Funktionseinschränkung aufgrund aktivem Transport Mode und/oder Transport Schutz";
CM_ SG_ 2549088272 GW_KD_Fehler "Kundendienstfehlerbit Gateway zur Anzeige eines im Gateway abgelegten Fehlerspeichereintrages.";
CM_ SG_ 2549088272 NM_Gateway_Lokalaktiv "Zeigt an ob das SG nach Klemme15 AUS und nach entsprechender MAX Aktivzeit noch aktiv war.";
CM_ SG_ 2549088272 NM_Gateway_Subsystemaktiv "Zeigt an ob ein Subsystem des SGs nach Klemme15 AUS und nach entsprechender MAX Aktivzeit noch aktiv war";
CM_ SG_ 2549088272 NM_Gateway_Wakeup "enthält die Weckursache; stehen mehrere Weckursachen parallel an, dann muss der kleinste Wert übertragen werden";

CM_ SG_ 2549088326 KL_KD_Fehler "Status Kundendienstfehlerspeichereinträge

";
CM_ SG_ 2549088326 Klima_Abschaltstufe "Funktionseinschränkung aufgrund aktiver Abschaltstufe";
CM_ SG_ 2549088326 Klima_KompSchutz "Funktionseinschränkung aufgrund Komponentenschutz aktiv";
CM_ SG_ 2549088326 Klima_Nachlauftyp "Abgebildet wird die von der Hardware vorgegebene Möglichkeit, die Kommunikation nach Klemme 15 = AUS aufrecht zu erhalten. Es wird ein Init-Wert gesendet.
0 = Kommunikation nur bei KL15=EIN (kein Nachlauf, nicht weckfähig)
1 = Kommunikation nach KL15=AU";
CM_ SG_ 2549088326 Klima_SNI "Das Signal beinhaltet den Source Node Identifier (Knotenadresse, die auch in der Abbildungsvorschrift zur CAN-ID für die NM-High Botschaft verwendet wird).";
CM_ SG_ 2549088326 Klima_Transport_Mode "Funktionseinschränkung aufgrund aktivem Transport Mode und/oder Transport Schutz";
CM_ SG_ 2549088326 KN_Klima_BusKnockOut "Ausgabe des BusKnockout-Status in der Knotenbotschaft";
CM_ SG_ 2549088326 KN_Klima_BusKnockOutTimer "Ausgabe des BusKnockOut-Timer in der Knotenbotschaft";
CM_ SG_ 2549088326 KN_Klima_ECUKnockOut "Ausgabe des ECUKnockout-Status in der Knotenbotschaft";
CM_ SG_ 2549088326 KN_Klima_ECUKnockOutTimer "Ausgabe des ECUKnockOut-Timer in der Knotenbotschaft";
CM_ SG_ 2549088326 NM_Klima_Lokalaktiv "Zeigt an ob das SG nach Klemme15 AUS und nach entsprechender MAX Aktivzeit noch aktiv war";
CM_ SG_ 2549088326 NM_Klima_Subsystemaktiv "Zeigt an ob ein Subsystem des SGs nach Klemme15 AUS und nach entsprechender MAX Aktivzeit noch aktiv war";
CM_ SG_ 2549088326 NM_Klima_Wakeup "enthält die Weckursache; stehen mehrere Weckursachen parallel an, dann muss der kleinste Wert übertragen werden";

CM_ SG_ 2549088345 KN_Lift_BusKnockOut "Ausgabe des BusKnockout-Status in der Knotenbotschaft";
CM_ SG_ 2549088345 KN_Lift_BusKnockOutTimer "Ausgabe des BusKnockOut-Timer in der Knotenbotschaft";
CM_ SG_ 2549088345 KN_Lift_ECUKnockOut "Ausgabe des ECUKnockout-Status in der Knotenbotschaft";
CM_ SG_ 2549088345 KN_Lift_ECUKnockOutTimer "Ausgabe des ECUKnockOut-Timer in der Knotenbotschaft";
CM_ SG_ 2549088345 Lift_Abschaltstufe "Funktionseinschränkung aufgrund aktiver Abschaltstufe";
CM_ SG_ 2549088345 Lift_KompSchutz "Funktionseinschränkung aufgrund Komponentenschutz aktiv";
CM_ SG_ 2549088345 Lift_Lokalaktiv "Zeigt an ob das SG nach Klemme15 AUS und nach entsprechender MAX Aktivzeit noch aktiv war";
CM_ SG_ 2549088345 Lift_Nachlauftyp "Abgebildet wird die von der Hardware vorgegebene Möglichkeit, die Kommunikation nach Klemme 15 = AUS aufrecht zu erhalten. Es wird ein Init-Wert gesendet.
0 = Kommunikation nur bei KL15=EIN (kein Nachlauf, nicht weckfähig)
1 = Kommunikation nach KL15=AU";
CM_ SG_ 2549088345 Lift_SNI "Das Signal beinhaltet den Source Node Identifier (Knotenadresse, die auch in der Abbildungsvorschrift zur CAN-ID für die NM-High Botschaft verwendet wird).";
CM_ SG_ 2549088345 Lift_Subsystemaktiv "Zeigt an ob ein Subsystem des SGs nach Klemme15 AUS und nach entsprechender MAX Aktivzeit noch aktiv war";
CM_ SG_ 2549088345 Lift_Transport_Mode "Funktionseinschränkung aufgrund aktivem Transport Mode und/oder Transport Schutz";
CM_ SG_ 2549088345 NM_Lift_Wakeup "enthält die Weckursache; stehen mehrere Weckursachen parallel an, dann muss der kleinste Wert übertragen werden";

CM_ SG_ 2549088452 KN_VAS_L_BusKnockOut "Ausgabe des BusKnockout-Status";
CM_ SG_ 2549088452 KN_VAS_L_BusKnockOutTimer "Ausgabe des BusKnockOut-Timer";
CM_ SG_ 2549088452 KN_VAS_L_ECUKnockOut "Ausgabe des ECUKnockout-Status";
CM_ SG_ 2549088452 KN_VAS_L_ECUKnockOutTimer "Ausgabe des ECUKnockOut-Timer";
CM_ SG_ 2549088452 NM_VAS_L_Lokalaktiv "Zeigt an ob das SG nach Klemme15 AUS und nach entsprechender MAX Aktivzeit noch aktiv war.";
CM_ SG_ 2549088452 NM_VAS_L_Wakeup "enthält die Weckursache; stehen mehrere Weckursachen parallel an, dann muss der kleinste Wert übertragen werden";
CM_ SG_ 2549088452 VAS_L_Abschaltstufe "Funktionseinschränkung aufgrund aktiver Abschaltstufe";
CM_ SG_ 2549088452 VAS_L_KD_Fehler "Bei gesetztem Bit ist mindestens ein Kundendienstfehler eingetragen";
CM_ SG_ 2549088452 VAS_L_KompSchutz "Signal wird gesetzt wenn Komponentenschutz (KS) im Steuergerät aktiv ist.";
CM_ SG_ 2549088452 VAS_L_Nachlauftyp "Abgebildet wird die von der Hardware vorgegebene Möglichkeit, die Kommunikation nach Klemme 15 = AUS aufrecht zu erhalten. Es wird ein Init-Wert gesendet.";
CM_ SG_ 2549088452 VAS_L_SNI "Das Signal beinhaltet den Source Node Identifier (Knotenadresse, die auch in der Abbildungsvorschrift zur CAN-ID für die NM-High Botschaft verwendet wird).";
CM_ SG_ 2549088452 VAS_L_Subsystemaktiv "Zeigt an ob ein Subsystem des SGs nach Klemme15 AUS und nach entsprechender MAX Aktivzeit noch aktiv war";
CM_ SG_ 2549088452 VAS_L_Transport_Mode "Funktionseinschränkung aufgrund aktivem Transport Mode und/oder Transport Schutz";

CM_ SG_ 2549088453 KN_VAS_R_BusKnockOut "Ausgabe des BusKnockout-Status";
CM_ SG_ 2549088453 KN_VAS_R_BusKnockOutTimer "Ausgabe des BusKnockOut-Timer";
CM_ SG_ 2549088453 KN_VAS_R_ECUKnockOut "Ausgabe des ECUKnockout-Status";
CM_ SG_ 2549088453 KN_VAS_R_ECUKnockOutTimer "Ausgabe des ECUKnockOut-Timer";
CM_ SG_ 2549088453 NM_VAS_R_Lokalaktiv "Zeigt an ob das SG nach Klemme15 AUS und nach entsprechender MAX Aktivzeit noch aktiv war.";
CM_ SG_ 2549088453 NM_VAS_R_Wakeup "enthält die Weckursache; stehen mehrere Weckursachen parallel an, dann muss der kleinste Wert übertragen werden";
CM_ SG_ 2549088453 VAS_R_Abschaltstufe "Funktionseinschränkung aufgrund aktiver Abschaltstufe";
CM_ SG_ 2549088453 VAS_R_KD_Fehler "Bei gesetztem Bit ist mindestens ein Kundendienstfehler eingetragen";
CM_ SG_ 2549088453 VAS_R_KompSchutz "Signal wird gesetzt wenn Komponentenschutz (KS) im Steuergerät aktiv ist.";
CM_ SG_ 2549088453 VAS_R_Nachlauftyp "Abgebildet wird die von der Hardware vorgegebene Möglichkeit, die Kommunikation nach Klemme 15 = AUS aufrecht zu erhalten. Es wird ein Init-Wert gesendet.";
CM_ SG_ 2549088453 VAS_R_SNI "Das Signal beinhaltet den Source Node Identifier (Knotenadresse, die auch in der Abbildungsvorschrift zur CAN-ID für die NM-High Botschaft verwendet wird).";
CM_ SG_ 2549088453 VAS_R_Subsystemaktiv "Zeigt an ob ein Subsystem des SGs nach Klemme15 AUS und nach entsprechender MAX Aktivzeit noch aktiv war";
CM_ SG_ 2549088453 VAS_R_Transport_Mode "Funktionseinschränkung aufgrund aktivem Transport Mode und/oder Transport Schutz";

CM_ SG_ 779 KBI_ABS_Lampe "ABS-Sicherheits-Lampe wurde eingeschaltet.";
CM_ SG_ 779 KBI_Airbag_Lampe "Airbag Sicherheits-Lampe wurde eingeschaltet ";
CM_ SG_ 779 KBI_angez_Geschw "Im Tacho angezeigte Geschwindigkeit inklusive der Voreilung

";
CM_ SG_ 779 KBI_Anzeigefehler_NV "Über dieses Signal teilt das Kombiinstrument dem Nightvision-Steuergerät mit, dass ein Fehler vom Kombiinstrument diagnostiziert wurde, der zur Abschaltung der Nightvision-Funktion führen muss.";
CM_ SG_ 779 KBI_Anzeigefehler_SWA "Signal bezieht sich nur auf die SWA-Lampe, Vorhalt für Kombis mit SWA-Lampe. ";
CM_ SG_ 779 KBI_Anzeigestatus_ACC "Status der ACC-Anzeige im nicht permanenten Displaybereich";
CM_ SG_ 779 KBI_Anzeigestatus_GRA "Anzeigestatus der GRA High Wunschgeschwindigkeitsanzeige im Kombiinstrument.
Bei VW bedeutet 'nicht vorhanden' GRA-low fähig (LED immer verbaut).
0 = nicht vorhanden
1 = Wunschgeschwindigkeits-Anzeigemöglichkeit vorhanden
2 = reserviert
3 = Fehler (B";
CM_ SG_ 779 KBI_Anzeigestatus_LIM "Anzeigestatus der Speedlimiter Wunschgeschwindigkeitsanzeige im Kombiinstrument (permanenter Anzeigebereich)
0 = nicht vorhanden
1 = Wunschgeschwindigkeits-Anzeigemöglichkeit vorhanden
2 = reserviert
3 = Fehler (Botschaftsüberwachung, Timeout, Akustik";
CM_ SG_ 779 KBI_ARA_in_Anzeige "Anzeige von ARA im Kombi aktiv";
CM_ SG_ 779 KBI_Bestaetigung_ESP_Off "ESP Off Bestätigung vom Kombi ans ESC";
CM_ SG_ 779 KBI_BKL_Lampe "Sicherheits-Lampe Bremskontrolle wurde eingeschaltet;
";
CM_ SG_ 779 KBI_Einheit_Tacho "Information, ob es sich um Meilen- oder Kmh-Kombi handelt, Einheit des Tachos entspricht dem Zifferblatt, Grösse ist nicht veränderlich";
CM_ SG_ 779 KBI_ESP_Lampe "ESP-Sicherheits-Lampe wurde eingeschaltet ";
CM_ SG_ 779 KBI_Fehler_Anzeige_ACC "Rückmeldung an ACC, dass mindestens eine der ACC-relevanten Anzeigen -rote Fahrerübernahme, Mitteldisplay, Gong - fehlerhaft sind.";
CM_ SG_ 779 KBI_GRA_Hauptschalter "Hauptschalter der Fahrerassistenzsysteme basierend auf dem FAS-Menu im Kombi.";
CM_ SG_ 779 KBI_Handbremse "Handbremsen-Information vom Kombi.
Das Signal bezieht sich ausschließlich auf den Zustand der konventionellen Handbremse.";
CM_ SG_ 779 KBI_im_Stellgliedtest "Kombi im Stellgliedtest, Signal muss eingelesen werden, um Fehlfunktion aufgrund der Bewegung der Stellglieder (Drehzahlmesser, Tacho) des Kombis zu verhindern";
CM_ SG_ 779 KBI_Konsistenz_ACC "Rückmeldung an ACC, dass die Botschaften zur Ansteuerung von Anzeigen nicht bzw. nicht konsistent empfangen wurden (Timeout-, BZ-, CHK- und DLC-Fehler)                                                                                                        ";
CM_ SG_ 779 KBI_Lenkung_Lampe "Sicherheits-Lampe der Lenkung (Lenkhilfe EPS, Audi-Dynamic-Steering ...) wurde eingeschaltet.

0x0 = Lenkungs-Lampe aus
0x1 = Lenkungs-Lampe ein";
CM_ SG_ 779 KBI_MFA_v_Einheit_01 "Einheit der Geschwindigkeit, die vom Fahrer im Car-Menü gewählt wurde. Veränderliche Grösse, im Gegensatz zur Einheit des Tachokranzes.";
CM_ SG_ 779 KBI_NV_in_Anzeige "Das Bit gibt dem NV die Information, ob NV-Bild im Kombi in der Anzeige ist. (Information ist notwendig um Kontrasverstellungen nur dann zuzulassen, wenn der Fahrer das Feedback über das  Kombidisplay bekommt.)";
CM_ SG_ 779 KBI_PLA_in_Anzeige "Das Signal wird als aktive Rückmeldung genutzt, ob die Info des PLA im Kombi angezeigt wird. Wenn nach Anforderung des Displays das Signal zweimal auf 0 ist, wird der Parkvorgang abgebrochen.
Ein Kombi, dass PLA Anzeige nicht unterstützt, schickt dauerha";
CM_ SG_ 779 KBI_SILA_gueltig "Rückmeldeinformation (Bit 1-6) ist gültig";
CM_ SG_ 779 KBI_Systemstatus "Signalisiert erkannte FuSi-relevante Fehler im Kombi
(keinen Ausfall der Akustik oder des Displays)";
CM_ SG_ 779 KBI_Tankwarnung "Fahrer wird gewarnt, dass er den Reservebereich erreicht hat. Fzg.spezifische Warnschwelle";
CM_ SG_ 779 KBI_Tankwarnung_ungueltig "Validiert den Inhalt des Signales KBI_Tankwarnung";
CM_ SG_ 779 KBI_Taster_Fahrwerk "Betätigung Taster 'Fahrwerk' im Kombi";
CM_ SG_ 779 KBI_Taster_Lift "Betätigung Taster 'Lift' im Kombi J1 zur Verarbeitung im Porsche EFP Steuergerät";
CM_ SG_ 779 KBI_V_Digital "Ausgabe der im Kombi angezeigten digitalen Geschwindigkeit.

Einheit ist im KBI_MFA_v_Einheit_01 definiert";
CM_ SG_ 779 KBI_Vorglueh_System_Lampe "Rückmeldung der Vorglühlampe bzw. Motor Systemlampe (MO_Systemlampe) an den Motor (bei Diesel und Otto!). Hardwaremässig gleiche LED im Kombi (EPC- oder Glühwendel), Unterscheidung nur über Ziffernblatt.";
CM_ SG_ 779 Kombi_01_BZ "Botschaft asynchron geroutet. Zählerwert kann springen.";

CM_ SG_ 1719 KBI_aktive_Laengsfunktion "Auswahl, der vom Fahrer gewünschten Laengsregelfunktion";
CM_ SG_ 1719 KBI_FoD_PopUP_Quittiert "Angezeigte FoD-Warnung im Kombi wurde vom Fahrer quittiert; 
Signal wird für die Dauer von 2 Sekunden gesendet";
CM_ SG_ 1719 KBI_FStatus_Tank "Signal wird gesetzt:

a) Während der Fehlerentprellzeit (20 s Entprellung)

b) Bei erkanntem Fehler wird der Tankinhalt während der laufenden KL15-Phase über den 
    Verbrauch zurückgerechnet. In dieser Zeit ist das Bit ebenfalls gesetzt. Nach einem";
CM_ SG_ 1719 KBI_GRA_im_ACC "Gibt den vom Fahrer ausgewählten Modus (ACC oder GRA_im_ACC) an.";
CM_ SG_ 1719 KBI_Inhalt_Tank "Restmenge 2 bzw. 2,5l nicht auflösbar

";
CM_ SG_ 1719 KBI_Kilometerstand "Fehler wird ausgegeben, falls Kilometerstand nicht restaurierbar
";
CM_ SG_ 1719 KBI_LVDS_Lock "Dient zur Synchronisation der Anzeige zwischen Kombi und ZR";
CM_ SG_ 1719 KBI_Oelwechsel_durchgefuehrt "Nach einen Ölwechsel (Service) ist die Ethanol Warmfahrwarnung zu unterdrücken.";
CM_ SG_ 1719 KBI_QBit_Aussen_Temp_gef "0x0 = gültiger Wert
0x1 = Ersatz-, Init- oder Fehlerwert";
CM_ SG_ 1719 KBI_RDK_Kalibrier_Anf "Bei gesetztem Bit soll die RDK die aktuellen Istdrücke zu Solldrücken übernehmen (nur bei Nichtverbau einer Headunit erforderlich).";
CM_ SG_ 1719 KBI_Reserve_Warnung_Sek "Signalisiert die Reservewarnung für die Energiespeicher CNG, LPG, HV-Batterie.
Fahrer wird gewarnt, dass er den Reservebereich erreicht hat. Fzg.spezifische Warnschwelle.";
CM_ SG_ 1719 KBI_Standzeit_02 "Zähler welcher die Standzeit des Motors wiedergibt.
Das Signal beschreibt den Anteil der Motor-Standzeit zwischen Zündung aus und nächstem Motorstart.";
CM_ SG_ 1719 KBI_TA_gewaehlt_Fahrer "Rueckmeldung, dass der TA vom Fahrer gewaehlt wurde";

CM_ SG_ 2549874958 KS_BCM1_Req_Data "Komponentenschutz (Funktion 01h). Request mit NA des Slaves.";

CM_ SG_ 2550006030 KS_BCM1_Resp_Data "Komponentenschutz (Funktion 01h). Response mit eigener NA.";

CM_ SG_ 2549875140 KS_VAS_L_Req_Data "Komponentenschutz (Funktion 01h). Request mit NA des Slaves.";

CM_ SG_ 2550006212 KS_VAS_L_Resp_Data "Komponentenschutz (Funktion 01h). Response mit eigener NA.";

CM_ SG_ 2549875141 KS_VAS_R_Req_Data "Komponentenschutz (Funktion 01h). Request mit NA des Slaves.";

CM_ SG_ 2550006213 KS_VAS_R_Resp_Data "Komponentenschutz (Funktion 01h). Response mit eigener NA.";

CM_ SG_ 919 aLDW_FoD_Status "Im CBEV wird aLDW durch FoD geschützt sein und so reicht für Kombi und HUd die PR/Zieldatencontainer basierte Codierung nicht mehr aus.

Aus diesem Grund brauch wir ein separates Signal, dass uns den Freischaltezustand mitteilt.";
CM_ SG_ 919 EA_Warnblinken "Anforderung Warnblinken durch Funktion Emergency Alert";
CM_ SG_ 919 HC_Uss_Anforderung "Ansteuerung der vorderen PLA (VLS, VRS) und APS Sensoren (VL, VR)
0 = Ultraschallsensoren Aus
1 = Ultraschallsensoren An";
CM_ SG_ 919 LDW_Codierinfo_fuer_VLR "Vorhalt LDW-Codierinfo";
CM_ SG_ 919 LDW_DLC "distance to line, Abstand vom Fahrzeug zur Fahrbahnmarkierung
Der Wert gibt die Breite der Restspur zur Linie wieder (Abstand vom Fahrzeugäußerem zur Linie) (Wert POSITIV wenn Fahrzeug in der Spur - Wert NEGATIV wenn Fahrzeug über der Linie)";
CM_ SG_ 919 LDW_Frueh_Spaet "Im MMI eingestellter, aktiver Lenkeingriffszeitpunkt:
0: frueh, frueh aktiv
1: frueh, spaet aktiv
2: spaet, spaet aktiv
3: Fehler";
CM_ SG_ 919 LDW_Gong "Löst ein definiertes akustisches Signal aus.";
CM_ SG_ 919 LDW_Lernmodus "Signal dient zur Ansteuerung von Funktionsanzeigen im Mitteldisplay des Kombiinstruments (neue Funktion im MLB)";
CM_ SG_ 919 LDW_Lernmodus_seitenabhaengig "Signal dient zur Ansteuerung von Funktionsanzeigen im Mitteldisplay des Kombiinstruments für die Seitenabhänige Liniendetektion (neue Funktion ab D4)";
CM_ SG_ 919 LDW_Seite_DLCTLC "Zuordnung auf welche Seite sich LDW_DLC bzw. LDW_TLC beziehen";
CM_ SG_ 919 LDW_Status_LED_gruen " ";
CM_ SG_ 919 LDW_Texte "Bei Anzeige eines Fehlertextes im Kombi ertönt ein akustisches Signal";
CM_ SG_ 919 LDW_TLC "time to line, Zeit bis das Fahrzeug die Fahrbahnmarkierung überquert";
CM_ SG_ 919 LKS_LED_an "Ansteuerung LED auf LKS-Taste im Lichtassistenzmodul";

CM_ SG_ 810 EPS_01_CRC "Für MLB:
'Berechnung siehe Lastenheft 'Kommunikationsabsicherung für FlexRay und CAN''

Ab MQB und MLBevo:
'Berechnung siehe Lastenheft 'End-to-End Kommunikationsabsicherung''

Endwerte siehe Begleitdokument 'S-PDU Kennungsfolgen'
";
CM_ SG_ 810 EPS_Anf_KL "Nach Überschreiten einer oberen Grenztemperatur innerhalb des Steuergerätes der Lenkhilfe fordert die EPS die Zuschaltung einer externen Kühlung durch den Kühlerlüfter an.
Es besteht kein technischer Zusammenhang mit einer Batterie_ab - Erkennung in der ";
CM_ SG_ 810 EPS_ARA_Status "Anforderung vom Anhängerrangierassistent. 
16 Statuswerte";
CM_ SG_ 810 EPS_Charisma_FahrPr "MLBevo: Aktuelles Fahrprogramm des Charisma-Teilnehmers (siehe Systemlastenheft Drive Select)
MQB: Istwert der Kennlinie (siehe Systemlastenheft MQB FPA)";
CM_ SG_ 810 EPS_Charisma_Status "Rückmeldung an den Charisma-Master

Wert 0x3 ist nur für Fahrzeuge ab MQB relevant";
CM_ SG_ 810 EPS_Endanschlag "Die EPS muss applikativ ein Lenkhubmapping umsetzen. Das Lenkhubmapping muss für jeden NR-Reglerstatus den Defaultendanschlag oder die Lenkhubaufweitung zuordnen.";
CM_ SG_ 810 EPS_Fehlerlampe "Steuert direkt die Fehlerlampe Lenkhilfe (gelb); kein Aufprüfen bei Neustart, keine Rückleseinformation in Kombi-Botschaft (nur für VW526 Hybrid)";
CM_ SG_ 810 EPS_Lenkerposition "Position des Lenkers im Fahrzeug";
CM_ SG_ 810 EPS_PLA_Status "Zustand der Statusmaschine der EPS für die korrespondierenden Statusmaschine im PLA.";
CM_ SG_ 810 EPS_PWR_Abbruch "Dieses Signal gibt das Abbruchkriterium für PLA und ARA an.";
CM_ SG_ 810 EPS_PWR_Fehler "Gibt den Fehler aus wenn eine Lenkwinkelanforderung nicht ausgeführt werden konnte.";
CM_ SG_ 810 EPS_SpannungsAnf "Forderung des EPS-SG's zur Spannungsanhebung.";
CM_ SG_ 810 EPS_Warnungen "Diese Bits werden verwendet, um im Kombi Texte, Lampen oder Bilder für die Lenkhilfe darzustellen
Audi MLB/RSe:
Text_1: Lenkung defekt (Prio 1)
Text_2: Lenkung Systemstörung (Prio 2)
VW526:
Text_1 (ID_TXT_1026.1): Ausfall Lenkunterstützung
Text_2 (I";

CM_ SG_ 160 EPS_04_BZ "Botschaftszähler";
CM_ SG_ 160 EPS_04_CRC "Für MLB:
'Berechnung siehe Lastenheft 'Kommunikationsabsicherung für FlexRay und CAN''

Ab MQB und MLBevo:
'Berechnung siehe Lastenheft 'End-to-End Kommunikationsabsicherung''

Endwerte siehe Begleitdokument 'S-PDU Kennungsfolgen'";
CM_ SG_ 160 EPS_AWA_Status "beschreibt den Status der AWA-Funktion im EPS-Steuergerät. (Ausweich-Assistent)";
CM_ SG_ 160 EPS_FAS_Regelgroesse "Aktuelle Regelauslastung der STA/STP-Funktionsschnittstelle";
CM_ SG_ 160 EPS_FAS_VZ_Regelgroesse "Richtung der FAS Regelgröße";
CM_ SG_ 160 EPS_Lenkmoment_AbsReduz "Gibt den Absolutwert des aktuelle Handlenkmoment mit einer Auflösung von 0 ,62 Nm aus";
CM_ SG_ 160 EPS_Motormoment "Motornahes Motor-Sollmoment";
CM_ SG_ 160 EPS_QBit_Zahnstangen_Pos "beschreibt die Qualität/Vertrauenswürdigkeit der Zahnstangenposition";
CM_ SG_ 160 EPS_STA_Status "beschreibt den Status der STA-Funktion im EPS-Steuergerät. (Stauassistent)";
CM_ SG_ 160 EPS_Versorgungsspannung "Gibt die am Steuergerät anliegende Spannung aus.
";
CM_ SG_ 160 EPS_Versorgungsstatus "Erkennung Störung im Versorgungspfad
";
CM_ SG_ 160 EPS_VZ_Zahnstangenposition "Vorzeichen der Position/Verschiebung der Zahnstange bzgl. Lenkungsmitte
Vorzeichen:
(Fahreransicht: positiv = links von der Nullstellung des Lenkrades)
Nullstellung = +0mm";
CM_ SG_ 160 EPS_Zahnstangen_Pos "Position/Verschiebung der Zahnstange bzgl. Lenkungsmitte";

CM_ SG_ 981 BCM1_Abblendlicht_Anf "Anforderung Abblendlicht
";
CM_ SG_ 981 BCM1_Adaptive_Lichtvert_Anf "Funktion 'Adaptive Lichtverteilung' im AFS-SG  Ein- und Ausschalten";
CM_ SG_ 981 BCM1_Allwetterlicht_Anf "Anforderung eines Allwetterlichts (über AFS-SG realisiert): Licht für schlechte Sichtverhältnisse";
CM_ SG_ 981 BCM1_Animationssperrung "Sperrung der Scheinwerfer- und Heckleuchten-Animationen. Grund für Sperrung sind allgemeine Rahmenbedingungen, wie beispielseweise eine LDS-Stellung ungleich 'Auto'";
CM_ SG_ 981 BCM1_Autobahnlicht_Anf "Anforderung Autobahnlicht
";
CM_ SG_ 981 BCM1_CH_aktiv "Coming Home (zusätzlich zum Signal 'BCM1_CH_LH_aktiv' in der Botschaft BCM1_01)";
CM_ SG_ 981 BCM1_CH_LH_aktiv "Status Comming / Leaving Home
";
CM_ SG_ 981 BCM1_Fernlicht_Anf "Anforderung Fernlicht
";
CM_ SG_ 981 BCM1_FOD_Sperrung_Animationen_HL "Sperrung Heckleuchten-Animationen durch FoD.";
CM_ SG_ 981 BCM1_FoD_Sperrung_WiBli "Sperrung Wischeffekt des dynamischen Blinkers (Front & Heck) durch FoD";
CM_ SG_ 981 BCM1_Gleitende_Leuchtw_Anf "Funktion 'Gleitende Leuchtweite' im AFS-SG  freischalten";
CM_ SG_ 981 BCM1_GLW_Fernlicht_Anf "Harte Fernlichtanforderung von BCM1 an die Funktion 'gleitende Leuchtweite' im AFS-SG";
CM_ SG_ 981 BCM1_Kurvenlicht_links_Anf "Ansteuerung linkes Kurvenlicht/Abbiegelicht duch BCM1";
CM_ SG_ 981 BCM1_Kurvenlicht_rechts_Anf "Ansteuerung rechtes Kurvenlicht/Abbiegelicht duch BCM1";
CM_ SG_ 981 BCM1_LH_aktiv "Leaving Home (zusätzlich zum Signal 'BCM1_CH_LH_aktiv' in der Botschaft BCM1_01)";
CM_ SG_ 981 BCM1_Nebellicht_Anf "Anforderung Nebellicht
";
CM_ SG_ 981 BCM1_Nebelschluss_Ahg_Anf "Anforderung: Nebelschlusslicht Anhänger (Sollzustand)
";
CM_ SG_ 981 BCM1_Nebelschluss_Fzg_Anf "Anforderung: Nebelschlusslicht Fahrzeug (Sollzustand)";
CM_ SG_ 981 BCM1_Parklicht_li_Anf "Anforderung: Parklicht links (Sollzustand)
";
CM_ SG_ 981 BCM1_Parklicht_re_Anf "Anforderung: Parklicht rechts (Sollzustand)
";
CM_ SG_ 981 BCM1_Regenlicht_Anf "Anforderung: Regenlicht (Sollzustand)
";
CM_ SG_ 981 BCM1_Schlusslicht_Anf "Anforderung: Schlusslicht Fahrzeug (Sollzustand)
";
CM_ SG_ 981 BCM1_Schlusslicht_Signatur "Anforderung der Umschaltung der Schlusslicht-Signatur";
CM_ SG_ 981 BCM1_Signaturlicht_Anf "Signal zur Anforderung des Signaturlichts";
CM_ SG_ 981 BCM1_Standlicht_Anf "Anforderung: Schlusslicht (Sollzustand)";
CM_ SG_ 981 BCM1_Tagfahrlicht_Anf "Anforderung: Tagfahrlicht (Sollzustand)";
CM_ SG_ 981 BCM1_Touristen_Licht_Anf "Anforderung: Touristenlicht (Sollzustand)";
CM_ SG_ 981 BCM1_Umfeldleuchten_Anf "Anforderung für Umfeldleuchten";
CM_ SG_ 981 BCM_Rueckfahrlicht_Anf "Anforderung Rückfahrlicht (Sollzustand). 
Das Signal wird entprellt (typisch 400ms) und bei KL15EIN gesendet. Das Signal ist unabhängig von der Position des Heckdeckels (kein Überhitzungsschutz).";
CM_ SG_ 981 Licht_Anf_01_BZ "4bit Botschaftszaehler, wird mit jeder Sendebotschaft inkrementiert";
CM_ SG_ 981 Licht_Anf_01_CRC "Für MLB:
'Berechnung siehe Lastenheft 'Kommunikationsabsicherung für FlexRay und CAN''

Ab MQB und MLBevo:
'Berechnung siehe Lastenheft 'End-to-End Kommunikationsabsicherung''

Endwerte siehe Begleitdokument 'S-PDU Kennungsfolgen'";

CM_ SG_ 982 BCM2_Bremsl_durch_ECD "Bremslicht (ECD-Bremsung)
";
CM_ SG_ 982 LH_3_Bremsl_def "Fehlerstatus 3. Bremsleuchte
";
CM_ SG_ 982 LH_Aussenlicht_def "Aussenlicht kann nicht mehr korrekt angesteuert werden (EEPROM Codierung kann nicht mehr ausgelesen werden)
";
CM_ SG_ 982 LH_Blinker_HL_akt "Blinker hinten links
";
CM_ SG_ 982 LH_Blinker_HR_akt "Blinker hinten rechts
";
CM_ SG_ 982 LH_Blinker_li_def "Fehlerstatus Blinker hinten links
";
CM_ SG_ 982 LH_Blinker_re_def "Fehlerstatus Blinker hinten rechts
";
CM_ SG_ 982 LH_Brems_Blk_li_def "Konfiguration BRL + BLK links 
";
CM_ SG_ 982 LH_Brems_Blk_re_def "Konfiguration BRL + BLK rechts
";
CM_ SG_ 982 LH_Bremsl_li_def "Fehlerstatus Bremslicht hinten links (Detektion Einzelausfall)
";
CM_ SG_ 982 LH_Bremsl_li_ges_def "Fehlerstatus Bremslicht hinten links (Detektion Totalausfall)
";
CM_ SG_ 982 LH_Bremsl_mi_def "Fehlerstatus Bremslicht mitte oder Gepäckraumklappe  (Detektion Einzelausfall)";
CM_ SG_ 982 LH_Bremsl_re_def "Fehlerstatus Bremslicht hinten rechts  (Detektion Einzelausfall)
";
CM_ SG_ 982 LH_Bremsl_re_ges_def "Fehlerstatus Bremslicht hinten rechts (Detektion Totalausfall)";
CM_ SG_ 982 LH_Bremslicht_H_aktiv "Bremslicht hinten
";
CM_ SG_ 982 LH_Diag_LED_li_def "Heckleuchte links defekt";
CM_ SG_ 982 LH_Diag_LED_re_def "Heckleuchte rechts defekt";
CM_ SG_ 982 LH_Diag_Status_li_def "Außenlicht Diagnose 
Systemstörung links";
CM_ SG_ 982 LH_Diag_Status_re_def "Außenlicht Diagnose Systemstörung rechts ";
CM_ SG_ 982 LH_Kennzl_def "Fehlerstatus Kennzeichenbeleuchtung hinten
";
CM_ SG_ 982 LH_Nebel_li_def "Fehlererkennung Nebelschlusslicht hinten links
";
CM_ SG_ 982 LH_Nebel_mi_def "Fehlererkennung Nebelschlusslicht hinten Mitte


";
CM_ SG_ 982 LH_Nebel_re_def "Fehlererkennung Nebelschlusslicht hinten rechts
";
CM_ SG_ 982 LH_Nebelschluss_aktiv "Nebelschlusslicht
";
CM_ SG_ 982 LH_Parklicht_HL_aktiv "Parklicht hinten links 
";
CM_ SG_ 982 LH_Parklicht_HR_aktiv "Parklicht hinten rechts 
";
CM_ SG_ 982 LH_Rueckf_li_def "Fehlererkennung Rückfahrlicht hinten links
";
CM_ SG_ 982 LH_Rueckf_mi_def "Fehlererkennung Rückfahrlicht Mitte
";
CM_ SG_ 982 LH_Rueckf_re_def "Fehlererkennung Rückfahrlicht hinten rechts
";
CM_ SG_ 982 LH_Rueckfahrlicht_aktiv "Rueckfahrlicht";
CM_ SG_ 982 LH_Schluss_Brems_li_def "Konfiguration SL+ BRL + PL links und SL+ BRL  links
";
CM_ SG_ 982 LH_Schluss_Brems_mi_def "Fehlerstatus Schluss + Bremslicht mitte defekt (Detektion Einzelausfall)";
CM_ SG_ 982 LH_Schluss_Brems_Nebel_li_def "Signal wird gesetzt, wenn eine Unterbrechung oder  ein Kurzschluss am Lampenausgang für Schluss_Brems_Nebelschlusslicht erkannt wird.";
CM_ SG_ 982 LH_Schluss_Brems_Nebel_re_def "Signal wird gesetzt, wenn eine Unterbrechung oder  ein Kurzschluss am Lampenausgang für Schluss_Brems_Nebelschlusslicht erkannt wird.";
CM_ SG_ 982 LH_Schluss_Brems_re_def "Konfiguration SL+ BRL + PL rechts und SL+ BRL  rechts
";
CM_ SG_ 982 LH_Schluss_Nebel_li_def "Konfiguration SL + NSL links oder SL + NSL + PL links
";
CM_ SG_ 982 LH_Schluss_Nebel_re_def "Konfiguration SL + NSL rechts oder SL + NSL + PL rechts
";
CM_ SG_ 982 LH_Schlusslicht_li_def "Fehlererkennung Schlusslicht hinten links
";
CM_ SG_ 982 LH_Schlusslicht_mi_def "Fehlererkennung Schlusslicht hinten Mitte";
CM_ SG_ 982 LH_Schlusslicht_re_def "Fehlererkennung Schlusslicht hinten rechts
";
CM_ SG_ 982 LH_SL_BRL_BLK_li_def "Konfiguration SL + BRL + BLK links oder SL + BRL + BLK + PL links
";
CM_ SG_ 982 LH_SL_BRL_BLK_re_def "Konfiguration SL + BRL + BLK rechts oder SL + BRL + BLK + PL rechts
";
CM_ SG_ 982 LH_Standlicht_H_aktiv "Standlicht hinten
";
CM_ SG_ 982 LH_Zusatzschlussl_def "mindestens ein Zusatzschlusslicht in der Heckbeleuchtung defekt.";
BA_DEF_REL_ BU_SG_REL_  "GenSigTimeoutTime" INT 0 65535;
BA_DEF_ BO_  "DiagRequest" ENUM "No", "Yes";
BA_DEF_ BO_  "DiagResponse" ENUM "No", "Yes";
BA_DEF_ BO_  "DiagState" ENUM "No", "Yes";
BA_DEF_ BO_  "GenMsgChkConstant" HEX 0 4095;
BA_DEF_ BO_  "GenMsgCycleTime" INT 0 65535;
BA_DEF_ BO_  "GenMsgCycleTimeFast" INT 0 65535;
BA_DEF_ BO_  "GenMsgDelayTime" INT 0 100000;
BA_DEF_ BO_  "GenMsgILSupport" ENUM "No", "Yes";
BA_DEF_ BO_  "GenMsgNrOfRepetition" INT 0 100;
BA_DEF_ BO_  "GenMsgPDUConstants" STRING;
BA_DEF_ BO_  "GenMsgSendType" ENUM "Cyclic", "not_used", "not_used", "not_used", "not_used", "not_used", "not_used", "IfActive", "NoMsgSendType";
BA_DEF_ BO_  "GenMsgStartDelayTime" INT 0 100000;
BA_DEF_ BO_  "NmMessage" ENUM "No", "Yes";
BA_DEF_ BO_  "NmhMessage" ENUM "No", "Yes";
BA_DEF_ BO_  "MsgType" ENUM "Application", "NM ", "NMH", "TP2.0", "ISO-TP ", "BAP", "EID", "KS", "XCP_PRE_CONFIGURED", "XCP_RUNTIME_CONFIGURED";
BA_DEF_ BO_  "VAGTP20_API" HEX 0 255;
BA_DEF_ BO_  "VAGTP20_DynConnection" ENUM "No", "Yes";
BA_DEF_ BO_  "VAGTP20_DynSetup" ENUM "No", "Yes";
BA_DEF_ BO_  "VAGTP20_StatConnection" ENUM "No", "Yes";
BA_DEF_ SG_  "GenSigActiveRepetitions" INT -2147483648 2147483647;
BA_DEF_ SG_  "GenSigInactiveValue" INT -2147483648 2147483647;
BA_DEF_ SG_  "GenSigSendType" ENUM "Cyclic", "OnWrite", "OnWriteWithRepetition", "OnChange", "OnChangeWithRepetition", "IfActive", "IfActiveWithRepetition", "NoSigSendType", "OnChangeAndIfActive", "OnChangeAndIfActiveWithRepetition";
BA_DEF_ SG_  "GenSigStartValue" INT -2147483648 2147483647;
BA_DEF_ SG_  "NWM-WakeupAllowed" ENUM "No", "Yes";
BA_DEF_ SG_  "GenSigFuncType" ENUM "NoFunction", "MsgCounter", "CRC-8", "XOR", "XOR-2", "DatedBit", "SW-Kl15", "CHK", "Constant", "Protocol", "CRC-8-SAE_J1850", "CRC-32", "DataLength", "DataID", "MsgCounter16", "SOK-Signatur", "Cluster";
BA_DEF_ SG_  "GenSigSwitchedByIgnition" ENUM "No", "Yes";
BA_DEF_ SG_  "Fehlerwert" HEX 0 2147483647;
BA_DEF_ SG_  "GenSigMissingSourceValue" HEX 0 2147483647;
BA_DEF_DEF_REL_  "GenSigTimeoutTime" 0;
BA_DEF_DEF_  "DiagRequest" "No";
BA_DEF_DEF_  "DiagResponse" "No";
BA_DEF_DEF_  "DiagState" "No";
BA_DEF_DEF_  "GenMsgChkConstant" 0;
BA_DEF_DEF_  "GenMsgCycleTime" 0;
BA_DEF_DEF_  "GenMsgCycleTimeFast" 0;
BA_DEF_DEF_  "GenMsgDelayTime" 0;
BA_DEF_DEF_  "GenMsgILSupport" "No";
BA_DEF_DEF_  "GenMsgNrOfRepetition" 0;
BA_DEF_DEF_  "GenMsgPDUConstants" "";
BA_DEF_DEF_  "GenMsgSendType" "NoMsgSendType";
BA_DEF_DEF_  "GenMsgStartDelayTime" 0;
BA_DEF_DEF_  "NmMessage" "No";
BA_DEF_DEF_  "NmhMessage" "No";
BA_DEF_DEF_  "MsgType" "Application";
BA_DEF_DEF_  "VAGTP20_API" 0;
BA_DEF_DEF_  "VAGTP20_DynConnection" "No";
BA_DEF_DEF_  "VAGTP20_DynSetup" "No";
BA_DEF_DEF_  "VAGTP20_StatConnection" "No";
BA_DEF_DEF_  "GenSigActiveRepetitions" 0;
BA_DEF_DEF_  "GenSigInactiveValue" 0;
BA_DEF_DEF_  "GenSigSendType" "NoSigSendType";
BA_DEF_DEF_  "GenSigStartValue" 0;
BA_DEF_DEF_  "NWM-WakeupAllowed" "No";
BA_DEF_DEF_  "GenSigFuncType" "NoFunction";
BA_DEF_DEF_  "GenSigSwitchedByIgnition" "Yes";
BA_DEF_DEF_  "Fehlerwert" 0;
BA_DEF_DEF_  "GenSigMissingSourceValue" 0;
BA_ "GenMsgCycleTime" BO_ 2589283621 1000;
BA_ "GenMsgDelayTime" BO_ 2589283621 100;
BA_ "GenMsgILSupport" BO_ 2589283621 1;
BA_ "GenMsgSendType" BO_ 2589283621 0;
BA_ "GenMsgCycleTime" BO_ 2463978701 100;
BA_ "GenMsgILSupport" BO_ 2463978701 1;
BA_ "GenMsgSendType" BO_ 2463978701 0;
BA_ "GenMsgCycleTime" BO_ 2589283689 1000;
BA_ "GenMsgDelayTime" BO_ 2589283689 200;
BA_ "GenMsgILSupport" BO_ 2589283689 1;
BA_ "GenMsgSendType" BO_ 2589283689 0;
BA_ "GenMsgCycleTime" BO_ 2589284046 1000;
BA_ "GenMsgDelayTime" BO_ 2589284046 50;
BA_ "GenMsgILSupport" BO_ 2589284046 1;
BA_ "GenMsgSendType" BO_ 2589284046 0;
BA_ "GenMsgCycleTime" BO_ 992 100;
BA_ "GenMsgILSupport" BO_ 992 1;
BA_ "GenMsgSendType" BO_ 992 0;
BA_ "GenMsgCycleTime" BO_ 1712 500;
BA_ "GenMsgILSupport" BO_ 1712 1;
BA_ "GenMsgSendType" BO_ 1712 0;
BA_ "GenMsgCycleTime" BO_ 1505 200;
BA_ "GenMsgILSupport" BO_ 1505 1;
BA_ "GenMsgSendType" BO_ 1505 0;
BA_ "GenMsgCycleTime" BO_ 1717 500;
BA_ "GenMsgILSupport" BO_ 1717 1;
BA_ "GenMsgSendType" BO_ 1717 0;
BA_ "GenMsgCycleTime" BO_ 1513 200;
BA_ "GenMsgILSupport" BO_ 1513 1;
BA_ "GenMsgSendType" BO_ 1513 0;
BA_ "GenMsgCycleTime" BO_ 1295 100;
BA_ "GenMsgILSupport" BO_ 1295 1;
BA_ "GenMsgSendType" BO_ 1295 0;
BA_ "GenMsgCycleTime" BO_ 2589283474 1000;
BA_ "GenMsgDelayTime" BO_ 2589283474 100;
BA_ "GenMsgILSupport" BO_ 2589283474 1;
BA_ "GenMsgSendType" BO_ 2589283474 0;
BA_ "GenMsgCycleTime" BO_ 2549088270 500;
BA_ "GenMsgILSupport" BO_ 2549088270 1;
BA_ "GenMsgSendType" BO_ 2549088270 0;
BA_ "GenMsgCycleTime" BO_ 2549088272 500;
BA_ "GenMsgILSupport" BO_ 2549088272 1;
BA_ "GenMsgSendType" BO_ 2549088272 0;
BA_ "GenMsgStartDelayTime" BO_ 2549088272 75;
BA_ "GenMsgCycleTime" BO_ 2549088326 500;
BA_ "GenMsgILSupport" BO_ 2549088326 1;
BA_ "GenMsgSendType" BO_ 2549088326 0;
BA_ "GenMsgCycleTime" BO_ 2549088345 500;
BA_ "GenMsgILSupport" BO_ 2549088345 1;
BA_ "GenMsgSendType" BO_ 2549088345 0;
BA_ "GenMsgCycleTime" BO_ 2549088452 500;
BA_ "GenMsgILSupport" BO_ 2549088452 1;
BA_ "GenMsgSendType" BO_ 2549088452 0;
BA_ "GenMsgCycleTime" BO_ 2549088453 500;
BA_ "GenMsgILSupport" BO_ 2549088453 1;
BA_ "GenMsgSendType" BO_ 2549088453 0;
BA_ "GenMsgCycleTime" BO_ 779 200;
BA_ "GenMsgDelayTime" BO_ 779 50;
BA_ "GenMsgILSupport" BO_ 779 1;
BA_ "GenMsgSendType" BO_ 779 0;
BA_ "GenMsgCycleTime" BO_ 1719 1000;
BA_ "GenMsgDelayTime" BO_ 1719 100;
BA_ "GenMsgILSupport" BO_ 1719 1;
BA_ "GenMsgSendType" BO_ 1719 0;
BA_ "MsgType" BO_ 2549874958 4;
BA_ "MsgType" BO_ 2550006030 4;
BA_ "MsgType" BO_ 2549875140 4;
BA_ "MsgType" BO_ 2550006212 4;
BA_ "MsgType" BO_ 2549875141 4;
BA_ "MsgType" BO_ 2550006213 4;
BA_ "GenMsgCycleTime" BO_ 919 80;
BA_ "GenMsgDelayTime" BO_ 919 40;
BA_ "GenMsgILSupport" BO_ 919 1;
BA_ "GenMsgSendType" BO_ 919 0;
BA_ "GenMsgChkConstant" BO_ 810 41;
BA_ "GenMsgCycleTime" BO_ 810 40;
BA_ "GenMsgILSupport" BO_ 810 1;
BA_ "GenMsgPDUConstants" BO_ 810 "0x29,0x29,0x29,0x29,0x29,0x29,0x29,0x29,0x29,0x29,0x29,0x29,0x29,0x29,0x29,0x29";
BA_ "GenMsgSendType" BO_ 810 0;
BA_ "GenMsgCycleTime" BO_ 160 10;
BA_ "GenMsgILSupport" BO_ 160 1;
BA_ "GenMsgPDUConstants" BO_ 160 "0x4a,0xb4,0xe8,0x24,0x99,0x5a,0x59,0x8b,0x1e,0xaa,0x94,0xb6,0x09,0xd5,0xaf,0x97";
BA_ "GenMsgSendType" BO_ 160 0;
BA_ "GenMsgCycleTime" BO_ 981 100;
BA_ "GenMsgDelayTime" BO_ 981 50;
BA_ "GenMsgILSupport" BO_ 981 1;
BA_ "GenMsgPDUConstants" BO_ 981 "0xc5,0x39,0xc7,0xf9,0x92,0xd8,0x24,0xce,0xf1,0xb5,0x7a,0xc4,0xbc,0x60,0xe3,0xd1";
BA_ "GenMsgSendType" BO_ 981 0;
BA_ "GenMsgCycleTime" BO_ 982 100;
BA_ "GenMsgILSupport" BO_ 982 1;
BA_ "GenMsgPDUConstants" BO_ 982 "0xc5,0x8e,0x64,0x95,0x9e,0xed,0x60,0x45,0x5d,0x8d,0xb2,0x80,0xa1,0x23,0x7d,0x35";
BA_ "GenMsgSendType" BO_ 982 0;
BA_ "GenSigSendType" SG_ 2589283621 KL_ACmax_Aktiv 3;
BA_ "GenSigSwitchedByIgnition" SG_ 2589283621 KL_ACmax_Aktiv 0;
BA_ "GenSigSendType" SG_ 2589283621 KL_Defrost_Aktiv 3;
BA_ "GenSigSwitchedByIgnition" SG_ 2589283621 KL_Defrost_Aktiv 0;
BA_ "GenSigSendType" SG_ 2589283621 KL_ECO_Aktiv 3;
BA_ "GenSigSwitchedByIgnition" SG_ 2589283621 KL_ECO_Aktiv 0;
BA_ "GenSigSendType" SG_ 2589283621 KL_ECO_PRO_Aktiv 3;
BA_ "GenSigSwitchedByIgnition" SG_ 2589283621 KL_ECO_PRO_Aktiv 0;
BA_ "GenSigSendType" SG_ 2589283621 KL_Eps_Innen 3;
BA_ "GenSigStartValue" SG_ 2589283621 KL_Eps_Innen 254;
BA_ "GenSigSwitchedByIgnition" SG_ 2589283621 KL_Eps_Innen 0;
BA_ "Fehlerwert" SG_ 2589283621 KL_Eps_Innen 255;
BA_ "GenSigSendType" SG_ 2589283621 KL_FlHz_Soll_HL 3;
BA_ "GenSigSwitchedByIgnition" SG_ 2589283621 KL_FlHz_Soll_HL 0;
BA_ "GenSigSendType" SG_ 2589283621 KL_FlHz_Soll_HR 3;
BA_ "GenSigSwitchedByIgnition" SG_ 2589283621 KL_FlHz_Soll_HR 0;
BA_ "GenSigSendType" SG_ 2589283621 KL_FlHz_Soll_VL 3;
BA_ "GenSigSwitchedByIgnition" SG_ 2589283621 KL_FlHz_Soll_VL 0;
BA_ "GenSigSendType" SG_ 2589283621 KL_FlHz_Soll_VR 3;
BA_ "GenSigSwitchedByIgnition" SG_ 2589283621 KL_FlHz_Soll_VR 0;
BA_ "GenSigSendType" SG_ 2589283621 KL_Kundeneingriff_Geblaese 3;
BA_ "GenSigSwitchedByIgnition" SG_ 2589283621 KL_Kundeneingriff_Geblaese 0;
BA_ "GenSigSendType" SG_ 2589283621 KL_NV_Energie_Anf 3;
BA_ "GenSigStartValue" SG_ 2589283621 KL_NV_Energie_Anf 254;
BA_ "GenSigSwitchedByIgnition" SG_ 2589283621 KL_NV_Energie_Anf 0;
BA_ "Fehlerwert" SG_ 2589283621 KL_NV_Energie_Anf 255;
BA_ "GenSigSendType" SG_ 2589283621 KL_QBit_Sonnenintensitaet 3;
BA_ "GenSigStartValue" SG_ 2589283621 KL_QBit_Sonnenintensitaet 1;
BA_ "GenSigSwitchedByIgnition" SG_ 2589283621 KL_QBit_Sonnenintensitaet 0;
BA_ "GenSigSendType" SG_ 2589283621 KL_Sonnenintensitaet 0;
BA_ "GenSigSwitchedByIgnition" SG_ 2589283621 KL_Sonnenintensitaet 0;
BA_ "Fehlerwert" SG_ 2589283621 KL_Sonnenintensitaet 255;
BA_ "GenSigSendType" SG_ 2589283621 KL_Status_Klimastil 3;
BA_ "GenSigSwitchedByIgnition" SG_ 2589283621 KL_Status_Klimastil 0;
BA_ "GenSigSendType" SG_ 2589283621 KL_Thermischer_Bedarf 3;
BA_ "GenSigStartValue" SG_ 2589283621 KL_Thermischer_Bedarf 6;
BA_ "GenSigSwitchedByIgnition" SG_ 2589283621 KL_Thermischer_Bedarf 0;
BA_ "Fehlerwert" SG_ 2589283621 KL_Thermischer_Bedarf 7;
BA_ "GenSigSendType" SG_ 2589283621 KL_Umluft_Connect_status 3;
BA_ "GenSigSwitchedByIgnition" SG_ 2589283621 KL_Umluft_Connect_status 0;
BA_ "GenSigSendType" SG_ 2589283621 KL_ZR_Anforderung 3;
BA_ "GenSigSwitchedByIgnition" SG_ 2589283621 KL_ZR_Anforderung 0;
BA_ "GenSigSendType" SG_ 2463978701 KL_AC_Schalter_Prognose 0;
BA_ "GenSigSwitchedByIgnition" SG_ 2463978701 KL_AC_Schalter_Prognose 0;
BA_ "GenSigSendType" SG_ 2463978701 KL_Leistungsreduktions_Hinweis 0;
BA_ "GenSigSwitchedByIgnition" SG_ 2463978701 KL_Leistungsreduktions_Hinweis 0;
BA_ "GenSigSendType" SG_ 2463978701 KL_Sollklimamodus_FPR_1 0;
BA_ "GenSigStartValue" SG_ 2463978701 KL_Sollklimamodus_FPR_1 1;
BA_ "GenSigSwitchedByIgnition" SG_ 2463978701 KL_Sollklimamodus_FPR_1 0;
BA_ "GenSigSendType" SG_ 2463978701 KL_Sollklimamodus_FPR_2 0;
BA_ "GenSigStartValue" SG_ 2463978701 KL_Sollklimamodus_FPR_2 1;
BA_ "GenSigSwitchedByIgnition" SG_ 2463978701 KL_Sollklimamodus_FPR_2 0;
BA_ "GenSigSendType" SG_ 2463978701 KL_Sollklimamodus_FPR_3 0;
BA_ "GenSigStartValue" SG_ 2463978701 KL_Sollklimamodus_FPR_3 1;
BA_ "GenSigSwitchedByIgnition" SG_ 2463978701 KL_Sollklimamodus_FPR_3 0;
BA_ "GenSigSendType" SG_ 2463978701 KL_Temp_Soll_hl_Prognose 0;
BA_ "GenSigStartValue" SG_ 2463978701 KL_Temp_Soll_hl_Prognose 31;
BA_ "GenSigSwitchedByIgnition" SG_ 2463978701 KL_Temp_Soll_hl_Prognose 0;
BA_ "GenSigSendType" SG_ 2463978701 KL_Temp_Soll_hr_Prognose 0;
BA_ "GenSigStartValue" SG_ 2463978701 KL_Temp_Soll_hr_Prognose 31;
BA_ "GenSigSwitchedByIgnition" SG_ 2463978701 KL_Temp_Soll_hr_Prognose 0;
BA_ "GenSigSendType" SG_ 2463978701 KL_Temp_Soll_vl_Prognose 0;
BA_ "GenSigStartValue" SG_ 2463978701 KL_Temp_Soll_vl_Prognose 31;
BA_ "GenSigSwitchedByIgnition" SG_ 2463978701 KL_Temp_Soll_vl_Prognose 0;
BA_ "GenSigSendType" SG_ 2463978701 KL_Temp_Soll_vr_Prognose 0;
BA_ "GenSigStartValue" SG_ 2463978701 KL_Temp_Soll_vr_Prognose 31;
BA_ "GenSigSwitchedByIgnition" SG_ 2463978701 KL_Temp_Soll_vr_Prognose 0;
BA_ "GenSigSendType" SG_ 2589283689 KL_FANonly_Aktiv 3;
BA_ "GenSigSwitchedByIgnition" SG_ 2589283689 KL_FANonly_Aktiv 0;
BA_ "GenSigSendType" SG_ 2589284046 KL_SH_LL1_PWM 3;
BA_ "GenSigSwitchedByIgnition" SG_ 2589284046 KL_SH_LL1_PWM 0;
BA_ "GenSigSendType" SG_ 2589284046 KL_SH_LS1_PWM 3;
BA_ "GenSigSwitchedByIgnition" SG_ 2589284046 KL_SH_LS1_PWM 0;
BA_ "GenSigSendType" SG_ 2589284046 KL_SH_RL1_PWM 3;
BA_ "GenSigSwitchedByIgnition" SG_ 2589284046 KL_SH_RL1_PWM 0;
BA_ "GenSigSendType" SG_ 2589284046 KL_SH_RS1_PWM 3;
BA_ "GenSigSwitchedByIgnition" SG_ 2589284046 KL_SH_RS1_PWM 0;
BA_ "GenSigSendType" SG_ 2589284046 KL_SL_LL1_PWM 3;
BA_ "GenSigSwitchedByIgnition" SG_ 2589284046 KL_SL_LL1_PWM 0;
BA_ "GenSigSendType" SG_ 2589284046 KL_SL_LS1_PWM 3;
BA_ "GenSigSwitchedByIgnition" SG_ 2589284046 KL_SL_LS1_PWM 0;
BA_ "GenSigSendType" SG_ 2589284046 KL_SL_RL1_PWM 3;
BA_ "GenSigSwitchedByIgnition" SG_ 2589284046 KL_SL_RL1_PWM 0;
BA_ "GenSigSendType" SG_ 2589284046 KL_SL_RS1_PWM 3;
BA_ "GenSigSwitchedByIgnition" SG_ 2589284046 KL_SL_RS1_PWM 0;
BA_ "GenSigSendType" SG_ 2589284046 KL_SSC_Status_VL 3;
BA_ "GenSigSwitchedByIgnition" SG_ 2589284046 KL_SSC_Status_VL 0;
BA_ "GenSigSendType" SG_ 2589284046 KL_SSC_Status_VR 3;
BA_ "GenSigSwitchedByIgnition" SG_ 2589284046 KL_SSC_Status_VR 0;
BA_ "GenSigSendType" SG_ 992 KL_Fehler_Fussraum_Klappen 0;
BA_ "GenSigSwitchedByIgnition" SG_ 992 KL_Fehler_Fussraum_Klappen 0;
BA_ "GenSigSendType" SG_ 992 KL_Fehler_Temp_Klappen 0;
BA_ "GenSigSwitchedByIgnition" SG_ 992 KL_Fehler_Temp_Klappen 0;
BA_ "GenSigSendType" SG_ 992 KL_Fehler_Temp_MA_Klappen 0;
BA_ "GenSigSwitchedByIgnition" SG_ 992 KL_Fehler_Temp_MA_Klappen 0;
BA_ "GenSigSendType" SG_ 992 KL_Fehler_Umluft 0;
BA_ "GenSigSwitchedByIgnition" SG_ 992 KL_Fehler_Umluft 0;
BA_ "GenSigSendType" SG_ 992 KL_Fond_Absperrventil 0;
BA_ "GenSigSwitchedByIgnition" SG_ 992 KL_Fond_Absperrventil 0;
BA_ "GenSigSendType" SG_ 992 KL_Fond_Fuss_Temp_hl 0;
BA_ "GenSigStartValue" SG_ 992 KL_Fond_Fuss_Temp_hl 1022;
BA_ "GenSigSwitchedByIgnition" SG_ 992 KL_Fond_Fuss_Temp_hl 0;
BA_ "Fehlerwert" SG_ 992 KL_Fond_Fuss_Temp_hl 1023;
BA_ "GenSigSendType" SG_ 992 KL_Fond_Fuss_Temp_hr 0;
BA_ "GenSigStartValue" SG_ 992 KL_Fond_Fuss_Temp_hr 1022;
BA_ "GenSigSwitchedByIgnition" SG_ 992 KL_Fond_Fuss_Temp_hr 0;
BA_ "Fehlerwert" SG_ 992 KL_Fond_Fuss_Temp_hr 1023;
BA_ "GenSigSendType" SG_ 992 KL_Fond_KD_Fehler 0;
BA_ "GenSigSwitchedByIgnition" SG_ 992 KL_Fond_KD_Fehler 0;
BA_ "GenSigSendType" SG_ 992 KL_MA_Temp_hl 0;
BA_ "GenSigStartValue" SG_ 992 KL_MA_Temp_hl 1022;
BA_ "GenSigSwitchedByIgnition" SG_ 992 KL_MA_Temp_hl 0;
BA_ "Fehlerwert" SG_ 992 KL_MA_Temp_hl 1023;
BA_ "GenSigSendType" SG_ 992 KL_MA_Temp_hr 0;
BA_ "GenSigStartValue" SG_ 992 KL_MA_Temp_hr 1022;
BA_ "GenSigSwitchedByIgnition" SG_ 992 KL_MA_Temp_hr 0;
BA_ "Fehlerwert" SG_ 992 KL_MA_Temp_hr 1023;
BA_ "GenSigSendType" SG_ 992 KL_RAB 0;
BA_ "GenSigSwitchedByIgnition" SG_ 992 KL_RAB 0;
BA_ "GenSigSendType" SG_ 992 KL_SH_Soll_hl 0;
BA_ "GenSigSwitchedByIgnition" SG_ 992 KL_SH_Soll_hl 0;
BA_ "GenSigSendType" SG_ 992 KL_SH_Soll_hr 0;
BA_ "GenSigSwitchedByIgnition" SG_ 992 KL_SH_Soll_hr 0;
BA_ "GenSigSendType" SG_ 992 KL_SIH_Takt_hl 0;
BA_ "GenSigSwitchedByIgnition" SG_ 992 KL_SIH_Takt_hl 0;
BA_ "GenSigSendType" SG_ 992 KL_SIH_Takt_hr 0;
BA_ "GenSigSwitchedByIgnition" SG_ 992 KL_SIH_Takt_hr 0;
BA_ "GenSigSendType" SG_ 992 KL_SL_Soll_hl 0;
BA_ "GenSigSwitchedByIgnition" SG_ 992 KL_SL_Soll_hl 0;
BA_ "GenSigSendType" SG_ 992 KL_SL_Soll_hr 0;
BA_ "GenSigSwitchedByIgnition" SG_ 992 KL_SL_Soll_hr 0;
BA_ "GenSigSendType" SG_ 1712 FS_Luftfeuchte_rel 0;
BA_ "Fehlerwert" SG_ 1712 FS_Luftfeuchte_rel 255;
BA_ "GenSigMissingSourceValue" SG_ 1712 FS_Luftfeuchte_rel 255;
BA_ "GenSigSendType" SG_ 1712 FS_ResponseError 0;
BA_ "GenSigSwitchedByIgnition" SG_ 1712 FS_ResponseError 0;
BA_ "Fehlerwert" SG_ 1712 FS_ResponseError 1;
BA_ "GenSigSendType" SG_ 1712 FS_Taupunkt 0;
BA_ "Fehlerwert" SG_ 1712 FS_Taupunkt 1023;
BA_ "GenSigMissingSourceValue" SG_ 1712 FS_Taupunkt 1023;
BA_ "GenSigSendType" SG_ 1712 FS_Temp_Scheibe 0;
BA_ "Fehlerwert" SG_ 1712 FS_Temp_Scheibe 1023;
BA_ "GenSigMissingSourceValue" SG_ 1712 FS_Temp_Scheibe 1023;
BA_ "GenSigSendType" SG_ 1712 FS_Temp_Sensor 0;
BA_ "Fehlerwert" SG_ 1712 FS_Temp_Sensor 255;
BA_ "GenSigMissingSourceValue" SG_ 1712 FS_Temp_Sensor 255;
BA_ "GenSigSendType" SG_ 1505 BCM1_Aussen_Temp_ungef 0;
BA_ "GenSigStartValue" SG_ 1505 BCM1_Aussen_Temp_ungef 254;
BA_ "GenSigSwitchedByIgnition" SG_ 1505 BCM1_Aussen_Temp_ungef 0;
BA_ "Fehlerwert" SG_ 1505 BCM1_Aussen_Temp_ungef 255;
BA_ "GenSigSendType" SG_ 1505 BCM1_FStatus_Aussentemp_ungef 0;
BA_ "GenSigStartValue" SG_ 1505 BCM1_FStatus_Aussentemp_ungef 1;
BA_ "GenSigSwitchedByIgnition" SG_ 1505 BCM1_FStatus_Aussentemp_ungef 0;
BA_ "GenSigSendType" SG_ 1505 BCM1_Kompressorstrom_ist 0;
BA_ "GenSigStartValue" SG_ 1505 BCM1_Kompressorstrom_ist 254;
BA_ "GenSigSwitchedByIgnition" SG_ 1505 BCM1_Kompressorstrom_ist 0;
BA_ "Fehlerwert" SG_ 1505 BCM1_Kompressorstrom_ist 255;
BA_ "GenSigSendType" SG_ 1505 BCM1_OBD_FStatus_ATemp 0;
BA_ "GenSigSwitchedByIgnition" SG_ 1505 BCM1_OBD_FStatus_ATemp 0;
BA_ "GenSigSendType" SG_ 1505 BCM1_PTC_stufig_Status 0;
BA_ "GenSigStartValue" SG_ 1505 BCM1_PTC_stufig_Status 6;
BA_ "GenSigSwitchedByIgnition" SG_ 1505 BCM1_PTC_stufig_Status 0;
BA_ "Fehlerwert" SG_ 1505 BCM1_PTC_stufig_Status 7;
BA_ "GenSigSendType" SG_ 1505 BCM_Heizungsabsperrventil_Status 0;
BA_ "GenSigStartValue" SG_ 1505 BCM_Heizungsabsperrventil_Status 2;
BA_ "GenSigSwitchedByIgnition" SG_ 1505 BCM_Heizungsabsperrventil_Status 0;
BA_ "Fehlerwert" SG_ 1505 BCM_Heizungsabsperrventil_Status 3;
BA_ "GenSigSendType" SG_ 1505 BCM_Heizungspumpe_Status 0;
BA_ "GenSigStartValue" SG_ 1505 BCM_Heizungspumpe_Status 2;
BA_ "GenSigSwitchedByIgnition" SG_ 1505 BCM_Heizungspumpe_Status 0;
BA_ "Fehlerwert" SG_ 1505 BCM_Heizungspumpe_Status 3;
BA_ "GenSigSendType" SG_ 1505 BCM_Kompressorkupplung_Status 0;
BA_ "GenSigStartValue" SG_ 1505 BCM_Kompressorkupplung_Status 2;
BA_ "GenSigSwitchedByIgnition" SG_ 1505 BCM_Kompressorkupplung_Status 0;
BA_ "Fehlerwert" SG_ 1505 BCM_Kompressorkupplung_Status 3;
BA_ "GenSigSendType" SG_ 1717 FSA_Err_Defekt_HumSens_TNCTOC 0;
BA_ "GenSigStartValue" SG_ 1717 FSA_Err_Defekt_HumSens_TNCTOC 1;
BA_ "GenSigSendType" SG_ 1717 FSA_Err_Defekt_HumSense_TF 0;
BA_ "GenSigSendType" SG_ 1717 FSA_Err_Defekt_Tsens_TF 0;
BA_ "GenSigSendType" SG_ 1717 FSA_Err_RAMROM_Check_TF 0;
BA_ "GenSigSendType" SG_ 1717 FSA_Err_RAMROM_Check_TNCTOC 0;
BA_ "GenSigStartValue" SG_ 1717 FSA_Err_RAMROM_Check_TNCTOC 1;
BA_ "GenSigSendType" SG_ 1717 FSA_Err_Ueberspannung_TF 0;
BA_ "GenSigSendType" SG_ 1717 FSA_Err_Unterspannung_TF 0;
BA_ "GenSigSendType" SG_ 1717 FSA_ErrMemState 0;
BA_ "GenSigSendType" SG_ 1717 FSA_HW 0;
BA_ "GenSigSendType" SG_ 1717 FSA_Lokal_Bus_elektr_Fehler 0;
BA_ "GenSigSwitchedByIgnition" SG_ 1717 FSA_Lokal_Bus_elektr_Fehler 0;
BA_ "Fehlerwert" SG_ 1717 FSA_Lokal_Bus_elektr_Fehler 1;
BA_ "GenSigSendType" SG_ 1717 FSA_Lokal_Bus_Unterbrechung 0;
BA_ "GenSigSwitchedByIgnition" SG_ 1717 FSA_Lokal_Bus_Unterbrechung 0;
BA_ "Fehlerwert" SG_ 1717 FSA_Lokal_Bus_Unterbrechung 1;
BA_ "GenSigSendType" SG_ 1717 FSA_Luftfeuchte_rel 0;
BA_ "GenSigStartValue" SG_ 1717 FSA_Luftfeuchte_rel 254;
BA_ "Fehlerwert" SG_ 1717 FSA_Luftfeuchte_rel 255;
BA_ "GenSigSendType" SG_ 1717 FSA_Luftfeuchte_TF 0;
BA_ "GenSigSendType" SG_ 1717 FSA_Luftfeuchte_TNCTOC 0;
BA_ "GenSigStartValue" SG_ 1717 FSA_Luftfeuchte_TNCTOC 1;
BA_ "GenSigSendType" SG_ 1717 FSA_ResponseError 0;
BA_ "Fehlerwert" SG_ 1717 FSA_ResponseError 1;
BA_ "GenSigSendType" SG_ 1717 FSA_Sensorheizung_Status 0;
BA_ "GenSigSendType" SG_ 1717 FSA_SW 0;
BA_ "GenSigSendType" SG_ 1717 FSA_Taupunkt 0;
BA_ "GenSigStartValue" SG_ 1717 FSA_Taupunkt 1022;
BA_ "Fehlerwert" SG_ 1717 FSA_Taupunkt 1023;
BA_ "GenSigSendType" SG_ 1717 FSA_Temp_Luft 0;
BA_ "GenSigStartValue" SG_ 1717 FSA_Temp_Luft 1022;
BA_ "Fehlerwert" SG_ 1717 FSA_Temp_Luft 1023;
BA_ "GenSigSendType" SG_ 1717 FSA_Temp_Sensor 0;
BA_ "GenSigStartValue" SG_ 1717 FSA_Temp_Sensor 2046;
BA_ "Fehlerwert" SG_ 1717 FSA_Temp_Sensor 2047;
BA_ "GenSigSendType" SG_ 1717 FSA_Timeout 0;
BA_ "GenSigSwitchedByIgnition" SG_ 1717 FSA_Timeout 0;
BA_ "Fehlerwert" SG_ 1717 FSA_Timeout 1;
BA_ "GenSigSendType" SG_ 1513 AAU_Geblaese 0;
BA_ "GenSigStartValue" SG_ 1513 AAU_Geblaese 126;
BA_ "GenSigSwitchedByIgnition" SG_ 1513 AAU_Geblaese 0;
BA_ "Fehlerwert" SG_ 1513 AAU_Geblaese 127;
BA_ "GenSigSendType" SG_ 1513 DS_Kaeltemittel_P 0;
BA_ "GenSigStartValue" SG_ 1513 DS_Kaeltemittel_P 2046;
BA_ "GenSigSwitchedByIgnition" SG_ 1513 DS_Kaeltemittel_P 0;
BA_ "Fehlerwert" SG_ 1513 DS_Kaeltemittel_P 2047;
BA_ "GenSigSendType" SG_ 1513 DS_Status 0;
BA_ "GenSigStartValue" SG_ 1513 DS_Status 2;
BA_ "GenSigSwitchedByIgnition" SG_ 1513 DS_Status 0;
BA_ "Fehlerwert" SG_ 1513 DS_Status 3;
BA_ "GenSigSendType" SG_ 1513 ION_Status 0;
BA_ "GenSigStartValue" SG_ 1513 ION_Status 2;
BA_ "GenSigSendType" SG_ 1513 ION_Status_LED 0;
BA_ "GenSigSendType" SG_ 1513 ION_Status_Taster 0;
BA_ "GenSigSendType" SG_ 1295 KL_Heizbedarf 0;
BA_ "GenSigStartValue" SG_ 1295 KL_Heizbedarf 1022;
BA_ "GenSigSwitchedByIgnition" SG_ 1295 KL_Heizbedarf 0;
BA_ "Fehlerwert" SG_ 1295 KL_Heizbedarf 1023;
BA_ "GenSigSendType" SG_ 1295 KL_Heizenergie_instat_pred 0;
BA_ "GenSigStartValue" SG_ 1295 KL_Heizenergie_instat_pred 254;
BA_ "GenSigSwitchedByIgnition" SG_ 1295 KL_Heizenergie_instat_pred 0;
BA_ "Fehlerwert" SG_ 1295 KL_Heizenergie_instat_pred 255;
BA_ "GenSigSendType" SG_ 1295 KL_Heizleistg_stat_erw 0;
BA_ "GenSigStartValue" SG_ 1295 KL_Heizleistg_stat_erw 254;
BA_ "GenSigSwitchedByIgnition" SG_ 1295 KL_Heizleistg_stat_erw 0;
BA_ "Fehlerwert" SG_ 1295 KL_Heizleistg_stat_erw 255;
BA_ "GenSigSendType" SG_ 1295 KL_Kuehlbedarf 0;
BA_ "GenSigStartValue" SG_ 1295 KL_Kuehlbedarf 254;
BA_ "GenSigSwitchedByIgnition" SG_ 1295 KL_Kuehlbedarf 0;
BA_ "Fehlerwert" SG_ 1295 KL_Kuehlbedarf 255;
BA_ "GenSigSendType" SG_ 1295 KL_Kuehlenergie_instat_pred 0;
BA_ "GenSigStartValue" SG_ 1295 KL_Kuehlenergie_instat_pred 254;
BA_ "GenSigSwitchedByIgnition" SG_ 1295 KL_Kuehlenergie_instat_pred 0;
BA_ "Fehlerwert" SG_ 1295 KL_Kuehlenergie_instat_pred 255;
BA_ "GenSigSendType" SG_ 1295 KL_Kuehlleistg_stat_erw 0;
BA_ "GenSigStartValue" SG_ 1295 KL_Kuehlleistg_stat_erw 254;
BA_ "GenSigSwitchedByIgnition" SG_ 1295 KL_Kuehlleistg_stat_erw 0;
BA_ "Fehlerwert" SG_ 1295 KL_Kuehlleistg_stat_erw 255;
BA_ "GenSigSendType" SG_ 1295 KL_Leistungspriorisierung 0;
BA_ "GenSigSwitchedByIgnition" SG_ 1295 KL_Leistungspriorisierung 0;
BA_ "GenSigSendType" SG_ 1295 KL_PTC_ein 0;
BA_ "GenSigSwitchedByIgnition" SG_ 1295 KL_PTC_ein 0;
BA_ "GenSigSendType" SG_ 1295 KL_Verdampfertemperatur 0;
BA_ "GenSigStartValue" SG_ 1295 KL_Verdampfertemperatur 1022;
BA_ "GenSigSwitchedByIgnition" SG_ 1295 KL_Verdampfertemperatur 0;
BA_ "Fehlerwert" SG_ 1295 KL_Verdampfertemperatur 1023;
BA_ "GenSigSendType" SG_ 2589283474 KL_Eps_Innen 0;
BA_ "GenSigStartValue" SG_ 2589283474 KL_Eps_Innen 254;
BA_ "GenSigSwitchedByIgnition" SG_ 2589283474 KL_Eps_Innen 0;
BA_ "Fehlerwert" SG_ 2589283474 KL_Eps_Innen 255;
BA_ "GenSigSendType" SG_ 2589283474 KL_MMTR 3;
BA_ "GenSigSwitchedByIgnition" SG_ 2589283474 KL_MMTR 0;
BA_ "GenSigSendType" SG_ 2589283474 KL_MMTR_Status 3;
BA_ "GenSigStartValue" SG_ 2589283474 KL_MMTR_Status 14;
BA_ "GenSigSwitchedByIgnition" SG_ 2589283474 KL_MMTR_Status 0;
BA_ "Fehlerwert" SG_ 2589283474 KL_MMTR_Status 15;
BA_ "GenSigSendType" SG_ 2589283474 KL_Temp_vor_Verdampfer 3;
BA_ "GenSigStartValue" SG_ 2589283474 KL_Temp_vor_Verdampfer 126;
BA_ "GenSigSwitchedByIgnition" SG_ 2589283474 KL_Temp_vor_Verdampfer 0;
BA_ "Fehlerwert" SG_ 2589283474 KL_Temp_vor_Verdampfer 127;
BA_ "GenSigSendType" SG_ 2589283474 KL_Tempklappe_Fond_li 0;
BA_ "GenSigStartValue" SG_ 2589283474 KL_Tempklappe_Fond_li 254;
BA_ "GenSigSwitchedByIgnition" SG_ 2589283474 KL_Tempklappe_Fond_li 0;
BA_ "Fehlerwert" SG_ 2589283474 KL_Tempklappe_Fond_li 255;
BA_ "GenSigSendType" SG_ 2589283474 KL_Tempklappe_Fond_re 0;
BA_ "GenSigStartValue" SG_ 2589283474 KL_Tempklappe_Fond_re 254;
BA_ "GenSigSwitchedByIgnition" SG_ 2589283474 KL_Tempklappe_Fond_re 0;
BA_ "Fehlerwert" SG_ 2589283474 KL_Tempklappe_Fond_re 255;
BA_ "GenSigSendType" SG_ 2549088270 BCM1_Abschaltstufe 0;
BA_ "GenSigSwitchedByIgnition" SG_ 2549088270 BCM1_Abschaltstufe 0;
BA_ "GenSigSendType" SG_ 2549088270 BCM1_KD_Fehler 0;
BA_ "GenSigSwitchedByIgnition" SG_ 2549088270 BCM1_KD_Fehler 0;
BA_ "GenSigSendType" SG_ 2549088270 BCM1_KompSchutz 0;
BA_ "GenSigSwitchedByIgnition" SG_ 2549088270 BCM1_KompSchutz 0;
BA_ "GenSigSendType" SG_ 2549088270 BCM1_Nachlauftyp 0;
BA_ "GenSigStartValue" SG_ 2549088270 BCM1_Nachlauftyp 2;
BA_ "GenSigSwitchedByIgnition" SG_ 2549088270 BCM1_Nachlauftyp 0;
BA_ "GenSigSendType" SG_ 2549088270 BCM1_SNI 0;
BA_ "GenSigStartValue" SG_ 2549088270 BCM1_SNI 14;
BA_ "GenSigSwitchedByIgnition" SG_ 2549088270 BCM1_SNI 0;
BA_ "GenSigSendType" SG_ 2549088270 BCM1_Transport_Mode 0;
BA_ "GenSigSwitchedByIgnition" SG_ 2549088270 BCM1_Transport_Mode 0;
BA_ "GenSigSendType" SG_ 2549088270 KN_BCM1_BusKnockOutTimer 0;
BA_ "GenSigSwitchedByIgnition" SG_ 2549088270 KN_BCM1_BusKnockOutTimer 0;
BA_ "GenSigSendType" SG_ 2549088270 NM_BCM1_Lokalaktiv 0;
BA_ "GenSigSwitchedByIgnition" SG_ 2549088270 NM_BCM1_Lokalaktiv 0;
BA_ "GenSigSendType" SG_ 2549088270 NM_BCM1_Subsystemaktiv 0;
BA_ "GenSigSwitchedByIgnition" SG_ 2549088270 NM_BCM1_Subsystemaktiv 0;
BA_ "GenSigSendType" SG_ 2549088270 NM_BCM1_Wakeup 0;
BA_ "NWM-WakeupAllowed" SG_ 2549088270 NM_BCM1_Wakeup 1;
BA_ "GenSigSwitchedByIgnition" SG_ 2549088270 NM_BCM1_Wakeup 0;
BA_ "GenSigSendType" SG_ 2549088272 Gateway_Abschaltstufe 0;
BA_ "GenSigSwitchedByIgnition" SG_ 2549088272 Gateway_Abschaltstufe 0;
BA_ "GenSigSendType" SG_ 2549088272 Gateway_KompSchutz 0;
BA_ "GenSigSwitchedByIgnition" SG_ 2549088272 Gateway_KompSchutz 0;
BA_ "GenSigSendType" SG_ 2549088272 Gateway_Matrix_Generation 0;
BA_ "GenSigSwitchedByIgnition" SG_ 2549088272 Gateway_Matrix_Generation 0;
BA_ "GenSigSendType" SG_ 2549088272 Gateway_Matrix_Version 0;
BA_ "GenSigSwitchedByIgnition" SG_ 2549088272 Gateway_Matrix_Version 0;
BA_ "GenSigSendType" SG_ 2549088272 Gateway_Nachlauftyp 0;
BA_ "GenSigStartValue" SG_ 2549088272 Gateway_Nachlauftyp 2;
BA_ "GenSigSwitchedByIgnition" SG_ 2549088272 Gateway_Nachlauftyp 0;
BA_ "GenSigSendType" SG_ 2549088272 Gateway_SNI 0;
BA_ "GenSigStartValue" SG_ 2549088272 Gateway_SNI 16;
BA_ "GenSigSwitchedByIgnition" SG_ 2549088272 Gateway_SNI 0;
BA_ "GenSigSendType" SG_ 2549088272 Gateway_Transport_Mode 0;
BA_ "GenSigSwitchedByIgnition" SG_ 2549088272 Gateway_Transport_Mode 0;
BA_ "GenSigSendType" SG_ 2549088272 GW_KD_Fehler 0;
BA_ "GenSigSendType" SG_ 2549088272 NM_Gateway_Lokalaktiv 0;
BA_ "GenSigSwitchedByIgnition" SG_ 2549088272 NM_Gateway_Lokalaktiv 0;
BA_ "GenSigSendType" SG_ 2549088272 NM_Gateway_Subsystemaktiv 0;
BA_ "GenSigSendType" SG_ 2549088272 NM_Gateway_Wakeup 0;
BA_ "NWM-WakeupAllowed" SG_ 2549088272 NM_Gateway_Wakeup 1;
BA_ "GenSigSwitchedByIgnition" SG_ 2549088272 NM_Gateway_Wakeup 0;
BA_ "GenSigSendType" SG_ 2549088326 KL_KD_Fehler 0;
BA_ "GenSigSwitchedByIgnition" SG_ 2549088326 KL_KD_Fehler 0;
BA_ "GenSigSendType" SG_ 2549088326 Klima_Abschaltstufe 0;
BA_ "GenSigSwitchedByIgnition" SG_ 2549088326 Klima_Abschaltstufe 0;
BA_ "GenSigSendType" SG_ 2549088326 Klima_KompSchutz 0;
BA_ "GenSigSwitchedByIgnition" SG_ 2549088326 Klima_KompSchutz 0;
BA_ "GenSigSendType" SG_ 2549088326 Klima_Nachlauftyp 0;
BA_ "GenSigStartValue" SG_ 2549088326 Klima_Nachlauftyp 2;
BA_ "GenSigSwitchedByIgnition" SG_ 2549088326 Klima_Nachlauftyp 0;
BA_ "GenSigSendType" SG_ 2549088326 Klima_SNI 0;
BA_ "GenSigStartValue" SG_ 2549088326 Klima_SNI 70;
BA_ "GenSigSwitchedByIgnition" SG_ 2549088326 Klima_SNI 0;
BA_ "GenSigSendType" SG_ 2549088326 Klima_Transport_Mode 0;
BA_ "GenSigSwitchedByIgnition" SG_ 2549088326 Klima_Transport_Mode 0;
BA_ "GenSigSendType" SG_ 2549088326 KN_Klima_BusKnockOut 0;
BA_ "GenSigSwitchedByIgnition" SG_ 2549088326 KN_Klima_BusKnockOut 0;
BA_ "GenSigSendType" SG_ 2549088326 KN_Klima_BusKnockOutTimer 0;
BA_ "GenSigSwitchedByIgnition" SG_ 2549088326 KN_Klima_BusKnockOutTimer 0;
BA_ "GenSigSendType" SG_ 2549088326 KN_Klima_ECUKnockOut 0;
BA_ "GenSigSwitchedByIgnition" SG_ 2549088326 KN_Klima_ECUKnockOut 0;
BA_ "GenSigSendType" SG_ 2549088326 KN_Klima_ECUKnockOutTimer 0;
BA_ "GenSigSwitchedByIgnition" SG_ 2549088326 KN_Klima_ECUKnockOutTimer 0;
BA_ "GenSigSendType" SG_ 2549088326 NM_Klima_Lokalaktiv 0;
BA_ "GenSigSwitchedByIgnition" SG_ 2549088326 NM_Klima_Lokalaktiv 0;
BA_ "GenSigSendType" SG_ 2549088326 NM_Klima_Subsystemaktiv 0;
BA_ "GenSigSwitchedByIgnition" SG_ 2549088326 NM_Klima_Subsystemaktiv 0;
BA_ "GenSigSendType" SG_ 2549088326 NM_Klima_Wakeup 0;
BA_ "NWM-WakeupAllowed" SG_ 2549088326 NM_Klima_Wakeup 1;
BA_ "GenSigSwitchedByIgnition" SG_ 2549088326 NM_Klima_Wakeup 0;
BA_ "GenSigSendType" SG_ 2549088345 KN_Lift_BusKnockOut 0;
BA_ "GenSigSwitchedByIgnition" SG_ 2549088345 KN_Lift_BusKnockOut 0;
BA_ "GenSigSendType" SG_ 2549088345 KN_Lift_BusKnockOutTimer 0;
BA_ "GenSigSwitchedByIgnition" SG_ 2549088345 KN_Lift_BusKnockOutTimer 0;
BA_ "GenSigSendType" SG_ 2549088345 KN_Lift_ECUKnockOut 0;
BA_ "GenSigSwitchedByIgnition" SG_ 2549088345 KN_Lift_ECUKnockOut 0;
BA_ "GenSigSendType" SG_ 2549088345 KN_Lift_ECUKnockOutTimer 0;
BA_ "GenSigSwitchedByIgnition" SG_ 2549088345 KN_Lift_ECUKnockOutTimer 0;
BA_ "GenSigSendType" SG_ 2549088345 Lift_Abschaltstufe 0;
BA_ "GenSigSendType" SG_ 2549088345 Lift_KD_Fehler 0;
BA_ "GenSigSendType" SG_ 2549088345 Lift_KompSchutz 0;
BA_ "GenSigSendType" SG_ 2549088345 Lift_Lokalaktiv 0;
BA_ "GenSigSwitchedByIgnition" SG_ 2549088345 Lift_Lokalaktiv 0;
BA_ "GenSigSendType" SG_ 2549088345 Lift_Nachlauftyp 0;
BA_ "GenSigSendType" SG_ 2549088345 Lift_SNI 0;
BA_ "GenSigStartValue" SG_ 2549088345 Lift_SNI 89;
BA_ "GenSigSendType" SG_ 2549088345 Lift_Subsystemaktiv 0;
BA_ "GenSigSwitchedByIgnition" SG_ 2549088345 Lift_Subsystemaktiv 0;
BA_ "GenSigSendType" SG_ 2549088345 Lift_Transport_Mode 0;
BA_ "GenSigSendType" SG_ 2549088345 NM_Lift_Wakeup 0;
BA_ "NWM-WakeupAllowed" SG_ 2549088345 NM_Lift_Wakeup 1;
BA_ "GenSigSwitchedByIgnition" SG_ 2549088345 NM_Lift_Wakeup 0;
BA_ "GenSigSendType" SG_ 2549088452 KN_VAS_L_BusKnockOut 0;
BA_ "GenSigSwitchedByIgnition" SG_ 2549088452 KN_VAS_L_BusKnockOut 0;
BA_ "GenSigSendType" SG_ 2549088452 KN_VAS_L_BusKnockOutTimer 0;
BA_ "GenSigSwitchedByIgnition" SG_ 2549088452 KN_VAS_L_BusKnockOutTimer 0;
BA_ "GenSigSendType" SG_ 2549088452 KN_VAS_L_ECUKnockOut 0;
BA_ "GenSigSwitchedByIgnition" SG_ 2549088452 KN_VAS_L_ECUKnockOut 0;
BA_ "GenSigSendType" SG_ 2549088452 KN_VAS_L_ECUKnockOutTimer 0;
BA_ "GenSigSwitchedByIgnition" SG_ 2549088452 KN_VAS_L_ECUKnockOutTimer 0;
BA_ "GenSigSendType" SG_ 2549088452 NM_VAS_L_Lokalaktiv 0;
BA_ "GenSigSwitchedByIgnition" SG_ 2549088452 NM_VAS_L_Lokalaktiv 0;
BA_ "GenSigSendType" SG_ 2549088452 NM_VAS_L_Wakeup 0;
BA_ "NWM-WakeupAllowed" SG_ 2549088452 NM_VAS_L_Wakeup 1;
BA_ "GenSigSwitchedByIgnition" SG_ 2549088452 NM_VAS_L_Wakeup 0;
BA_ "GenSigSendType" SG_ 2549088452 VAS_L_Abschaltstufe 0;
BA_ "GenSigSwitchedByIgnition" SG_ 2549088452 VAS_L_Abschaltstufe 0;
BA_ "GenSigSendType" SG_ 2549088452 VAS_L_KD_Fehler 0;
BA_ "GenSigSwitchedByIgnition" SG_ 2549088452 VAS_L_KD_Fehler 0;
BA_ "GenSigSendType" SG_ 2549088452 VAS_L_KompSchutz 0;
BA_ "GenSigSwitchedByIgnition" SG_ 2549088452 VAS_L_KompSchutz 0;
BA_ "GenSigSendType" SG_ 2549088452 VAS_L_Nachlauftyp 0;
BA_ "GenSigStartValue" SG_ 2549088452 VAS_L_Nachlauftyp 2;
BA_ "GenSigSendType" SG_ 2549088452 VAS_L_SNI 0;
BA_ "GenSigStartValue" SG_ 2549088452 VAS_L_SNI 196;
BA_ "GenSigSwitchedByIgnition" SG_ 2549088452 VAS_L_SNI 0;
BA_ "GenSigSendType" SG_ 2549088452 VAS_L_Subsystemaktiv 0;
BA_ "GenSigSwitchedByIgnition" SG_ 2549088452 VAS_L_Subsystemaktiv 0;
BA_ "GenSigSendType" SG_ 2549088452 VAS_L_Transport_Mode 0;
BA_ "GenSigSwitchedByIgnition" SG_ 2549088452 VAS_L_Transport_Mode 0;
BA_ "GenSigSendType" SG_ 2549088453 KN_VAS_R_BusKnockOut 0;
BA_ "GenSigSwitchedByIgnition" SG_ 2549088453 KN_VAS_R_BusKnockOut 0;
BA_ "GenSigSendType" SG_ 2549088453 KN_VAS_R_BusKnockOutTimer 0;
BA_ "GenSigSwitchedByIgnition" SG_ 2549088453 KN_VAS_R_BusKnockOutTimer 0;
BA_ "GenSigSendType" SG_ 2549088453 KN_VAS_R_ECUKnockOut 0;
BA_ "GenSigSwitchedByIgnition" SG_ 2549088453 KN_VAS_R_ECUKnockOut 0;
BA_ "GenSigSendType" SG_ 2549088453 KN_VAS_R_ECUKnockOutTimer 0;
BA_ "GenSigSwitchedByIgnition" SG_ 2549088453 KN_VAS_R_ECUKnockOutTimer 0;
BA_ "GenSigSendType" SG_ 2549088453 NM_VAS_R_Lokalaktiv 0;
BA_ "GenSigSwitchedByIgnition" SG_ 2549088453 NM_VAS_R_Lokalaktiv 0;
BA_ "GenSigSendType" SG_ 2549088453 NM_VAS_R_Wakeup 0;
BA_ "NWM-WakeupAllowed" SG_ 2549088453 NM_VAS_R_Wakeup 1;
BA_ "GenSigSwitchedByIgnition" SG_ 2549088453 NM_VAS_R_Wakeup 0;
BA_ "GenSigSendType" SG_ 2549088453 VAS_R_Abschaltstufe 0;
BA_ "GenSigSwitchedByIgnition" SG_ 2549088453 VAS_R_Abschaltstufe 0;
BA_ "GenSigSendType" SG_ 2549088453 VAS_R_KD_Fehler 0;
BA_ "GenSigSwitchedByIgnition" SG_ 2549088453 VAS_R_KD_Fehler 0;
BA_ "GenSigSendType" SG_ 2549088453 VAS_R_KompSchutz 0;
BA_ "GenSigSwitchedByIgnition" SG_ 2549088453 VAS_R_KompSchutz 0;
BA_ "GenSigSendType" SG_ 2549088453 VAS_R_Nachlauftyp 0;
BA_ "GenSigStartValue" SG_ 2549088453 VAS_R_Nachlauftyp 2;
BA_ "GenSigSendType" SG_ 2549088453 VAS_R_SNI 0;
BA_ "GenSigStartValue" SG_ 2549088453 VAS_R_SNI 197;
BA_ "GenSigSwitchedByIgnition" SG_ 2549088453 VAS_R_SNI 0;
BA_ "GenSigSendType" SG_ 2549088453 VAS_R_Subsystemaktiv 0;
BA_ "GenSigSwitchedByIgnition" SG_ 2549088453 VAS_R_Subsystemaktiv 0;
BA_ "GenSigSendType" SG_ 2549088453 VAS_R_Transport_Mode 0;
BA_ "GenSigSwitchedByIgnition" SG_ 2549088453 VAS_R_Transport_Mode 0;
BA_ "GenSigSendType" SG_ 779 KBI_ABS_Lampe 0;
BA_ "GenSigSwitchedByIgnition" SG_ 779 KBI_ABS_Lampe 0;
BA_ "GenSigSendType" SG_ 779 KBI_Airbag_Lampe 0;
BA_ "GenSigSwitchedByIgnition" SG_ 779 KBI_Airbag_Lampe 0;
BA_ "GenSigSendType" SG_ 779 KBI_angez_Geschw 0;
BA_ "GenSigSwitchedByIgnition" SG_ 779 KBI_angez_Geschw 0;
BA_ "GenSigSendType" SG_ 779 KBI_Anzeigefehler_LDW 0;
BA_ "GenSigSwitchedByIgnition" SG_ 779 KBI_Anzeigefehler_LDW 0;
BA_ "GenSigSendType" SG_ 779 KBI_Anzeigefehler_NV 0;
BA_ "GenSigSwitchedByIgnition" SG_ 779 KBI_Anzeigefehler_NV 0;
BA_ "GenSigSendType" SG_ 779 KBI_Anzeigefehler_SWA 0;
BA_ "GenSigSwitchedByIgnition" SG_ 779 KBI_Anzeigefehler_SWA 0;
BA_ "GenSigSendType" SG_ 779 KBI_Anzeigestatus_ACC 0;
BA_ "GenSigSwitchedByIgnition" SG_ 779 KBI_Anzeigestatus_ACC 0;
BA_ "GenSigSendType" SG_ 779 KBI_Anzeigestatus_GRA 0;
BA_ "GenSigSwitchedByIgnition" SG_ 779 KBI_Anzeigestatus_GRA 0;
BA_ "Fehlerwert" SG_ 779 KBI_Anzeigestatus_GRA 3;
BA_ "GenSigSendType" SG_ 779 KBI_Anzeigestatus_LIM 0;
BA_ "GenSigSwitchedByIgnition" SG_ 779 KBI_Anzeigestatus_LIM 0;
BA_ "Fehlerwert" SG_ 779 KBI_Anzeigestatus_LIM 3;
BA_ "GenSigSendType" SG_ 779 KBI_ARA_in_Anzeige 0;
BA_ "GenSigSwitchedByIgnition" SG_ 779 KBI_ARA_in_Anzeige 0;
BA_ "GenSigSendType" SG_ 779 KBI_Bestaetigung_ESP_Off 3;
BA_ "GenSigSendType" SG_ 779 KBI_BKL_Lampe 0;
BA_ "GenSigSwitchedByIgnition" SG_ 779 KBI_BKL_Lampe 0;
BA_ "GenSigSendType" SG_ 779 KBI_Einheit_Tacho 0;
BA_ "GenSigSwitchedByIgnition" SG_ 779 KBI_Einheit_Tacho 0;
BA_ "GenSigSendType" SG_ 779 KBI_ESP_Lampe 3;
BA_ "GenSigSwitchedByIgnition" SG_ 779 KBI_ESP_Lampe 0;
BA_ "GenSigSendType" SG_ 779 KBI_Fehler_Anzeige_ACC 0;
BA_ "GenSigSwitchedByIgnition" SG_ 779 KBI_Fehler_Anzeige_ACC 0;
BA_ "GenSigSendType" SG_ 779 KBI_GRA_Hauptschalter 0;
BA_ "GenSigSwitchedByIgnition" SG_ 779 KBI_GRA_Hauptschalter 0;
BA_ "Fehlerwert" SG_ 779 KBI_GRA_Hauptschalter 3;
BA_ "GenSigSendType" SG_ 779 KBI_Handbremse 0;
BA_ "GenSigSwitchedByIgnition" SG_ 779 KBI_Handbremse 0;
BA_ "GenSigSendType" SG_ 779 KBI_im_Stellgliedtest 0;
BA_ "GenSigSwitchedByIgnition" SG_ 779 KBI_im_Stellgliedtest 0;
BA_ "GenSigSendType" SG_ 779 KBI_Konsistenz_ACC 0;
BA_ "GenSigSwitchedByIgnition" SG_ 779 KBI_Konsistenz_ACC 0;
BA_ "GenSigSendType" SG_ 779 KBI_Lenkung_Lampe 3;
BA_ "GenSigSwitchedByIgnition" SG_ 779 KBI_Lenkung_Lampe 0;
BA_ "GenSigSendType" SG_ 779 KBI_MFA_v_Einheit_01 0;
BA_ "GenSigSwitchedByIgnition" SG_ 779 KBI_MFA_v_Einheit_01 0;
BA_ "GenSigSendType" SG_ 779 KBI_NV_in_Anzeige 0;
BA_ "GenSigSwitchedByIgnition" SG_ 779 KBI_NV_in_Anzeige 0;
BA_ "GenSigSendType" SG_ 779 KBI_PLA_in_Anzeige 3;
BA_ "GenSigSwitchedByIgnition" SG_ 779 KBI_PLA_in_Anzeige 0;
BA_ "GenSigSendType" SG_ 779 KBI_SILA_gueltig 0;
BA_ "GenSigSwitchedByIgnition" SG_ 779 KBI_SILA_gueltig 0;
BA_ "GenSigSendType" SG_ 779 KBI_Systemstatus 0;
BA_ "GenSigSwitchedByIgnition" SG_ 779 KBI_Systemstatus 0;
BA_ "GenSigSendType" SG_ 779 KBI_Tankwarnung 3;
BA_ "GenSigSwitchedByIgnition" SG_ 779 KBI_Tankwarnung 0;
BA_ "GenSigSendType" SG_ 779 KBI_Tankwarnung_ungueltig 0;
BA_ "GenSigStartValue" SG_ 779 KBI_Tankwarnung_ungueltig 1;
BA_ "GenSigSwitchedByIgnition" SG_ 779 KBI_Tankwarnung_ungueltig 0;
BA_ "GenSigSendType" SG_ 779 KBI_Taster_Fahrwerk 3;
BA_ "GenSigSwitchedByIgnition" SG_ 779 KBI_Taster_Fahrwerk 0;
BA_ "GenSigSendType" SG_ 779 KBI_Taster_Lift 3;
BA_ "GenSigSwitchedByIgnition" SG_ 779 KBI_Taster_Lift 0;
BA_ "GenSigSendType" SG_ 779 KBI_V_Digital 0;
BA_ "GenSigSwitchedByIgnition" SG_ 779 KBI_V_Digital 0;
BA_ "GenSigSendType" SG_ 779 KBI_Vorglueh_System_Lampe 0;
BA_ "GenSigSwitchedByIgnition" SG_ 779 KBI_Vorglueh_System_Lampe 0;
BA_ "GenSigSendType" SG_ 779 Kombi_01_BZ 0;
BA_ "GenSigFuncType" SG_ 779 Kombi_01_BZ 1;
BA_ "GenSigSwitchedByIgnition" SG_ 779 Kombi_01_BZ 0;
BA_ "GenSigSendType" SG_ 1719 KBI_aktive_Laengsfunktion 3;
BA_ "GenSigSendType" SG_ 1719 KBI_Aussen_Temp_gef 0;
BA_ "GenSigStartValue" SG_ 1719 KBI_Aussen_Temp_gef 254;
BA_ "GenSigSwitchedByIgnition" SG_ 1719 KBI_Aussen_Temp_gef 0;
BA_ "Fehlerwert" SG_ 1719 KBI_Aussen_Temp_gef 255;
BA_ "GenSigSendType" SG_ 1719 KBI_FoD_PopUP_Quittiert 3;
BA_ "GenSigSendType" SG_ 1719 KBI_FStatus_Tank 0;
BA_ "GenSigSwitchedByIgnition" SG_ 1719 KBI_FStatus_Tank 0;
BA_ "GenSigSendType" SG_ 1719 KBI_GRA_im_ACC 3;
BA_ "GenSigSwitchedByIgnition" SG_ 1719 KBI_GRA_im_ACC 0;
BA_ "GenSigSendType" SG_ 1719 KBI_Inhalt_Tank 0;
BA_ "GenSigStartValue" SG_ 1719 KBI_Inhalt_Tank 126;
BA_ "GenSigSwitchedByIgnition" SG_ 1719 KBI_Inhalt_Tank 0;
BA_ "Fehlerwert" SG_ 1719 KBI_Inhalt_Tank 127;
BA_ "GenSigSendType" SG_ 1719 KBI_Kilometerstand 0;
BA_ "GenSigStartValue" SG_ 1719 KBI_Kilometerstand 1048574;
BA_ "GenSigSwitchedByIgnition" SG_ 1719 KBI_Kilometerstand 0;
BA_ "Fehlerwert" SG_ 1719 KBI_Kilometerstand 1048575;
BA_ "GenSigSendType" SG_ 1719 KBI_LVDS_Lock 3;
BA_ "GenSigSwitchedByIgnition" SG_ 1719 KBI_LVDS_Lock 0;
BA_ "GenSigSendType" SG_ 1719 KBI_Oelwechsel_durchgefuehrt 0;
BA_ "GenSigSwitchedByIgnition" SG_ 1719 KBI_Oelwechsel_durchgefuehrt 0;
BA_ "GenSigSendType" SG_ 1719 KBI_QBit_Aussen_Temp_gef 0;
BA_ "GenSigStartValue" SG_ 1719 KBI_QBit_Aussen_Temp_gef 1;
BA_ "GenSigSwitchedByIgnition" SG_ 1719 KBI_QBit_Aussen_Temp_gef 0;
BA_ "GenSigSendType" SG_ 1719 KBI_RDK_Kalibrier_Anf 3;
BA_ "GenSigSwitchedByIgnition" SG_ 1719 KBI_RDK_Kalibrier_Anf 0;
BA_ "GenSigSendType" SG_ 1719 KBI_Reserve_Warnung_Sek 3;
BA_ "GenSigSwitchedByIgnition" SG_ 1719 KBI_Reserve_Warnung_Sek 0;
BA_ "GenSigSendType" SG_ 1719 KBI_Standzeit_02 0;
BA_ "GenSigStartValue" SG_ 1719 KBI_Standzeit_02 131070;
BA_ "GenSigSwitchedByIgnition" SG_ 1719 KBI_Standzeit_02 0;
BA_ "Fehlerwert" SG_ 1719 KBI_Standzeit_02 131071;
BA_ "GenSigSendType" SG_ 1719 KBI_TA_gewaehlt_Fahrer 0;
BA_ "GenSigSendType" SG_ 2549874958 KS_BCM1_Req_Data 3;
BA_ "GenSigFuncType" SG_ 2549874958 KS_BCM1_Req_Data 9;
BA_ "GenSigSwitchedByIgnition" SG_ 2549874958 KS_BCM1_Req_Data 0;
BA_ "GenSigSendType" SG_ 2550006030 KS_BCM1_Resp_Data 3;
BA_ "GenSigFuncType" SG_ 2550006030 KS_BCM1_Resp_Data 9;
BA_ "GenSigSwitchedByIgnition" SG_ 2550006030 KS_BCM1_Resp_Data 0;
BA_ "GenSigSendType" SG_ 2549875140 KS_VAS_L_Req_Data 3;
BA_ "GenSigFuncType" SG_ 2549875140 KS_VAS_L_Req_Data 9;
BA_ "GenSigSwitchedByIgnition" SG_ 2549875140 KS_VAS_L_Req_Data 0;
BA_ "GenSigSendType" SG_ 2550006212 KS_VAS_L_Resp_Data 3;
BA_ "GenSigFuncType" SG_ 2550006212 KS_VAS_L_Resp_Data 9;
BA_ "GenSigSwitchedByIgnition" SG_ 2550006212 KS_VAS_L_Resp_Data 0;
BA_ "GenSigSendType" SG_ 2549875141 KS_VAS_R_Req_Data 3;
BA_ "GenSigFuncType" SG_ 2549875141 KS_VAS_R_Req_Data 9;
BA_ "GenSigSwitchedByIgnition" SG_ 2549875141 KS_VAS_R_Req_Data 0;
BA_ "GenSigSendType" SG_ 2550006213 KS_VAS_R_Resp_Data 3;
BA_ "GenSigFuncType" SG_ 2550006213 KS_VAS_R_Resp_Data 9;
BA_ "GenSigSwitchedByIgnition" SG_ 2550006213 KS_VAS_R_Resp_Data 0;
BA_ "GenSigSendType" SG_ 919 aLDW_FoD_Status 3;
BA_ "GenSigSwitchedByIgnition" SG_ 919 aLDW_FoD_Status 0;
BA_ "GenSigSendType" SG_ 919 EA_Warnblinken 0;
BA_ "GenSigSendType" SG_ 919 HC_Uss_Anforderung 0;
BA_ "GenSigSwitchedByIgnition" SG_ 919 HC_Uss_Anforderung 0;
BA_ "GenSigSendType" SG_ 919 LDW_Codierinfo_fuer_VLR 0;
BA_ "GenSigSendType" SG_ 919 LDW_DLC 0;
BA_ "GenSigStartValue" SG_ 919 LDW_DLC 250;
BA_ "GenSigSendType" SG_ 919 LDW_Frueh_Spaet 0;
BA_ "GenSigStartValue" SG_ 919 LDW_Frueh_Spaet 2;
BA_ "Fehlerwert" SG_ 919 LDW_Frueh_Spaet 3;
BA_ "GenSigSendType" SG_ 919 LDW_Gong 0;
BA_ "GenSigSendType" SG_ 919 LDW_Lernmodus 0;
BA_ "Fehlerwert" SG_ 919 LDW_Lernmodus 5;
BA_ "GenSigSendType" SG_ 919 LDW_Lernmodus_seitenabhaengig 3;
BA_ "GenSigSendType" SG_ 919 LDW_Seite_DLCTLC 0;
BA_ "GenSigSendType" SG_ 919 LDW_Status_LED_gelb 0;
BA_ "GenSigSendType" SG_ 919 LDW_Status_LED_gruen 0;
BA_ "GenSigSendType" SG_ 919 LDW_Texte 0;
BA_ "GenSigSendType" SG_ 919 LDW_TLC 0;
BA_ "GenSigStartValue" SG_ 919 LDW_TLC 31;
BA_ "GenSigSendType" SG_ 919 LKS_LED_an 0;
BA_ "GenSigSendType" SG_ 810 EPS_01_BZ 0;
BA_ "GenSigFuncType" SG_ 810 EPS_01_BZ 1;
BA_ "GenSigSwitchedByIgnition" SG_ 810 EPS_01_BZ 0;
BA_ "GenSigSendType" SG_ 810 EPS_01_CRC 0;
BA_ "GenSigFuncType" SG_ 810 EPS_01_CRC 2;
BA_ "GenSigSwitchedByIgnition" SG_ 810 EPS_01_CRC 0;
BA_ "GenSigSendType" SG_ 810 EPS_Anf_KL 0;
BA_ "GenSigSwitchedByIgnition" SG_ 810 EPS_Anf_KL 0;
BA_ "GenSigSendType" SG_ 810 EPS_ARA_Status 0;
BA_ "GenSigSwitchedByIgnition" SG_ 810 EPS_ARA_Status 0;
BA_ "GenSigSendType" SG_ 810 EPS_Charisma_FahrPr 0;
BA_ "GenSigSwitchedByIgnition" SG_ 810 EPS_Charisma_FahrPr 0;
BA_ "GenSigSendType" SG_ 810 EPS_Charisma_Status 0;
BA_ "GenSigSwitchedByIgnition" SG_ 810 EPS_Charisma_Status 0;
BA_ "GenSigSendType" SG_ 810 EPS_Endanschlag 0;
BA_ "Fehlerwert" SG_ 810 EPS_Endanschlag 3;
BA_ "GenSigSendType" SG_ 810 EPS_Fehlerlampe 0;
BA_ "GenSigSwitchedByIgnition" SG_ 810 EPS_Fehlerlampe 0;
BA_ "GenSigSendType" SG_ 810 EPS_Lenkerposition 0;
BA_ "GenSigFuncType" SG_ 810 EPS_Lenkerposition 8;
BA_ "GenSigSwitchedByIgnition" SG_ 810 EPS_Lenkerposition 0;
BA_ "GenSigSendType" SG_ 810 EPS_PLA_Status 0;
BA_ "GenSigSwitchedByIgnition" SG_ 810 EPS_PLA_Status 0;
BA_ "GenSigSendType" SG_ 810 EPS_PWR_Abbruch 0;
BA_ "GenSigSwitchedByIgnition" SG_ 810 EPS_PWR_Abbruch 0;
BA_ "GenSigSendType" SG_ 810 EPS_PWR_Fehler 0;
BA_ "GenSigSwitchedByIgnition" SG_ 810 EPS_PWR_Fehler 0;
BA_ "GenSigSendType" SG_ 810 EPS_SpannungsAnf 0;
BA_ "GenSigSwitchedByIgnition" SG_ 810 EPS_SpannungsAnf 0;
BA_ "GenSigSendType" SG_ 810 EPS_Warnungen 0;
BA_ "GenSigSwitchedByIgnition" SG_ 810 EPS_Warnungen 0;
BA_ "GenSigSendType" SG_ 160 EPS_04_BZ 0;
BA_ "GenSigFuncType" SG_ 160 EPS_04_BZ 1;
BA_ "GenSigSwitchedByIgnition" SG_ 160 EPS_04_BZ 0;
BA_ "GenSigSendType" SG_ 160 EPS_04_CRC 0;
BA_ "GenSigFuncType" SG_ 160 EPS_04_CRC 2;
BA_ "GenSigSwitchedByIgnition" SG_ 160 EPS_04_CRC 0;
BA_ "GenSigSendType" SG_ 160 EPS_AWA_Status 0;
BA_ "GenSigStartValue" SG_ 160 EPS_AWA_Status 14;
BA_ "GenSigSwitchedByIgnition" SG_ 160 EPS_AWA_Status 0;
BA_ "GenSigSendType" SG_ 160 EPS_FAS_Regelgroesse 0;
BA_ "GenSigStartValue" SG_ 160 EPS_FAS_Regelgroesse 62;
BA_ "GenSigSwitchedByIgnition" SG_ 160 EPS_FAS_Regelgroesse 0;
BA_ "Fehlerwert" SG_ 160 EPS_FAS_Regelgroesse 63;
BA_ "GenSigSendType" SG_ 160 EPS_FAS_VZ_Regelgroesse 0;
BA_ "GenSigSwitchedByIgnition" SG_ 160 EPS_FAS_VZ_Regelgroesse 0;
BA_ "GenSigSendType" SG_ 160 EPS_Lenkmoment_AbsReduz 0;
BA_ "GenSigStartValue" SG_ 160 EPS_Lenkmoment_AbsReduz 14;
BA_ "GenSigSwitchedByIgnition" SG_ 160 EPS_Lenkmoment_AbsReduz 0;
BA_ "Fehlerwert" SG_ 160 EPS_Lenkmoment_AbsReduz 15;
BA_ "GenSigSendType" SG_ 160 EPS_Motormoment 0;
BA_ "GenSigStartValue" SG_ 160 EPS_Motormoment 254;
BA_ "GenSigSwitchedByIgnition" SG_ 160 EPS_Motormoment 0;
BA_ "Fehlerwert" SG_ 160 EPS_Motormoment 255;
BA_ "GenSigSendType" SG_ 160 EPS_QBit_Zahnstangen_Pos 0;
BA_ "GenSigSwitchedByIgnition" SG_ 160 EPS_QBit_Zahnstangen_Pos 0;
BA_ "GenSigSendType" SG_ 160 EPS_STA_Status 0;
BA_ "GenSigStartValue" SG_ 160 EPS_STA_Status 14;
BA_ "GenSigSwitchedByIgnition" SG_ 160 EPS_STA_Status 0;
BA_ "GenSigSendType" SG_ 160 EPS_Versorgungsspannung 0;
BA_ "GenSigStartValue" SG_ 160 EPS_Versorgungsspannung 254;
BA_ "GenSigSwitchedByIgnition" SG_ 160 EPS_Versorgungsspannung 0;
BA_ "Fehlerwert" SG_ 160 EPS_Versorgungsspannung 255;
BA_ "GenSigSendType" SG_ 160 EPS_Versorgungsstatus 0;
BA_ "GenSigSwitchedByIgnition" SG_ 160 EPS_Versorgungsstatus 0;
BA_ "GenSigSendType" SG_ 160 EPS_VZ_Zahnstangenposition 0;
BA_ "GenSigSwitchedByIgnition" SG_ 160 EPS_VZ_Zahnstangenposition 0;
BA_ "GenSigSendType" SG_ 160 EPS_Zahnstangen_Pos 0;
BA_ "GenSigStartValue" SG_ 160 EPS_Zahnstangen_Pos 4094;
BA_ "GenSigSwitchedByIgnition" SG_ 160 EPS_Zahnstangen_Pos 0;
BA_ "Fehlerwert" SG_ 160 EPS_Zahnstangen_Pos 4095;
BA_ "GenSigSendType" SG_ 981 BCM1_Abblendlicht_Anf 0;
BA_ "GenSigSwitchedByIgnition" SG_ 981 BCM1_Abblendlicht_Anf 0;
BA_ "GenSigSendType" SG_ 981 BCM1_Adaptive_Lichtvert_Anf 0;
BA_ "GenSigSwitchedByIgnition" SG_ 981 BCM1_Adaptive_Lichtvert_Anf 0;
BA_ "GenSigSendType" SG_ 981 BCM1_Allwetterlicht_Anf 0;
BA_ "GenSigSwitchedByIgnition" SG_ 981 BCM1_Allwetterlicht_Anf 0;
BA_ "GenSigSendType" SG_ 981 BCM1_Animationssperrung 3;
BA_ "GenSigStartValue" SG_ 981 BCM1_Animationssperrung 1;
BA_ "GenSigSwitchedByIgnition" SG_ 981 BCM1_Animationssperrung 0;
BA_ "GenSigSendType" SG_ 981 BCM1_Autobahnlicht_Anf 0;
BA_ "GenSigSwitchedByIgnition" SG_ 981 BCM1_Autobahnlicht_Anf 0;
BA_ "GenSigSendType" SG_ 981 BCM1_CH_aktiv 0;
BA_ "NWM-WakeupAllowed" SG_ 981 BCM1_CH_aktiv 1;
BA_ "GenSigSwitchedByIgnition" SG_ 981 BCM1_CH_aktiv 0;
BA_ "GenSigSendType" SG_ 981 BCM1_CH_LH_aktiv 0;
BA_ "GenSigSwitchedByIgnition" SG_ 981 BCM1_CH_LH_aktiv 0;
BA_ "GenSigSendType" SG_ 981 BCM1_Fernlicht_Anf 0;
BA_ "GenSigSwitchedByIgnition" SG_ 981 BCM1_Fernlicht_Anf 0;
BA_ "GenSigSendType" SG_ 981 BCM1_FOD_Sperrung_Animationen_HL 3;
BA_ "GenSigStartValue" SG_ 981 BCM1_FOD_Sperrung_Animationen_HL 2;
BA_ "GenSigSendType" SG_ 981 BCM1_FoD_Sperrung_WiBli 3;
BA_ "GenSigStartValue" SG_ 981 BCM1_FoD_Sperrung_WiBli 2;
BA_ "GenSigSendType" SG_ 981 BCM1_Gleitende_Leuchtw_Anf 3;
BA_ "GenSigSwitchedByIgnition" SG_ 981 BCM1_Gleitende_Leuchtw_Anf 0;
BA_ "GenSigSendType" SG_ 981 BCM1_GLW_Fernlicht_Anf 3;
BA_ "GenSigSwitchedByIgnition" SG_ 981 BCM1_GLW_Fernlicht_Anf 0;
BA_ "GenSigSendType" SG_ 981 BCM1_Kurvenlicht_links_Anf 0;
BA_ "GenSigSwitchedByIgnition" SG_ 981 BCM1_Kurvenlicht_links_Anf 0;
BA_ "GenSigSendType" SG_ 981 BCM1_Kurvenlicht_rechts_Anf 0;
BA_ "GenSigSwitchedByIgnition" SG_ 981 BCM1_Kurvenlicht_rechts_Anf 0;
BA_ "GenSigSendType" SG_ 981 BCM1_LH_aktiv 0;
BA_ "NWM-WakeupAllowed" SG_ 981 BCM1_LH_aktiv 1;
BA_ "GenSigSwitchedByIgnition" SG_ 981 BCM1_LH_aktiv 0;
BA_ "GenSigSendType" SG_ 981 BCM1_Nebellicht_Anf 0;
BA_ "GenSigSwitchedByIgnition" SG_ 981 BCM1_Nebellicht_Anf 0;
BA_ "GenSigSendType" SG_ 981 BCM1_Nebelschluss_Ahg_Anf 0;
BA_ "GenSigSwitchedByIgnition" SG_ 981 BCM1_Nebelschluss_Ahg_Anf 0;
BA_ "GenSigSendType" SG_ 981 BCM1_Nebelschluss_Fzg_Anf 0;
BA_ "GenSigSwitchedByIgnition" SG_ 981 BCM1_Nebelschluss_Fzg_Anf 0;
BA_ "GenSigSendType" SG_ 981 BCM1_Parklicht_li_Anf 0;
BA_ "GenSigSwitchedByIgnition" SG_ 981 BCM1_Parklicht_li_Anf 0;
BA_ "GenSigSendType" SG_ 981 BCM1_Parklicht_re_Anf 0;
BA_ "GenSigSwitchedByIgnition" SG_ 981 BCM1_Parklicht_re_Anf 0;
BA_ "GenSigSendType" SG_ 981 BCM1_Regenlicht_Anf 0;
BA_ "GenSigSwitchedByIgnition" SG_ 981 BCM1_Regenlicht_Anf 0;
BA_ "GenSigSendType" SG_ 981 BCM1_Schlusslicht_Anf 0;
BA_ "GenSigSwitchedByIgnition" SG_ 981 BCM1_Schlusslicht_Anf 0;
BA_ "GenSigSendType" SG_ 981 BCM1_Schlusslicht_Signatur 0;
BA_ "GenSigSwitchedByIgnition" SG_ 981 BCM1_Schlusslicht_Signatur 0;
BA_ "GenSigSendType" SG_ 981 BCM1_Signaturlicht_Anf 0;
BA_ "GenSigSwitchedByIgnition" SG_ 981 BCM1_Signaturlicht_Anf 0;
BA_ "GenSigSendType" SG_ 981 BCM1_Standlicht_Anf 0;
BA_ "GenSigSwitchedByIgnition" SG_ 981 BCM1_Standlicht_Anf 0;
BA_ "GenSigSendType" SG_ 981 BCM1_Tagfahrlicht_Anf 0;
BA_ "GenSigSwitchedByIgnition" SG_ 981 BCM1_Tagfahrlicht_Anf 0;
BA_ "GenSigSendType" SG_ 981 BCM1_Touristen_Licht_Anf 0;
BA_ "GenSigSwitchedByIgnition" SG_ 981 BCM1_Touristen_Licht_Anf 0;
BA_ "GenSigSendType" SG_ 981 BCM1_Umfeldleuchten_Anf 0;
BA_ "GenSigSwitchedByIgnition" SG_ 981 BCM1_Umfeldleuchten_Anf 0;
BA_ "GenSigSendType" SG_ 981 BCM_Rueckfahrlicht_Anf 0;
BA_ "GenSigSwitchedByIgnition" SG_ 981 BCM_Rueckfahrlicht_Anf 0;
BA_ "GenSigSendType" SG_ 981 Licht_Anf_01_BZ 0;
BA_ "GenSigFuncType" SG_ 981 Licht_Anf_01_BZ 1;
BA_ "GenSigSwitchedByIgnition" SG_ 981 Licht_Anf_01_BZ 0;
BA_ "GenSigSendType" SG_ 981 Licht_Anf_01_CRC 0;
BA_ "GenSigFuncType" SG_ 981 Licht_Anf_01_CRC 2;
BA_ "GenSigSwitchedByIgnition" SG_ 981 Licht_Anf_01_CRC 0;
BA_ "GenSigSendType" SG_ 982 BCM2_Bremsl_durch_ECD 0;
BA_ "GenSigSwitchedByIgnition" SG_ 982 BCM2_Bremsl_durch_ECD 0;
BA_ "GenSigSendType" SG_ 982 LH_3_Bremsl_def 0;
BA_ "GenSigSwitchedByIgnition" SG_ 982 LH_3_Bremsl_def 0;
BA_ "GenSigSendType" SG_ 982 LH_Aussenlicht_def 0;
BA_ "GenSigSwitchedByIgnition" SG_ 982 LH_Aussenlicht_def 0;
BA_ "GenSigSendType" SG_ 982 LH_Blinker_HL_akt 0;
BA_ "GenSigSwitchedByIgnition" SG_ 982 LH_Blinker_HL_akt 0;
BA_ "GenSigSendType" SG_ 982 LH_Blinker_HR_akt 0;
BA_ "GenSigSwitchedByIgnition" SG_ 982 LH_Blinker_HR_akt 0;
BA_ "GenSigSendType" SG_ 982 LH_Blinker_li_def 0;
BA_ "GenSigSwitchedByIgnition" SG_ 982 LH_Blinker_li_def 0;
BA_ "GenSigSendType" SG_ 982 LH_Blinker_re_def 0;
BA_ "GenSigSwitchedByIgnition" SG_ 982 LH_Blinker_re_def 0;
BA_ "GenSigSendType" SG_ 982 LH_Brems_Blk_li_def 0;
BA_ "GenSigSwitchedByIgnition" SG_ 982 LH_Brems_Blk_li_def 0;
BA_ "GenSigSendType" SG_ 982 LH_Brems_Blk_re_def 0;
BA_ "GenSigSwitchedByIgnition" SG_ 982 LH_Brems_Blk_re_def 0;
BA_ "GenSigSendType" SG_ 982 LH_Bremsl_li_def 0;
BA_ "GenSigSwitchedByIgnition" SG_ 982 LH_Bremsl_li_def 0;
BA_ "GenSigSendType" SG_ 982 LH_Bremsl_li_ges_def 0;
BA_ "GenSigSwitchedByIgnition" SG_ 982 LH_Bremsl_li_ges_def 0;
BA_ "GenSigSendType" SG_ 982 LH_Bremsl_mi_def 0;
BA_ "GenSigSwitchedByIgnition" SG_ 982 LH_Bremsl_mi_def 0;
BA_ "GenSigSendType" SG_ 982 LH_Bremsl_re_def 0;
BA_ "GenSigSwitchedByIgnition" SG_ 982 LH_Bremsl_re_def 0;
BA_ "GenSigSendType" SG_ 982 LH_Bremsl_re_ges_def 0;
BA_ "GenSigSwitchedByIgnition" SG_ 982 LH_Bremsl_re_ges_def 0;
BA_ "GenSigSendType" SG_ 982 LH_Bremslicht_H_aktiv 0;
BA_ "GenSigSwitchedByIgnition" SG_ 982 LH_Bremslicht_H_aktiv 0;
BA_ "GenSigSendType" SG_ 982 LH_Diag_LED_li_def 0;
BA_ "GenSigSwitchedByIgnition" SG_ 982 LH_Diag_LED_li_def 0;
BA_ "GenSigSendType" SG_ 982 LH_Diag_LED_re_def 0;
BA_ "GenSigSwitchedByIgnition" SG_ 982 LH_Diag_LED_re_def 0;
BA_ "GenSigSendType" SG_ 982 LH_Diag_Status_li_def 0;
BA_ "GenSigSwitchedByIgnition" SG_ 982 LH_Diag_Status_li_def 0;
BA_ "GenSigSendType" SG_ 982 LH_Diag_Status_re_def 0;
BA_ "GenSigSwitchedByIgnition" SG_ 982 LH_Diag_Status_re_def 0;
BA_ "GenSigSendType" SG_ 982 LH_Kennzl_def 0;
BA_ "GenSigSwitchedByIgnition" SG_ 982 LH_Kennzl_def 0;
BA_ "GenSigSendType" SG_ 982 LH_Nebel_li_def 0;
BA_ "GenSigSwitchedByIgnition" SG_ 982 LH_Nebel_li_def 0;
BA_ "GenSigSendType" SG_ 982 LH_Nebel_mi_def 0;
BA_ "GenSigSwitchedByIgnition" SG_ 982 LH_Nebel_mi_def 0;
BA_ "GenSigSendType" SG_ 982 LH_Nebel_re_def 0;
BA_ "GenSigSwitchedByIgnition" SG_ 982 LH_Nebel_re_def 0;
BA_ "GenSigSendType" SG_ 982 LH_Nebelschluss_aktiv 0;
BA_ "GenSigSwitchedByIgnition" SG_ 982 LH_Nebelschluss_aktiv 0;
BA_ "GenSigSendType" SG_ 982 LH_Parklicht_HL_aktiv 0;
BA_ "GenSigSwitchedByIgnition" SG_ 982 LH_Parklicht_HL_aktiv 0;
BA_ "GenSigSendType" SG_ 982 LH_Parklicht_HR_aktiv 0;
BA_ "GenSigSwitchedByIgnition" SG_ 982 LH_Parklicht_HR_aktiv 0;
BA_ "GenSigSendType" SG_ 982 LH_Rueckf_li_def 0;
BA_ "GenSigSwitchedByIgnition" SG_ 982 LH_Rueckf_li_def 0;
BA_ "GenSigSendType" SG_ 982 LH_Rueckf_mi_def 0;
BA_ "GenSigSwitchedByIgnition" SG_ 982 LH_Rueckf_mi_def 0;
BA_ "GenSigSendType" SG_ 982 LH_Rueckf_re_def 0;
BA_ "GenSigSwitchedByIgnition" SG_ 982 LH_Rueckf_re_def 0;
BA_ "GenSigSendType" SG_ 982 LH_Rueckfahrlicht_aktiv 0;
BA_ "GenSigSwitchedByIgnition" SG_ 982 LH_Rueckfahrlicht_aktiv 0;
BA_ "GenSigSendType" SG_ 982 LH_Schluss_Brems_li_def 0;
BA_ "GenSigSwitchedByIgnition" SG_ 982 LH_Schluss_Brems_li_def 0;
BA_ "GenSigSendType" SG_ 982 LH_Schluss_Brems_mi_def 0;
BA_ "GenSigSwitchedByIgnition" SG_ 982 LH_Schluss_Brems_mi_def 0;
BA_ "GenSigSendType" SG_ 982 LH_Schluss_Brems_Nebel_li_def 0;
BA_ "GenSigSwitchedByIgnition" SG_ 982 LH_Schluss_Brems_Nebel_li_def 0;
BA_ "GenSigSendType" SG_ 982 LH_Schluss_Brems_Nebel_re_def 0;
BA_ "GenSigSwitchedByIgnition" SG_ 982 LH_Schluss_Brems_Nebel_re_def 0;
BA_ "GenSigSendType" SG_ 982 LH_Schluss_Brems_re_def 0;
BA_ "GenSigSwitchedByIgnition" SG_ 982 LH_Schluss_Brems_re_def 0;
BA_ "GenSigSendType" SG_ 982 LH_Schluss_Nebel_li_def 0;
BA_ "GenSigSwitchedByIgnition" SG_ 982 LH_Schluss_Nebel_li_def 0;
BA_ "GenSigSendType" SG_ 982 LH_Schluss_Nebel_re_def 0;
BA_ "GenSigSwitchedByIgnition" SG_ 982 LH_Schluss_Nebel_re_def 0;
BA_ "GenSigSendType" SG_ 982 LH_Schlusslicht_li_def 0;
BA_ "GenSigSwitchedByIgnition" SG_ 982 LH_Schlusslicht_li_def 0;
BA_ "GenSigSendType" SG_ 982 LH_Schlusslicht_mi_def 0;
BA_ "GenSigSwitchedByIgnition" SG_ 982 LH_Schlusslicht_mi_def 0;
BA_ "GenSigSendType" SG_ 982 LH_Schlusslicht_re_def 0;
BA_ "GenSigSwitchedByIgnition" SG_ 982 LH_Schlusslicht_re_def 0;
BA_ "GenSigSendType" SG_ 982 LH_SL_BRL_BLK_li_def 0;
BA_ "GenSigSwitchedByIgnition" SG_ 982 LH_SL_BRL_BLK_li_def 0;
BA_ "GenSigSendType" SG_ 982 LH_SL_BRL_BLK_re_def 0;
BA_ "GenSigSwitchedByIgnition" SG_ 982 LH_SL_BRL_BLK_re_def 0;
BA_ "GenSigSendType" SG_ 982 LH_Standlicht_H_aktiv 0;
BA_ "GenSigSwitchedByIgnition" SG_ 982 LH_Standlicht_H_aktiv 0;
BA_ "GenSigSendType" SG_ 982 LH_Zusatzschlussl_def 0;
BA_ "GenSigSwitchedByIgnition" SG_ 982 LH_Zusatzschlussl_def 0;
BA_REL_ "GenSigTimeoutTime" BU_SG_REL_ BCM1 SG_ 2589283621 KL_FlHz_Soll_VL 5000;
BA_REL_ "GenSigTimeoutTime" BU_SG_REL_ BCM1 SG_ 2589283621 KL_FlHz_Soll_HL 5000;
BA_REL_ "GenSigTimeoutTime" BU_SG_REL_ BCM1 SG_ 2589283621 KL_FlHz_Soll_VR 5000;
BA_REL_ "GenSigTimeoutTime" BU_SG_REL_ BCM1 SG_ 2589283621 KL_FlHz_Soll_HR 5000;
BA_REL_ "GenSigTimeoutTime" BU_SG_REL_ BCM1 SG_ 2589284046 KL_SSC_Status_VL 5000;
BA_REL_ "GenSigTimeoutTime" BU_SG_REL_ BCM1 SG_ 2589284046 KL_SSC_Status_VR 5000;
BA_REL_ "GenSigTimeoutTime" BU_SG_REL_ BCM1 SG_ 2589284046 KL_SH_LS1_PWM 5000;
BA_REL_ "GenSigTimeoutTime" BU_SG_REL_ BCM1 SG_ 2589284046 KL_SH_LL1_PWM 5000;
BA_REL_ "GenSigTimeoutTime" BU_SG_REL_ BCM1 SG_ 2589284046 KL_SL_LS1_PWM 5000;
BA_REL_ "GenSigTimeoutTime" BU_SG_REL_ BCM1 SG_ 2589284046 KL_SL_LL1_PWM 5000;
BA_REL_ "GenSigTimeoutTime" BU_SG_REL_ BCM1 SG_ 2589284046 KL_SH_RS1_PWM 5000;
BA_REL_ "GenSigTimeoutTime" BU_SG_REL_ BCM1 SG_ 2589284046 KL_SH_RL1_PWM 5000;
BA_REL_ "GenSigTimeoutTime" BU_SG_REL_ BCM1 SG_ 2589284046 KL_SL_RS1_PWM 5000;
BA_REL_ "GenSigTimeoutTime" BU_SG_REL_ BCM1 SG_ 2589284046 KL_SL_RL1_PWM 5000;
BA_REL_ "GenSigTimeoutTime" BU_SG_REL_ BCM1 SG_ 992 KL_SL_Soll_hl 1000;
BA_REL_ "GenSigTimeoutTime" BU_SG_REL_ BCM1 SG_ 992 KL_SL_Soll_hr 1000;
BA_REL_ "GenSigTimeoutTime" BU_SG_REL_ BCM1 SG_ 992 KL_SH_Soll_hl 1000;
BA_REL_ "GenSigTimeoutTime" BU_SG_REL_ BCM1 SG_ 992 KL_SH_Soll_hr 1000;
BA_REL_ "GenSigTimeoutTime" BU_SG_REL_ BCM1 SG_ 779 KBI_ESP_Lampe 2000;
BA_REL_ "GenSigTimeoutTime" BU_SG_REL_ BCM1 SG_ 779 KBI_Tankwarnung 2000;
BA_REL_ "GenSigTimeoutTime" BU_SG_REL_ BCM1 SG_ 779 KBI_PLA_in_Anzeige 2000;
BA_REL_ "GenSigTimeoutTime" BU_SG_REL_ BCM1 SG_ 779 KBI_ARA_in_Anzeige 2000;
BA_REL_ "GenSigTimeoutTime" BU_SG_REL_ BCM1 SG_ 1719 KBI_Standzeit_02 5000;
BA_REL_ "GenSigTimeoutTime" BU_SG_REL_ BCM1 SG_ 1719 KBI_QBit_Aussen_Temp_gef 5000;
BA_REL_ "GenSigTimeoutTime" BU_SG_REL_ BCM1 SG_ 1719 KBI_Aussen_Temp_gef 5000;
BA_REL_ "GenSigTimeoutTime" BU_SG_REL_ BCM1 SG_ 919 HC_Uss_Anforderung 800;
BA_REL_ "GenSigTimeoutTime" BU_SG_REL_ BCM1 SG_ 919 LKS_LED_an 800;
BA_REL_ "GenSigTimeoutTime" BU_SG_REL_ BCM1 SG_ 810 EPS_01_CRC 500;
BA_REL_ "GenSigTimeoutTime" BU_SG_REL_ BCM1 SG_ 810 EPS_01_BZ 500;
BA_REL_ "GenSigTimeoutTime" BU_SG_REL_ BCM1 SG_ 810 EPS_PWR_Abbruch 500;
BA_REL_ "GenSigTimeoutTime" BU_SG_REL_ BCM1 SG_ 810 EPS_PWR_Fehler 500;
BA_REL_ "GenSigTimeoutTime" BU_SG_REL_ BCM1 SG_ 810 EPS_PLA_Status 500;
BA_REL_ "GenSigTimeoutTime" BU_SG_REL_ BCM1 SG_ 810 EPS_ARA_Status 500;
BA_REL_ "GenSigTimeoutTime" BU_SG_REL_ BCM1 SG_ 160 EPS_04_CRC 500;
BA_REL_ "GenSigTimeoutTime" BU_SG_REL_ BCM1 SG_ 160 EPS_04_BZ 500;
BA_REL_ "GenSigTimeoutTime" BU_SG_REL_ BCM1 SG_ 160 EPS_Lenkmoment_AbsReduz 500;
BA_REL_ "GenSigTimeoutTime" BU_SG_REL_ BCM1 SG_ 160 EPS_Zahnstangen_Pos 500;
BA_REL_ "GenSigTimeoutTime" BU_SG_REL_ BCM1 SG_ 160 EPS_VZ_Zahnstangenposition 500;
BA_REL_ "GenSigTimeoutTime" BU_SG_REL_ BCM1 SG_ 160 EPS_QBit_Zahnstangen_Pos 500;
BA_REL_ "GenSigTimeoutTime" BU_SG_REL_ BCM1 SG_ 982 LH_Nebelschluss_aktiv 1000;
BA_REL_ "GenSigTimeoutTime" BU_SG_REL_ Gateway SG_ 2589283621 KL_NV_Energie_Anf 5000;
BA_REL_ "GenSigTimeoutTime" BU_SG_REL_ Gateway SG_ 2589283621 KL_FlHz_Soll_VL 5000;
BA_REL_ "GenSigTimeoutTime" BU_SG_REL_ Gateway SG_ 2589283621 KL_FlHz_Soll_HL 5000;
BA_REL_ "GenSigTimeoutTime" BU_SG_REL_ Gateway SG_ 2589283621 KL_FlHz_Soll_VR 5000;
BA_REL_ "GenSigTimeoutTime" BU_SG_REL_ Gateway SG_ 2589283621 KL_FlHz_Soll_HR 5000;
BA_REL_ "GenSigTimeoutTime" BU_SG_REL_ Gateway SG_ 2589283621 KL_ECO_PRO_Aktiv 5000;
BA_REL_ "GenSigTimeoutTime" BU_SG_REL_ Gateway SG_ 2589283621 KL_ACmax_Aktiv 5000;
BA_REL_ "GenSigTimeoutTime" BU_SG_REL_ Gateway SG_ 2589283621 KL_ECO_Aktiv 5000;
BA_REL_ "GenSigTimeoutTime" BU_SG_REL_ Gateway SG_ 992 KL_SL_Soll_hl 1000;
BA_REL_ "GenSigTimeoutTime" BU_SG_REL_ Gateway SG_ 992 KL_SL_Soll_hr 1000;
BA_REL_ "GenSigTimeoutTime" BU_SG_REL_ Gateway SG_ 992 KL_SH_Soll_hl 1000;
BA_REL_ "GenSigTimeoutTime" BU_SG_REL_ Gateway SG_ 992 KL_SH_Soll_hr 1000;
BA_REL_ "GenSigTimeoutTime" BU_SG_REL_ Gateway SG_ 1505 BCM1_Aussen_Temp_ungef 2000;
BA_REL_ "GenSigTimeoutTime" BU_SG_REL_ Gateway SG_ 1505 BCM1_PTC_stufig_Status 2000;
BA_REL_ "GenSigTimeoutTime" BU_SG_REL_ Gateway SG_ 1717 FSA_Luftfeuchte_rel 5000;
BA_REL_ "GenSigTimeoutTime" BU_SG_REL_ Gateway SG_ 1513 DS_Kaeltemittel_P 2000;
BA_REL_ "GenSigTimeoutTime" BU_SG_REL_ Gateway SG_ 1513 ION_Status 2000;
BA_REL_ "GenSigTimeoutTime" BU_SG_REL_ Gateway SG_ 1513 ION_Status_LED 2000;
BA_REL_ "GenSigTimeoutTime" BU_SG_REL_ Gateway SG_ 1513 AAU_Geblaese 2000;
BA_REL_ "GenSigTimeoutTime" BU_SG_REL_ Gateway SG_ 1513 ION_Status_Taster 2000;
BA_REL_ "GenSigTimeoutTime" BU_SG_REL_ Gateway SG_ 1295 KL_Heizbedarf 1000;
BA_REL_ "GenSigTimeoutTime" BU_SG_REL_ Gateway SG_ 1295 KL_Kuehlbedarf 1000;
BA_REL_ "GenSigTimeoutTime" BU_SG_REL_ Gateway SG_ 1295 KL_Kuehlleistg_stat_erw 1000;
BA_REL_ "GenSigTimeoutTime" BU_SG_REL_ Gateway SG_ 2549088270 BCM1_Nachlauftyp 5000;
BA_REL_ "GenSigTimeoutTime" BU_SG_REL_ Gateway SG_ 2549088270 BCM1_SNI 5000;
BA_REL_ "GenSigTimeoutTime" BU_SG_REL_ Gateway SG_ 2549088270 KN_BCM1_BusKnockOutTimer 5000;
BA_REL_ "GenSigTimeoutTime" BU_SG_REL_ Gateway SG_ 2549088270 NM_BCM1_Lokalaktiv 5000;
BA_REL_ "GenSigTimeoutTime" BU_SG_REL_ Gateway SG_ 2549088270 NM_BCM1_Subsystemaktiv 5000;
BA_REL_ "GenSigTimeoutTime" BU_SG_REL_ Gateway SG_ 2549088270 BCM1_KD_Fehler 2500;
BA_REL_ "GenSigTimeoutTime" BU_SG_REL_ Gateway SG_ 2549088326 Klima_Nachlauftyp 5000;
BA_REL_ "GenSigTimeoutTime" BU_SG_REL_ Gateway SG_ 2549088326 Klima_SNI 5000;
BA_REL_ "GenSigTimeoutTime" BU_SG_REL_ Gateway SG_ 2549088326 KN_Klima_ECUKnockOutTimer 5000;
BA_REL_ "GenSigTimeoutTime" BU_SG_REL_ Gateway SG_ 2549088326 KN_Klima_BusKnockOut 5000;
BA_REL_ "GenSigTimeoutTime" BU_SG_REL_ Gateway SG_ 2549088326 KN_Klima_BusKnockOutTimer 5000;
BA_REL_ "GenSigTimeoutTime" BU_SG_REL_ Gateway SG_ 2549088326 KN_Klima_ECUKnockOut 5000;
BA_REL_ "GenSigTimeoutTime" BU_SG_REL_ Gateway SG_ 2549088326 NM_Klima_Lokalaktiv 5000;
BA_REL_ "GenSigTimeoutTime" BU_SG_REL_ Gateway SG_ 2549088326 NM_Klima_Subsystemaktiv 5000;
BA_REL_ "GenSigTimeoutTime" BU_SG_REL_ Gateway SG_ 2549088326 KL_KD_Fehler 2500;
BA_REL_ "GenSigTimeoutTime" BU_SG_REL_ Gateway SG_ 2549088345 Lift_Nachlauftyp 5000;
BA_REL_ "GenSigTimeoutTime" BU_SG_REL_ Gateway SG_ 2549088345 Lift_SNI 5000;
BA_REL_ "GenSigTimeoutTime" BU_SG_REL_ Gateway SG_ 2549088345 KN_Lift_ECUKnockOutTimer 5000;
BA_REL_ "GenSigTimeoutTime" BU_SG_REL_ Gateway SG_ 2549088345 KN_Lift_BusKnockOut 5000;
BA_REL_ "GenSigTimeoutTime" BU_SG_REL_ Gateway SG_ 2549088345 KN_Lift_BusKnockOutTimer 5000;
BA_REL_ "GenSigTimeoutTime" BU_SG_REL_ Gateway SG_ 2549088345 KN_Lift_ECUKnockOut 5000;
BA_REL_ "GenSigTimeoutTime" BU_SG_REL_ Gateway SG_ 2549088345 Lift_Lokalaktiv 5000;
BA_REL_ "GenSigTimeoutTime" BU_SG_REL_ Gateway SG_ 2549088345 Lift_Subsystemaktiv 5000;
BA_REL_ "GenSigTimeoutTime" BU_SG_REL_ Gateway SG_ 2549088345 Lift_KD_Fehler 2500;
BA_REL_ "GenSigTimeoutTime" BU_SG_REL_ Gateway SG_ 2549088452 VAS_L_Nachlauftyp 5000;
BA_REL_ "GenSigTimeoutTime" BU_SG_REL_ Gateway SG_ 2549088452 VAS_L_SNI 5000;
BA_REL_ "GenSigTimeoutTime" BU_SG_REL_ Gateway SG_ 2549088452 KN_VAS_L_ECUKnockOutTimer 5000;
BA_REL_ "GenSigTimeoutTime" BU_SG_REL_ Gateway SG_ 2549088452 KN_VAS_L_BusKnockOut 5000;
BA_REL_ "GenSigTimeoutTime" BU_SG_REL_ Gateway SG_ 2549088452 KN_VAS_L_BusKnockOutTimer 5000;
BA_REL_ "GenSigTimeoutTime" BU_SG_REL_ Gateway SG_ 2549088452 KN_VAS_L_ECUKnockOut 5000;
BA_REL_ "GenSigTimeoutTime" BU_SG_REL_ Gateway SG_ 2549088452 NM_VAS_L_Lokalaktiv 5000;
BA_REL_ "GenSigTimeoutTime" BU_SG_REL_ Gateway SG_ 2549088452 VAS_L_KD_Fehler 2500;
BA_REL_ "GenSigTimeoutTime" BU_SG_REL_ Gateway SG_ 2549088453 VAS_R_Nachlauftyp 5000;
BA_REL_ "GenSigTimeoutTime" BU_SG_REL_ Gateway SG_ 2549088453 VAS_R_SNI 5000;
BA_REL_ "GenSigTimeoutTime" BU_SG_REL_ Gateway SG_ 2549088453 KN_VAS_R_ECUKnockOutTimer 5000;
BA_REL_ "GenSigTimeoutTime" BU_SG_REL_ Gateway SG_ 2549088453 KN_VAS_R_BusKnockOut 5000;
BA_REL_ "GenSigTimeoutTime" BU_SG_REL_ Gateway SG_ 2549088453 KN_VAS_R_BusKnockOutTimer 5000;
BA_REL_ "GenSigTimeoutTime" BU_SG_REL_ Gateway SG_ 2549088453 KN_VAS_R_ECUKnockOut 5000;
BA_REL_ "GenSigTimeoutTime" BU_SG_REL_ Gateway SG_ 2549088453 NM_VAS_R_Lokalaktiv 5000;
BA_REL_ "GenSigTimeoutTime" BU_SG_REL_ Gateway SG_ 2549088453 VAS_R_KD_Fehler 2500;
BA_REL_ "GenSigTimeoutTime" BU_SG_REL_ Gateway SG_ 981 BCM1_Standlicht_Anf 1000;
BA_REL_ "GenSigTimeoutTime" BU_SG_REL_ Gateway SG_ 981 BCM1_Abblendlicht_Anf 1000;
BA_REL_ "GenSigTimeoutTime" BU_SG_REL_ Gateway SG_ 981 BCM1_Fernlicht_Anf 1000;
BA_REL_ "GenSigTimeoutTime" BU_SG_REL_ Gateway SG_ 981 BCM1_Nebellicht_Anf 1000;
BA_REL_ "GenSigTimeoutTime" BU_SG_REL_ Gateway SG_ 981 BCM1_Parklicht_li_Anf 1000;
BA_REL_ "GenSigTimeoutTime" BU_SG_REL_ Gateway SG_ 981 BCM1_Parklicht_re_Anf 1000;
BA_REL_ "GenSigTimeoutTime" BU_SG_REL_ Gateway SG_ 981 BCM1_Schlusslicht_Anf 1000;
BA_REL_ "GenSigTimeoutTime" BU_SG_REL_ Gateway SG_ 981 BCM_Rueckfahrlicht_Anf 1000;
BA_REL_ "GenSigTimeoutTime" BU_SG_REL_ Gateway SG_ 981 BCM1_CH_LH_aktiv 1000;
BA_REL_ "GenSigTimeoutTime" BU_SG_REL_ Gateway_PAG SG_ 2589283621 KL_NV_Energie_Anf 5000;
BA_REL_ "GenSigTimeoutTime" BU_SG_REL_ Gateway_PAG SG_ 2589283621 KL_FlHz_Soll_VL 5000;
BA_REL_ "GenSigTimeoutTime" BU_SG_REL_ Gateway_PAG SG_ 2589283621 KL_FlHz_Soll_HL 5000;
BA_REL_ "GenSigTimeoutTime" BU_SG_REL_ Gateway_PAG SG_ 2589283621 KL_FlHz_Soll_VR 5000;
BA_REL_ "GenSigTimeoutTime" BU_SG_REL_ Gateway_PAG SG_ 2589283621 KL_FlHz_Soll_HR 5000;
BA_REL_ "GenSigTimeoutTime" BU_SG_REL_ Gateway_PAG SG_ 2589283621 KL_ECO_PRO_Aktiv 5000;
BA_REL_ "GenSigTimeoutTime" BU_SG_REL_ Gateway_PAG SG_ 2589283621 KL_ACmax_Aktiv 5000;
BA_REL_ "GenSigTimeoutTime" BU_SG_REL_ Gateway_PAG SG_ 2589283621 KL_ECO_Aktiv 5000;
BA_REL_ "GenSigTimeoutTime" BU_SG_REL_ Gateway_PAG SG_ 992 KL_SL_Soll_hl 1000;
BA_REL_ "GenSigTimeoutTime" BU_SG_REL_ Gateway_PAG SG_ 992 KL_SL_Soll_hr 1000;
BA_REL_ "GenSigTimeoutTime" BU_SG_REL_ Gateway_PAG SG_ 992 KL_SH_Soll_hl 1000;
BA_REL_ "GenSigTimeoutTime" BU_SG_REL_ Gateway_PAG SG_ 992 KL_SH_Soll_hr 1000;
BA_REL_ "GenSigTimeoutTime" BU_SG_REL_ Gateway_PAG SG_ 1505 BCM1_Aussen_Temp_ungef 2000;
BA_REL_ "GenSigTimeoutTime" BU_SG_REL_ Gateway_PAG SG_ 1505 BCM1_PTC_stufig_Status 2000;
BA_REL_ "GenSigTimeoutTime" BU_SG_REL_ Gateway_PAG SG_ 1513 DS_Kaeltemittel_P 2000;
BA_REL_ "GenSigTimeoutTime" BU_SG_REL_ Gateway_PAG SG_ 1513 ION_Status 2000;
BA_REL_ "GenSigTimeoutTime" BU_SG_REL_ Gateway_PAG SG_ 1513 ION_Status_LED 2000;
BA_REL_ "GenSigTimeoutTime" BU_SG_REL_ Gateway_PAG SG_ 1513 AAU_Geblaese 2000;
BA_REL_ "GenSigTimeoutTime" BU_SG_REL_ Gateway_PAG SG_ 1513 ION_Status_Taster 2000;
BA_REL_ "GenSigTimeoutTime" BU_SG_REL_ Gateway_PAG SG_ 1295 KL_Kuehlleistg_stat_erw 1000;
BA_REL_ "GenSigTimeoutTime" BU_SG_REL_ Gateway_PAG SG_ 2549088270 BCM1_Nachlauftyp 5000;
BA_REL_ "GenSigTimeoutTime" BU_SG_REL_ Gateway_PAG SG_ 2549088270 BCM1_SNI 5000;
BA_REL_ "GenSigTimeoutTime" BU_SG_REL_ Gateway_PAG SG_ 2549088270 KN_BCM1_BusKnockOutTimer 5000;
BA_REL_ "GenSigTimeoutTime" BU_SG_REL_ Gateway_PAG SG_ 2549088270 NM_BCM1_Lokalaktiv 5000;
BA_REL_ "GenSigTimeoutTime" BU_SG_REL_ Gateway_PAG SG_ 2549088270 NM_BCM1_Subsystemaktiv 5000;
BA_REL_ "GenSigTimeoutTime" BU_SG_REL_ Gateway_PAG SG_ 2549088270 BCM1_KD_Fehler 2500;
BA_REL_ "GenSigTimeoutTime" BU_SG_REL_ Gateway_PAG SG_ 2549088326 Klima_Nachlauftyp 5000;
BA_REL_ "GenSigTimeoutTime" BU_SG_REL_ Gateway_PAG SG_ 2549088326 Klima_SNI 5000;
BA_REL_ "GenSigTimeoutTime" BU_SG_REL_ Gateway_PAG SG_ 2549088326 KN_Klima_ECUKnockOutTimer 5000;
BA_REL_ "GenSigTimeoutTime" BU_SG_REL_ Gateway_PAG SG_ 2549088326 KN_Klima_BusKnockOut 5000;
BA_REL_ "GenSigTimeoutTime" BU_SG_REL_ Gateway_PAG SG_ 2549088326 KN_Klima_BusKnockOutTimer 5000;
BA_REL_ "GenSigTimeoutTime" BU_SG_REL_ Gateway_PAG SG_ 2549088326 KN_Klima_ECUKnockOut 5000;
BA_REL_ "GenSigTimeoutTime" BU_SG_REL_ Gateway_PAG SG_ 2549088326 NM_Klima_Lokalaktiv 5000;
BA_REL_ "GenSigTimeoutTime" BU_SG_REL_ Gateway_PAG SG_ 2549088326 NM_Klima_Subsystemaktiv 5000;
BA_REL_ "GenSigTimeoutTime" BU_SG_REL_ Gateway_PAG SG_ 2549088326 KL_KD_Fehler 2500;
BA_REL_ "GenSigTimeoutTime" BU_SG_REL_ Gateway_PAG SG_ 2549088345 Lift_Nachlauftyp 5000;
BA_REL_ "GenSigTimeoutTime" BU_SG_REL_ Gateway_PAG SG_ 2549088345 Lift_SNI 5000;
BA_REL_ "GenSigTimeoutTime" BU_SG_REL_ Gateway_PAG SG_ 2549088345 Lift_Lokalaktiv 5000;
BA_REL_ "GenSigTimeoutTime" BU_SG_REL_ Gateway_PAG SG_ 2549088345 Lift_KD_Fehler 2500;
BA_REL_ "GenSigTimeoutTime" BU_SG_REL_ Gateway_PAG SG_ 2549088452 VAS_L_Nachlauftyp 5000;
BA_REL_ "GenSigTimeoutTime" BU_SG_REL_ Gateway_PAG SG_ 2549088452 VAS_L_SNI 5000;
BA_REL_ "GenSigTimeoutTime" BU_SG_REL_ Gateway_PAG SG_ 2549088452 KN_VAS_L_ECUKnockOutTimer 5000;
BA_REL_ "GenSigTimeoutTime" BU_SG_REL_ Gateway_PAG SG_ 2549088452 KN_VAS_L_BusKnockOut 5000;
BA_REL_ "GenSigTimeoutTime" BU_SG_REL_ Gateway_PAG SG_ 2549088452 KN_VAS_L_BusKnockOutTimer 5000;
BA_REL_ "GenSigTimeoutTime" BU_SG_REL_ Gateway_PAG SG_ 2549088452 KN_VAS_L_ECUKnockOut 5000;
BA_REL_ "GenSigTimeoutTime" BU_SG_REL_ Gateway_PAG SG_ 2549088452 NM_VAS_L_Lokalaktiv 5000;
BA_REL_ "GenSigTimeoutTime" BU_SG_REL_ Gateway_PAG SG_ 2549088452 VAS_L_KD_Fehler 2500;
BA_REL_ "GenSigTimeoutTime" BU_SG_REL_ Gateway_PAG SG_ 2549088453 VAS_R_Nachlauftyp 5000;
BA_REL_ "GenSigTimeoutTime" BU_SG_REL_ Gateway_PAG SG_ 2549088453 VAS_R_SNI 5000;
BA_REL_ "GenSigTimeoutTime" BU_SG_REL_ Gateway_PAG SG_ 2549088453 KN_VAS_R_ECUKnockOutTimer 5000;
BA_REL_ "GenSigTimeoutTime" BU_SG_REL_ Gateway_PAG SG_ 2549088453 KN_VAS_R_BusKnockOut 5000;
BA_REL_ "GenSigTimeoutTime" BU_SG_REL_ Gateway_PAG SG_ 2549088453 KN_VAS_R_BusKnockOutTimer 5000;
BA_REL_ "GenSigTimeoutTime" BU_SG_REL_ Gateway_PAG SG_ 2549088453 KN_VAS_R_ECUKnockOut 5000;
BA_REL_ "GenSigTimeoutTime" BU_SG_REL_ Gateway_PAG SG_ 2549088453 NM_VAS_R_Lokalaktiv 5000;
BA_REL_ "GenSigTimeoutTime" BU_SG_REL_ Gateway_PAG SG_ 2549088453 VAS_R_KD_Fehler 2500;
BA_REL_ "GenSigTimeoutTime" BU_SG_REL_ Gateway_PAG SG_ 981 BCM1_Standlicht_Anf 1000;
BA_REL_ "GenSigTimeoutTime" BU_SG_REL_ Gateway_PAG SG_ 981 BCM1_Abblendlicht_Anf 1000;
BA_REL_ "GenSigTimeoutTime" BU_SG_REL_ Gateway_PAG SG_ 981 BCM1_Fernlicht_Anf 1000;
BA_REL_ "GenSigTimeoutTime" BU_SG_REL_ Gateway_PAG SG_ 981 BCM1_Nebellicht_Anf 1000;
BA_REL_ "GenSigTimeoutTime" BU_SG_REL_ Gateway_PAG SG_ 981 BCM1_Parklicht_li_Anf 1000;
BA_REL_ "GenSigTimeoutTime" BU_SG_REL_ Gateway_PAG SG_ 981 BCM1_Parklicht_re_Anf 1000;
BA_REL_ "GenSigTimeoutTime" BU_SG_REL_ Gateway_PAG SG_ 981 BCM1_Schlusslicht_Anf 1000;
BA_REL_ "GenSigTimeoutTime" BU_SG_REL_ Gateway_PAG SG_ 981 BCM1_CH_LH_aktiv 1000;
BA_REL_ "GenSigTimeoutTime" BU_SG_REL_ Klima_MSB SG_ 1712 FS_Taupunkt 5000;
BA_REL_ "GenSigTimeoutTime" BU_SG_REL_ Klima_MSB SG_ 1712 FS_ResponseError 5000;
BA_REL_ "GenSigTimeoutTime" BU_SG_REL_ Klima_MSB SG_ 1712 FS_Temp_Scheibe 5000;
BA_REL_ "GenSigTimeoutTime" BU_SG_REL_ Klima_MSB SG_ 1712 FS_Temp_Sensor 5000;
BA_REL_ "GenSigTimeoutTime" BU_SG_REL_ Klima_MSB SG_ 1712 FS_Luftfeuchte_rel 5000;
BA_REL_ "GenSigTimeoutTime" BU_SG_REL_ Klima_MSB SG_ 1505 BCM1_Aussen_Temp_ungef 2000;
BA_REL_ "GenSigTimeoutTime" BU_SG_REL_ Klima_MSB SG_ 1505 BCM_Heizungsabsperrventil_Status 2000;
BA_REL_ "GenSigTimeoutTime" BU_SG_REL_ Klima_MSB SG_ 1505 BCM_Heizungspumpe_Status 2000;
BA_REL_ "GenSigTimeoutTime" BU_SG_REL_ Klima_MSB SG_ 1505 BCM_Kompressorkupplung_Status 2000;
BA_REL_ "GenSigTimeoutTime" BU_SG_REL_ Klima_MSB SG_ 1505 BCM1_PTC_stufig_Status 2000;
BA_REL_ "GenSigTimeoutTime" BU_SG_REL_ Klima_MSB SG_ 1505 BCM1_FStatus_Aussentemp_ungef 2000;
BA_REL_ "GenSigTimeoutTime" BU_SG_REL_ Klima_MSB SG_ 1505 BCM1_Kompressorstrom_ist 2000;
BA_REL_ "GenSigTimeoutTime" BU_SG_REL_ Klima_MSB SG_ 1505 BCM1_OBD_FStatus_ATemp 2000;
BA_REL_ "GenSigTimeoutTime" BU_SG_REL_ Klima_MSB SG_ 779 KBI_Tankwarnung 2000;
BA_REL_ "GenSigTimeoutTime" BU_SG_REL_ Klima_MSB SG_ 1719 KBI_Standzeit_02 5000;
BA_REL_ "GenSigTimeoutTime" BU_SG_REL_ Klima_MSB SG_ 1719 KBI_QBit_Aussen_Temp_gef 5000;
BA_REL_ "GenSigTimeoutTime" BU_SG_REL_ Klima_MSB SG_ 1719 KBI_Aussen_Temp_gef 5000;
BA_REL_ "GenSigTimeoutTime" BU_SG_REL_ Lift_VA SG_ 1719 KBI_Aussen_Temp_gef 5000;
BA_REL_ "GenSigTimeoutTime" BU_SG_REL_ VAS_L SG_ 1505 BCM1_Aussen_Temp_ungef 2000;
BA_REL_ "GenSigTimeoutTime" BU_SG_REL_ VAS_L SG_ 1505 BCM1_FStatus_Aussentemp_ungef 2000;
BA_REL_ "GenSigTimeoutTime" BU_SG_REL_ VAS_L SG_ 1719 KBI_Aussen_Temp_gef 5000;
BA_REL_ "GenSigTimeoutTime" BU_SG_REL_ VAS_L SG_ 982 LH_Aussenlicht_def 1000;
BA_REL_ "GenSigTimeoutTime" BU_SG_REL_ VAS_L SG_ 982 LH_Standlicht_H_aktiv 1000;
BA_REL_ "GenSigTimeoutTime" BU_SG_REL_ VAS_L SG_ 982 LH_Parklicht_HL_aktiv 1000;
BA_REL_ "GenSigTimeoutTime" BU_SG_REL_ VAS_L SG_ 982 LH_Parklicht_HR_aktiv 1000;
BA_REL_ "GenSigTimeoutTime" BU_SG_REL_ VAS_L SG_ 982 LH_Bremslicht_H_aktiv 1000;
BA_REL_ "GenSigTimeoutTime" BU_SG_REL_ VAS_L SG_ 982 LH_Nebelschluss_aktiv 1000;
BA_REL_ "GenSigTimeoutTime" BU_SG_REL_ VAS_L SG_ 982 LH_Rueckfahrlicht_aktiv 1000;
BA_REL_ "GenSigTimeoutTime" BU_SG_REL_ VAS_L SG_ 982 LH_Blinker_HL_akt 1000;
BA_REL_ "GenSigTimeoutTime" BU_SG_REL_ VAS_L SG_ 982 LH_Blinker_HR_akt 1000;
BA_REL_ "GenSigTimeoutTime" BU_SG_REL_ VAS_L SG_ 982 LH_Blinker_li_def 1000;
BA_REL_ "GenSigTimeoutTime" BU_SG_REL_ VAS_L SG_ 982 LH_Bremsl_li_def 1000;
BA_REL_ "GenSigTimeoutTime" BU_SG_REL_ VAS_L SG_ 982 LH_Schlusslicht_li_def 1000;
BA_REL_ "GenSigTimeoutTime" BU_SG_REL_ VAS_L SG_ 982 LH_Rueckf_li_def 1000;
BA_REL_ "GenSigTimeoutTime" BU_SG_REL_ VAS_L SG_ 982 LH_Nebel_li_def 1000;
BA_REL_ "GenSigTimeoutTime" BU_SG_REL_ VAS_L SG_ 982 LH_Schluss_Brems_Nebel_li_def 1000;
BA_REL_ "GenSigTimeoutTime" BU_SG_REL_ VAS_L SG_ 982 LH_Schluss_Brems_Nebel_re_def 1000;
BA_REL_ "GenSigTimeoutTime" BU_SG_REL_ VAS_L SG_ 982 LH_Zusatzschlussl_def 1000;
BA_REL_ "GenSigTimeoutTime" BU_SG_REL_ VAS_L SG_ 982 LH_Schluss_Brems_li_def 1000;
BA_REL_ "GenSigTimeoutTime" BU_SG_REL_ VAS_L SG_ 982 LH_Schluss_Nebel_li_def 1000;
BA_REL_ "GenSigTimeoutTime" BU_SG_REL_ VAS_L SG_ 982 LH_SL_BRL_BLK_li_def 1000;
BA_REL_ "GenSigTimeoutTime" BU_SG_REL_ VAS_L SG_ 982 LH_Brems_Blk_li_def 1000;
BA_REL_ "GenSigTimeoutTime" BU_SG_REL_ VAS_L SG_ 982 LH_Blinker_re_def 1000;
BA_REL_ "GenSigTimeoutTime" BU_SG_REL_ VAS_L SG_ 982 LH_Bremsl_re_def 1000;
BA_REL_ "GenSigTimeoutTime" BU_SG_REL_ VAS_L SG_ 982 LH_Schlusslicht_re_def 1000;
BA_REL_ "GenSigTimeoutTime" BU_SG_REL_ VAS_L SG_ 982 LH_Rueckf_re_def 1000;
BA_REL_ "GenSigTimeoutTime" BU_SG_REL_ VAS_L SG_ 982 LH_Nebel_re_def 1000;
BA_REL_ "GenSigTimeoutTime" BU_SG_REL_ VAS_L SG_ 982 LH_Schluss_Brems_mi_def 1000;
BA_REL_ "GenSigTimeoutTime" BU_SG_REL_ VAS_L SG_ 982 LH_Schluss_Brems_re_def 1000;
BA_REL_ "GenSigTimeoutTime" BU_SG_REL_ VAS_L SG_ 982 LH_Schluss_Nebel_re_def 1000;
BA_REL_ "GenSigTimeoutTime" BU_SG_REL_ VAS_L SG_ 982 LH_SL_BRL_BLK_re_def 1000;
BA_REL_ "GenSigTimeoutTime" BU_SG_REL_ VAS_L SG_ 982 LH_Brems_Blk_re_def 1000;
BA_REL_ "GenSigTimeoutTime" BU_SG_REL_ VAS_L SG_ 982 LH_Kennzl_def 1000;
BA_REL_ "GenSigTimeoutTime" BU_SG_REL_ VAS_L SG_ 982 LH_3_Bremsl_def 1000;
BA_REL_ "GenSigTimeoutTime" BU_SG_REL_ VAS_L SG_ 982 LH_Nebel_mi_def 1000;
BA_REL_ "GenSigTimeoutTime" BU_SG_REL_ VAS_L SG_ 982 LH_Rueckf_mi_def 1000;
BA_REL_ "GenSigTimeoutTime" BU_SG_REL_ VAS_L SG_ 982 LH_Schlusslicht_mi_def 1000;
BA_REL_ "GenSigTimeoutTime" BU_SG_REL_ VAS_L SG_ 982 LH_Bremsl_mi_def 1000;
BA_REL_ "GenSigTimeoutTime" BU_SG_REL_ VAS_L SG_ 982 LH_Bremsl_li_ges_def 1000;
BA_REL_ "GenSigTimeoutTime" BU_SG_REL_ VAS_L SG_ 982 LH_Bremsl_re_ges_def 1000;
BA_REL_ "GenSigTimeoutTime" BU_SG_REL_ VAS_R SG_ 1505 BCM1_Aussen_Temp_ungef 2000;
BA_REL_ "GenSigTimeoutTime" BU_SG_REL_ VAS_R SG_ 1505 BCM1_FStatus_Aussentemp_ungef 2000;
BA_REL_ "GenSigTimeoutTime" BU_SG_REL_ VAS_R SG_ 1719 KBI_Aussen_Temp_gef 5000;
BA_REL_ "GenSigTimeoutTime" BU_SG_REL_ VAS_R SG_ 982 LH_Aussenlicht_def 1000;
BA_REL_ "GenSigTimeoutTime" BU_SG_REL_ VAS_R SG_ 982 LH_Standlicht_H_aktiv 1000;
BA_REL_ "GenSigTimeoutTime" BU_SG_REL_ VAS_R SG_ 982 LH_Parklicht_HL_aktiv 1000;
BA_REL_ "GenSigTimeoutTime" BU_SG_REL_ VAS_R SG_ 982 LH_Parklicht_HR_aktiv 1000;
BA_REL_ "GenSigTimeoutTime" BU_SG_REL_ VAS_R SG_ 982 LH_Bremslicht_H_aktiv 1000;
BA_REL_ "GenSigTimeoutTime" BU_SG_REL_ VAS_R SG_ 982 LH_Nebelschluss_aktiv 1000;
BA_REL_ "GenSigTimeoutTime" BU_SG_REL_ VAS_R SG_ 982 LH_Rueckfahrlicht_aktiv 1000;
BA_REL_ "GenSigTimeoutTime" BU_SG_REL_ VAS_R SG_ 982 LH_Blinker_HL_akt 1000;
BA_REL_ "GenSigTimeoutTime" BU_SG_REL_ VAS_R SG_ 982 LH_Blinker_HR_akt 1000;
BA_REL_ "GenSigTimeoutTime" BU_SG_REL_ VAS_R SG_ 982 LH_Blinker_li_def 1000;
BA_REL_ "GenSigTimeoutTime" BU_SG_REL_ VAS_R SG_ 982 LH_Bremsl_li_def 1000;
BA_REL_ "GenSigTimeoutTime" BU_SG_REL_ VAS_R SG_ 982 LH_Schlusslicht_li_def 1000;
BA_REL_ "GenSigTimeoutTime" BU_SG_REL_ VAS_R SG_ 982 LH_Rueckf_li_def 1000;
BA_REL_ "GenSigTimeoutTime" BU_SG_REL_ VAS_R SG_ 982 LH_Nebel_li_def 1000;
BA_REL_ "GenSigTimeoutTime" BU_SG_REL_ VAS_R SG_ 982 LH_Schluss_Brems_Nebel_li_def 1000;
BA_REL_ "GenSigTimeoutTime" BU_SG_REL_ VAS_R SG_ 982 LH_Schluss_Brems_Nebel_re_def 1000;
BA_REL_ "GenSigTimeoutTime" BU_SG_REL_ VAS_R SG_ 982 LH_Zusatzschlussl_def 1000;
BA_REL_ "GenSigTimeoutTime" BU_SG_REL_ VAS_R SG_ 982 LH_Schluss_Brems_li_def 1000;
BA_REL_ "GenSigTimeoutTime" BU_SG_REL_ VAS_R SG_ 982 LH_Schluss_Nebel_li_def 1000;
BA_REL_ "GenSigTimeoutTime" BU_SG_REL_ VAS_R SG_ 982 LH_SL_BRL_BLK_li_def 1000;
BA_REL_ "GenSigTimeoutTime" BU_SG_REL_ VAS_R SG_ 982 LH_Brems_Blk_li_def 1000;
BA_REL_ "GenSigTimeoutTime" BU_SG_REL_ VAS_R SG_ 982 LH_Blinker_re_def 1000;
BA_REL_ "GenSigTimeoutTime" BU_SG_REL_ VAS_R SG_ 982 LH_Bremsl_re_def 1000;
BA_REL_ "GenSigTimeoutTime" BU_SG_REL_ VAS_R SG_ 982 LH_Schlusslicht_re_def 1000;
BA_REL_ "GenSigTimeoutTime" BU_SG_REL_ VAS_R SG_ 982 LH_Rueckf_re_def 1000;
BA_REL_ "GenSigTimeoutTime" BU_SG_REL_ VAS_R SG_ 982 LH_Nebel_re_def 1000;
BA_REL_ "GenSigTimeoutTime" BU_SG_REL_ VAS_R SG_ 982 LH_Schluss_Brems_mi_def 1000;
BA_REL_ "GenSigTimeoutTime" BU_SG_REL_ VAS_R SG_ 982 LH_Schluss_Brems_re_def 1000;
BA_REL_ "GenSigTimeoutTime" BU_SG_REL_ VAS_R SG_ 982 LH_Schluss_Nebel_re_def 1000;
BA_REL_ "GenSigTimeoutTime" BU_SG_REL_ VAS_R SG_ 982 LH_SL_BRL_BLK_re_def 1000;
BA_REL_ "GenSigTimeoutTime" BU_SG_REL_ VAS_R SG_ 982 LH_Brems_Blk_re_def 1000;
BA_REL_ "GenSigTimeoutTime" BU_SG_REL_ VAS_R SG_ 982 LH_Kennzl_def 1000;
BA_REL_ "GenSigTimeoutTime" BU_SG_REL_ VAS_R SG_ 982 LH_3_Bremsl_def 1000;
BA_REL_ "GenSigTimeoutTime" BU_SG_REL_ VAS_R SG_ 982 LH_Nebel_mi_def 1000;
BA_REL_ "GenSigTimeoutTime" BU_SG_REL_ VAS_R SG_ 982 LH_Rueckf_mi_def 1000;
BA_REL_ "GenSigTimeoutTime" BU_SG_REL_ VAS_R SG_ 982 LH_Schlusslicht_mi_def 1000;
BA_REL_ "GenSigTimeoutTime" BU_SG_REL_ VAS_R SG_ 982 LH_Bremsl_mi_def 1000;
BA_REL_ "GenSigTimeoutTime" BU_SG_REL_ VAS_R SG_ 982 LH_Bremsl_li_ges_def 1000;
BA_REL_ "GenSigTimeoutTime" BU_SG_REL_ VAS_R SG_ 982 LH_Bremsl_re_ges_def 1000;
VAL_ 2589283621 KL_NV_Energie_Anf 254 "Init" 255 "Fehler" ;
VAL_ 2589283621 KL_Umluft_Connect_status 0 "Keine_Umluft" 1 "Umluft_Kundenwunsch" 2 "Umluft_AQS" 3 "Umluft_Backend_Empfehlung" 4 "Umluft_Navi_Daten" ;
VAL_ 2589283621 KL_ECO_PRO_Aktiv 0 "inaktiv" 1 "aktiv" ;
VAL_ 2589283621 KL_QBit_Sonnenintensitaet 0 "gueltiger_Wert" 1 "Ersatz_Init_oder_Fehlerwert" ;
VAL_ 2589283621 KL_ZR_Anforderung 0 "init" 1 "inaktiv" 2 "aktiv" 3 "reserviert" ;
VAL_ 2589283621 KL_ACmax_Aktiv 0 "inaktiv" 1 "aktiv" ;
VAL_ 2589283621 KL_Defrost_Aktiv 0 "inaktiv" 1 "aktiv" ;
VAL_ 2589283621 KL_ECO_Aktiv 0 "inaktiv" 1 "aktiv" ;
VAL_ 2589283621 KL_Status_Klimastil 0 "Modus_1" 1 "Modus_2" 2 "Modus_3" 3 "Modus_4" ;
VAL_ 2589283621 KL_Kundeneingriff_Geblaese 0 "Kein_Kundeneingriff_Geblaese" 1 "Kundeneingriff_Geblaese_aktiv" ;
VAL_ 2589283621 KL_Thermischer_Bedarf 0 "Aus" 1 "Heizen" 2 "Nachlauf_Heizen" 3 "Lueften" 4 "Kuehlen" 6 "Init" 7 "Fehler" ;
VAL_ 2589283621 KL_Eps_Innen 254 "Init" 255 "Fehler" ;
VAL_ 2589283621 KL_Sonnenintensitaet 254 "Init" 255 "Fehler" ;
VAL_ 2463978701 KL_Temp_Soll_vr_Prognose 30 "Klima_OFF" 31 "Init" ;
VAL_ 2463978701 KL_Leistungsreduktions_Hinweis 0 "kein_Hinweis_Anzeigen" 1 "Hinweis_Anzeigen" ;
VAL_ 2463978701 KL_AC_Schalter_Prognose 0 "aus" 1 "ein" 2 "automatisiertes_an_ab_schalten" ;
VAL_ 2463978701 KL_Temp_Soll_vl_Prognose 30 "Klima_Off" 31 "Init" ;
VAL_ 2463978701 KL_Sollklimamodus_FPR_1 0 "Klima_OFF" 1 "Normal" 2 "ECO_aktiv" 3 "ECO_aktiv_AC_toggeln" 4 "FANonly" ;
VAL_ 2463978701 KL_Temp_Soll_hr_Prognose 30 "Klima_OFF" 31 "Init" ;
VAL_ 2463978701 KL_Sollklimamodus_FPR_2 0 "Klima_OFF" 1 "Normal" 2 "ECO_aktiv" 3 "ECO_aktiv_AC_toggeln" 4 "FANonly" ;
VAL_ 2463978701 KL_Temp_Soll_hl_Prognose 30 "Klima_OFF" 31 "Init" ;
VAL_ 2463978701 KL_Sollklimamodus_FPR_3 0 "Klima_OFF" 1 "Normal" 2 "ECO_aktiv" 3 "ECO_aktiv_AC_toggeln" 4 "FANonly" ;
VAL_ 2589283689 KL_FANonly_Aktiv 0 "inaktiv" 1 "aktiv" ;
VAL_ 2589284046 KL_SSC_Status_VL 0 "AUS" 1 "EIN" ;
VAL_ 2589284046 KL_SSC_Status_VR 0 "AUS" 1 "EIN" ;
VAL_ 2589284046 KL_SH_LS1_PWM 101 "100_Prozent_PWM_SpgUnkompensiert" 127 "FnAbbruch_Slave_zuruecksetzen" ;
VAL_ 2589284046 KL_SH_LL1_PWM 101 "100_Prozent_PWM_SpgUnkompensiert" 127 "FnAbbruch_Slave_zuruecksetzen" ;
VAL_ 2589284046 KL_SL_LS1_PWM 101 "100_Prozent_PWM_SpgUnkompensiert" 127 "FnAbbruch_Slave_zuruecksetzen" ;
VAL_ 2589284046 KL_SL_LL1_PWM 101 "100_Prozent_PWM_SpgUnkompensiert" 127 "FnAbbruch_Slave_zuruecksetzen" ;
VAL_ 2589284046 KL_SH_RS1_PWM 101 "100_Prozent_PWM_SpgUnkompensiert" 127 "FnAbbruch_Slave_zuruecksetzen" ;
VAL_ 2589284046 KL_SH_RL1_PWM 101 "100_Prozent_PWM_SpgUnkompensiert" 127 "FnAbbruch_Slave_zuruecksetzen" ;
VAL_ 2589284046 KL_SL_RS1_PWM 101 "100_Prozent_PWM_SpgUnkompensiert" 127 "FnAbbruch_Slave_zuruecksetzen" ;
VAL_ 2589284046 KL_SL_RL1_PWM 101 "100_Prozent_PWM_SpgUnkompensiert" 127 "FnAbbruch_Slave_zuruecksetzen" ;
VAL_ 992 KL_Fond_Fuss_Temp_hl 1022 "Init" 1023 "Fehler" ;
VAL_ 992 KL_Fond_Fuss_Temp_hr 1022 "Init" 1023 "Fehler" ;
VAL_ 992 KL_MA_Temp_hl 1022 "Init" 1023 "Fehler" ;
VAL_ 992 KL_SIH_Takt_hl 0 "Aus" 1 "Ein" ;
VAL_ 992 KL_SIH_Takt_hr 0 "Aus" 1 "Ein" ;
VAL_ 992 KL_Fehler_Umluft 0 "Umluftklappe_iO" 1 "Umluftklappe_niO" ;
VAL_ 992 KL_RAB 0 "keine_Auswirkung_auf_Klimasystem" 1 "Fehler_hat_Auswirkung_auf_die_Klimatisierung" ;
VAL_ 992 KL_Fond_Absperrventil 0 "nicht angesteuert" 1 "wird angesteuert" ;
VAL_ 992 KL_Fond_KD_Fehler 0 "kein_KD_Fehler" 1 "KD_Fehler" ;
VAL_ 992 KL_MA_Temp_hr 1022 "Init" 1023 "Fehler" ;
VAL_ 992 KL_Fehler_Fussraum_Klappen 0 "kein_Fehler" 1 "Fehler_Fuss_li" 2 "Fehler_Fuss_re" 3 "Beide_Klappen_defekt" ;
VAL_ 992 KL_Fehler_Temp_Klappen 0 "kein_Fehler" 1 "Fehler_Temp_li" 2 "Fehler_Temp_re" 3 "Beide_Klappen_defekt" ;
VAL_ 992 KL_Fehler_Temp_MA_Klappen 0 "kein_Fehler" 1 "Fehler_MA_li" 2 "Fehler_MA_re" 3 "Beide_Klappen_defekt" ;
VAL_ 1712 FS_Taupunkt 0 "nicht verfuegbar" 1023 "Fehler" ;
VAL_ 1712 FS_ResponseError 0 "normal" 1 "Fehler" ;
VAL_ 1712 FS_Temp_Scheibe 0 "nicht verfuegbar" 1023 "Fehler" ;
VAL_ 1712 FS_Temp_Sensor 0 "nicht verfuegbar" 255 "Fehler" ;
VAL_ 1712 FS_Luftfeuchte_rel 0 "nicht verfuegbar" 255 "Fehler" ;
VAL_ 1505 BCM1_Aussen_Temp_ungef 253 "nicht_verbaut" 254 "Initwert" 255 "Fehler" ;
VAL_ 1505 BCM_Heizungsabsperrventil_Status 0 "HAV_offen" 1 "HAV_geschlossen" 2 "Init_oder_nicht_verbaut" 3 "Fehler" ;
VAL_ 1505 BCM_Heizungspumpe_Status 0 "Pumpe_aus" 1 "Pumpe_aktiv_und_Stauts_iO" 2 "Init_oder_nicht_verbaut" 3 "Fehler" ;
VAL_ 1505 BCM_Kompressorkupplung_Status 0 "Kupplung_offen" 1 "Kupplung_geschlossen" 2 "Init_oder_nicht_verbaut" 3 "Fehler" ;
VAL_ 1505 BCM1_PTC_stufig_Status 0 "Aus" 1 "Stufe_1_aktiv" 2 "Stufe_2_aktiv" 3 "Stufe_3_aktiv" 6 "Init_oder_nicht_verbaut" 7 "Fehler" ;
VAL_ 1505 BCM1_FStatus_Aussentemp_ungef 0 "iO" 1 "niO" ;
VAL_ 1505 BCM1_Kompressorstrom_ist 254 "Init, bzw. nicht verfuegbar" 255 "Fehler" ;
VAL_ 1505 BCM1_OBD_FStatus_ATemp 0 "kein Fehler / Init / nicht verbaut" 1 "KS- (Kurzschluss nach minus)" 2 "KS+ (Kurzschluss nach plus)" 3 "OC (Leitungsunterbrechung)" 4 "OOR+ (Signal zu gross)" 5 "OOR- (Signal zu klein)" 6 "RC+ (Signal unplausibel zu gross)" 7 "RC- (Signal unplausibel zu klein)" 8 "KS+/OC (Kurzschluss nach plus/Unterbrechung)" 9 "KS-/OC  (Kurzschluss nach minus/Unterbrechung)" 10 "KS-/KS+  (Kurzschluss nach minus/plus)" 11 "KS-/KS+/OC (Kurzschluss nach minus/plus/Unterbrechung)" 12 "frei" 13 "frei" 14 "frei" 15 "frei" ;
VAL_ 1717 FSA_Taupunkt 1021 "nicht_verbaut" 1022 "Init" 1023 "Fehler" ;
VAL_ 1717 FSA_Err_Defekt_Tsens_TF 0 "inaktiv" 1 "aktiv" ;
VAL_ 1717 FSA_Luftfeuchte_TNCTOC 0 "Test_Completed_TOC" 1 "Test_Not_Completed_TOC" ;
VAL_ 1717 FSA_Luftfeuchte_TF 0 "inaktiv" 1 "aktiv" ;
VAL_ 1717 FSA_Err_Unterspannung_TF 0 "inaktiv" 1 "aktiv" ;
VAL_ 1717 FSA_Err_RAMROM_Check_TF 0 "inaktiv" 1 "aktiv" ;
VAL_ 1717 FSA_ResponseError 0 "normal" 1 "Fehler" ;
VAL_ 1717 FSA_Temp_Luft 1021 "nicht_verbaut" 1022 "Init" 1023 "Fehler" ;
VAL_ 1717 FSA_Err_RAMROM_Check_TNCTOC 0 "Test_Completed_TOC" 1 "Test_Not_Completed_TOC" ;
VAL_ 1717 FSA_Lokal_Bus_elektr_Fehler 0 "kein_Fehler" 1 "Fehler" ;
VAL_ 1717 FSA_Timeout 0 "kein_Fehler" 1 "Fehler" ;
VAL_ 1717 FSA_Lokal_Bus_Unterbrechung 0 "kein_Fehler" 1 "Fehler" ;
VAL_ 1717 FSA_Err_Ueberspannung_TF 0 "inaktiv" 1 "aktiv" ;
VAL_ 1717 FSA_Luftfeuchte_rel 253 "nicht_verbaut" 254 "Init" 255 "Fehler" ;
VAL_ 1717 FSA_Temp_Sensor 2045 "nicht_verbaut" 2046 "Init" 2047 "Fehler" ;
VAL_ 1717 FSA_Sensorheizung_Status 0 "inaktiv" 1 "aktiv" ;
VAL_ 1717 FSA_Err_Defekt_HumSense_TF 0 "inaktiv" 1 "aktiv" ;
VAL_ 1717 FSA_Err_Defekt_HumSens_TNCTOC 0 "Test_Completed_TOC" 1 "Test_Not_Completed_TOC" ;
VAL_ 1717 FSA_ErrMemState 0 "Init_Default" 1 "ErrMem_Active_State" 2 "ErrMem_InitProgress" 3 "ErrMem_Init_done" ;
VAL_ 1513 DS_Kaeltemittel_P 2046 "Init" 2047 "Fehler" ;
VAL_ 1513 DS_Status 0 "i.O." 1 "t.b.d." 2 "Init bzw. nicht verfügbar" 3 "Fehler" ;
VAL_ 1513 ION_Status 0 "Hochspannung_ausgeschaltet" 1 "Hochspannung_eingeschaltet" 2 "Init" ;
VAL_ 1513 ION_Status_LED 0 "Aus" 1 "Ein" ;
VAL_ 1513 AAU_Geblaese 126 "Init" 127 "Fehler" ;
VAL_ 1513 ION_Status_Taster 0 "nicht_betaetigt" 1 "betaetigt" ;
VAL_ 1295 KL_Kuehlenergie_instat_pred 254 "Init" 255 "Fehler" ;
VAL_ 1295 KL_Heizenergie_instat_pred 254 "Init" 255 "Fehler" ;
VAL_ 1295 KL_PTC_ein 0 "Aus" 1 "Ein" ;
VAL_ 1295 KL_Leistungspriorisierung 0 "keine_Priorisierung" 1 "PullDown" 2 "Beschlagsgefahr" 3 "Defrost_aktiv" ;
VAL_ 1295 KL_Verdampfertemperatur 1022 "Init" 1023 "Fehler" ;
VAL_ 1295 KL_Heizbedarf 0 "Kein_Heizbedarf" 1022 "Init" 1023 "Fehler" ;
VAL_ 1295 KL_Kuehlbedarf 253 "Kein_Kuehlbedarf" 254 "Init" 255 "Fehler" ;
VAL_ 1295 KL_Kuehlleistg_stat_erw 254 "Init" 255 "Fehler" ;
VAL_ 1295 KL_Heizleistg_stat_erw 254 "Init" 255 "Fehler" ;
VAL_ 2589283474 KL_MMTR_Status 0 "Nicht_verfuegbar" 1 "Inaktiv" 2 "Aktiv_Vorkonditionierung" 3 "Beendet_Vorkonditionierung" 4 "Aktiv_TrackSession" 5 "Aktiv_Endurance" 6 "Aktiv_HotLap" 7 "Beendet_TrackSession" 14 "Init" 15 "Fehler" ;
VAL_ 2589283474 KL_Temp_vor_Verdampfer 126 "Init" 127 "Fehler" ;
VAL_ 2589283474 KL_MMTR 0 "Aus" 1 "Ein" ;
VAL_ 2589283474 KL_Eps_Innen 254 "Init" 255 "Fehler" ;
VAL_ 2589283474 KL_Tempklappe_Fond_li 254 "Init" 255 "Fehler" ;
VAL_ 2589283474 KL_Tempklappe_Fond_re 254 "Init" 255 "Fehler" ;
VAL_ 2549088270 BCM1_KompSchutz 0 "inaktiv" 1 "aktiv" ;
VAL_ 2549088270 BCM1_Abschaltstufe 0 "keine_Einschraenkung" 1 "Funktionseinschraenkung" ;
VAL_ 2549088270 BCM1_Transport_Mode 0 "keine_Einschraenkung" 1 "Funktionseinschraenkung" ;
VAL_ 2549088270 BCM1_Nachlauftyp 0 "Komm_bei_KL15_EIN" 1 "Komm_nach_KL15_AUS" 2 "Komm_bei_KL15_AUS" ;
VAL_ 2549088270 BCM1_SNI 14 "BCM1" ;
VAL_ 2549088270 KN_BCM1_BusKnockOutTimer 255 "BusKnockOut_deaktiviert" ;
VAL_ 2549088270 NM_BCM1_Wakeup 0 "Peripherie_Wakeup__Ursache_nicht_bekannt" 1 "CAN_Wakeup" 2 "KL15_HW" 3 "KL30" 4 "KL58_xs_xt_xd" 5 "Warnblinktaster_EIN" 6 "LDS_Standlicht" 7 "Klemme_S" 8 "Lock_Unlock_Taster" 9 "Heckdeckel_Grifftaster" 10 "Funkbefehl" 11 "Drehfalle_HL" 12 "Drehfalle_HR" 13 "Motorhaubenkontakt" 14 "Heckdeckel_Vorraste" 15 "Heckdeckel_Hauptraste" 16 "LDS_Abblendlicht" 17 "Drehfalle_FT" 18 "Drehfalle_BT" 19 "Kessy_Schluessel_erkannt" 20 "Heckdeckel_Entriegelungstaster" 21 "Schlossrueckmeldung_HL" 22 "Schlossrueckmeldung_HR" 23 "Lichthupe" 25 "DWA_Heckscheibenbruch" 26 "LIN1" 27 "LIN2" 28 "LIN3" 29 "LIN4" 30 "LIN5" 31 "LIN6" 33 "LIN8" 36 "LDS_Nebellicht_Nebelschlusslicht" 37 "Valet_Taster" 38 "Scheinwerferdiebstahlueberwachung" 39 "Versorgung_Innenlicht_KL30g" 40 "Display_Taster" 41 "RearMode_Taster" 42 "SAD_Taster" 43 "Rollo_Taster" 44 "bCall_Taster" 45 "eCall_Taster" 46 "Sitzpneumatikregler" 47 "Signalhorn" 48 "Zustandswechsel_ZV_BEV_PHEV" 49 "Ladesteckerentriegelung_BEV_PHEV" 50 "LIN10_WakeUp" 51 "Taster_Laderaumschliessung" 52 "STH_Taster" 53 "Defrost_Taster_Betaetigt" 54 "Ladesteckerverriegelung_BEV_PHEV" 55 "TuerInnenGriff_HBFS" 56 "TuerInnenGriff_HFS" 57 "TuerAussenGriff_HBFS" 58 "TuerAussenGriff_HFS" 60 "LIN7_WakeUp" 61 "LIN9_WakeUp" 62 "LIN11_WakeUp" 63 "LIN12_WakeUp" 64 "LIN13_WakeUp" 65 "LIN14_WakeUp" 128 "ZV_Wiederverriegelung" 129 "Coming_Home_Ende" 130 "Leaving_Home_Ende" 131 "Softtouch_Freigabe_entziehen" 132 "Fensterheber_Freigabe_entziehen" 133 "Schiebedach_Freigabe_entziehen" 134 "Verdeck_Freigabe_entziehen" 135 "ELV_Freigabe" 136 "KL58xt_Ende" 137 "IRUE_Ausloesung" 138 "NGS_Ausloesung" 139 "Sounder_Alarm" 140 "Regenschliessen" 141 "Remotestart" 142 "Lichtwarnung_Ende" 143 "DWA_Alarm" 144 "Innenlicht" 145 "Tankklappe_wurde_geschlossen" 146 "Parklicht" 147 "Klimafunktion" 148 "Standlicht" 149 "Tankklappe_wurde_geoeffnet" 150 "SAFE_LED" 151 "ZV_TAG_aus_einfahren" 254 "Watchdog_Test" 255 "Entwicklungsursache" ;
VAL_ 2549088270 NM_BCM1_Lokalaktiv 0 "war_nicht_lokal_aktiv" 1 "war_lokal_aktiv" ;
VAL_ 2549088270 NM_BCM1_Subsystemaktiv 0 "war_nicht_lokal_aktiv" 1 "war_lokal_aktiv" ;
VAL_ 2549088270 BCM1_KD_Fehler 0 "Kein_KD_Fehler" 1 "KD_Fehler" ;
VAL_ 2549088272 Gateway_KompSchutz 0 "inaktiv" 1 "aktiv" ;
VAL_ 2549088272 Gateway_Abschaltstufe 0 "keine_Einschraenkung" 1 "Funktionseinschraenkung" ;
VAL_ 2549088272 Gateway_Transport_Mode 0 "keine_Einschraenkung" 1 "Funktionseinschraenkung" ;
VAL_ 2549088272 Gateway_Nachlauftyp 0 "Komm_bei_KL15_EIN" 1 "Komm_nach_KL15_AUS" 2 "Komm_bei_KL15_AUS" ;
VAL_ 2549088272 Gateway_SNI 16 "Gateway" ;
VAL_ 2549088272 NM_Gateway_Wakeup 0 "Peripherie_Wakeup__Ursache_nicht_bekannt" 1 "Bus_Wakeup" 2 "KL15_HW" 3 "ACAN_Wakeup" 4 "FCAN_Wakeup" 5 "KCAN_Wakeup" 6 "ICAN_Wakeup" 7 "DiagCAN_Wakeup" 8 "ECAN_Wakeup" 9 "Energie_LIN_Wakeup" 10 "Bedien_LIN_Wakeup" 11 "HybridCAN_Wakeup" 12 "Flexray_Wakeup" 13 "MFL_WakeUp" 14 "Ethernet" 15 "DCAN_Wakeup" 16 "K2CAN_Wakeup" 17 "CCAN" 18 "AFSCAN_Wakeup" 19 "LIN1" 20 "LIN2" 21 "LIN3" 22 "LIN4" 23 "LIN5" 24 "LIN6" 25 "FASCAN" 26 "FAS2CAN" 27 "MDKCAN" 32 "FlexRay_Branch1_WakeUp" 33 "FlexRay_Branch2_WakeUp" 34 "FlexRay_Branch3_WakeUp" 35 "FlexRay_Branch4_WakeUp" 36 "FlexRay_Branch5_WakeUp" 37 "FlexRay_Branch6_WakeUp" 38 "FlexRay_Branch7_WakeUp" 39 "FlexRay_Branch8_WakeUp" 40 "FlexRay_Branch9_WakeUp" 41 "FlexRay_Branch10_WakeUp" 42 "FlexRay_Branch11_WakeUp" 43 "FlexRay_Branch12_WakeUp" 44 "FlexRay_Branch13_WakeUp" 45 "FlexRay_Branch14_WakeUp" 46 "FlexRay_Branch15_WakeUp" 47 "FlexRay_Branch16_WakeUp" 128 "Energiemanagement" 129 "Funktionswakeup_OBDC" 130 "Hochvoltenergiemanagement" 131 "CWU_empfangen" 132 "Fuer_Bus_relevanten_FC_empfangen" 133 "OnlineDienst_empfangen" 134 "HV_Aktivieren" 135 "HV_Deaktivieren" 136 "VTS_Suche_DriverCard" 137 "VTS_Hupen_Blinken" 138 "Remote_Vehicle_Status" 139 "Plug_and_Charge" 140 "VTS_Wakeup_Infotainment" 141 "EMHLR" 142 "NFcGW_fordert_OTA_FC_an" 143 "Komponentenschutz" 144 "UserStateServer" 145 "Dimmung" 146 "Kessy" 147 "StandardAussenlicht" 148 "ParkKoordinator" 149 "HVLMDynamicChargingPOI" 150 "HVLMChargingManagementServer" 151 "HVLMExtendedChargingMonitoring" 152 "Zentralverriegelung" 153 "FunctionOnDemand" 154 "IAA" 155 "StandKlimatisierung" 156 "RealTimeMonitor" 157 "Klemmensteuerung" 158 "Fremdladung_erkannt" ;
VAL_ 2549088272 NM_Gateway_Lokalaktiv 0 "war_nicht_lokal_aktiv" 1 "war_lokal_aktiv" ;
VAL_ 2549088272 NM_Gateway_Subsystemaktiv 0 "Subsystem_war_nicht_lokalaktiv" 1 "war_lokalaktiv" ;
VAL_ 2549088272 GW_KD_Fehler 0 "kein_KD_Fehler" 1 "KD_Fehler" ;
VAL_ 2549088326 Klima_KompSchutz 0 "inaktiv" 1 "aktiv" ;
VAL_ 2549088326 Klima_Abschaltstufe 0 "keine_Einschraenkung" 1 "Funktionseinschraenkung" ;
VAL_ 2549088326 Klima_Transport_Mode 0 "keine_Einschraenkung" 1 "Funktionseinschraenkung" ;
VAL_ 2549088326 Klima_Nachlauftyp 0 "Komm_bei_KL15_EIN" 1 "Komm_nach_KL15_AUS" 2 "Komm_bei_KL15_AUS" ;
VAL_ 2549088326 Klima_SNI 70 "Klima" ;
VAL_ 2549088326 KN_Klima_ECUKnockOutTimer 63 "ECUKnockOut_deaktiviert" ;
VAL_ 2549088326 KN_Klima_BusKnockOut 0 "Funktion_nicht_ausgeloest" 1 "Veto_aktiv" 2 "Funktion_ausgeloest" 3 "Funktion_deaktiviert" ;
VAL_ 2549088326 KN_Klima_BusKnockOutTimer 255 "BusKnockOut_deaktiviert" ;
VAL_ 2549088326 NM_Klima_Wakeup 0 "Peripherie_Wakeup__Ursache_nicht_bekannt" 1 "Bus_Wakeup" 2 "KL15_HW" 3 "KL30_Reset" 4 "STH_Taste" 5 "Restwaerme_Menuauswahl" 128 "STH_Ein__Zielzeitlogik" 129 "Standfunktion_Funk_EIN" 130 "Umentscheidung_STL_nach_STH" 131 "Ablauf_der_max_Betriebsdauer" 132 "Geblaese_aus_ein" ;
VAL_ 2549088326 KN_Klima_ECUKnockOut 0 "Funktion_nicht_ausgeloest" 1 "Veto_war_aktiv" 2 "Funktion_ausgeloest" 3 "Funktion_deaktiviert" ;
VAL_ 2549088326 NM_Klima_Lokalaktiv 0 "war_nicht_lokal_aktiv" 1 "war_lokal_aktiv" ;
VAL_ 2549088326 NM_Klima_Subsystemaktiv 0 "Subsystem_war_nicht_lokalaktiv" 1 "war_lokalaktiv" ;
VAL_ 2549088326 KL_KD_Fehler 0 "kein_KD_Fehler" 1 "KD_Fehler" ;
VAL_ 2549088345 Lift_KompSchutz 0 "inaktiv" 1 "aktiv" ;
VAL_ 2549088345 Lift_Abschaltstufe 0 "keine_Einschraenkung" 1 "Funktionseinschraenkung" ;
VAL_ 2549088345 Lift_Transport_Mode 0 "keine_Einschraenkung" 1 "Funktionseinschraenkung" ;
VAL_ 2549088345 Lift_Nachlauftyp 0 "Komm_bei_KL15_EIN" 1 "Komm_nach_KL15_AUS" 2 "Komm_bei_KL15_AUS" ;
VAL_ 2549088345 Lift_SNI 89 "Lift" ;
VAL_ 2549088345 KN_Lift_ECUKnockOutTimer 63 "ECUKnockOut_deaktiviert" ;
VAL_ 2549088345 KN_Lift_BusKnockOut 0 "Funktion_nicht_ausgeloest" 1 "Veto_aktiv" 2 "Funktion_ausgeloest" 3 "Funktion_deaktiviert" ;
VAL_ 2549088345 KN_Lift_BusKnockOutTimer 255 "BusKnockOut_deaktiviert" ;
VAL_ 2549088345 NM_Lift_Wakeup 0 "Peripherie_Wakeup__Ursache_nicht_bekannt" 1 "Bus_Wakeup" 2 "KL15_HW" ;
VAL_ 2549088345 KN_Lift_ECUKnockOut 0 "Funktion_nicht_ausgeloest" 1 "Veto_war_aktiv" 2 "Funktion_ausgeloest" 3 "Funktion_deaktiviert" ;
VAL_ 2549088345 Lift_Lokalaktiv 0 "war_nicht_lokal_aktiv" 1 "war_lokal_aktiv" ;
VAL_ 2549088345 Lift_Subsystemaktiv 0 "Subsystem_war_nicht_lokalaktiv" 1 "war_lokalaktiv" ;
VAL_ 2549088345 Lift_KD_Fehler 0 "kein_KD_Fehler" 1 "KD_Fehler" ;
VAL_ 2549088452 VAS_L_KompSchutz 0 "KS_nicht_aktiv" 1 "KS_aktiv" ;
VAL_ 2549088452 VAS_L_Abschaltstufe 0 "keine_Einschraenkung" 1 "Funktionseinschraenkung" ;
VAL_ 2549088452 VAS_L_Transport_Mode 0 "keine_Einschraenkung" 1 "Funktionseinschraenkung" ;
VAL_ 2549088452 VAS_L_Nachlauftyp 0 "Komm_bei_KL15_EIN" 1 "Komm_nach_KL15_AUS" 2 "Komm_bei_KL15_AUS" ;
VAL_ 2549088452 VAS_L_SNI 196 "VAS_L" ;
VAL_ 2549088452 KN_VAS_L_ECUKnockOutTimer 63 "ECUKnockOut_deaktiviert" ;
VAL_ 2549088452 KN_VAS_L_BusKnockOut 0 "Funktion_nicht_ausgeloest" 1 "Veto_aktiv" 2 "Funktion_ausgeloest" 3 "Funktion_deaktiviert" ;
VAL_ 2549088452 KN_VAS_L_BusKnockOutTimer 255 "BusKnockOut_deaktiviert" ;
VAL_ 2549088452 NM_VAS_L_Wakeup 0 "Peripherie_Wakeup_Ursache_nicht_bekannt" 1 "Bus_Wakeup" 2 "KL15_HW" ;
VAL_ 2549088452 KN_VAS_L_ECUKnockOut 0 "Funktion_nicht_ausgeloest" 1 "Veto_war_aktiv" 2 "Funktion_ausgeloest" 3 "Funktion_deaktiviert" ;
VAL_ 2549088452 NM_VAS_L_Lokalaktiv 0 "war_nicht_lokal_aktiv" 1 "war_lokal_aktiv" ;
VAL_ 2549088452 VAS_L_Subsystemaktiv 0 "Subsystem_war_nicht_lokalaktiv" 1 "war_lokalaktiv" ;
VAL_ 2549088452 VAS_L_KD_Fehler 0 "Kein KD_Fehler" 1 "KD_Fehler" ;
VAL_ 2549088453 VAS_R_KompSchutz 0 "KS_nicht_aktiv" 1 "KS_aktiv" ;
VAL_ 2549088453 VAS_R_Abschaltstufe 0 "keine_Einschraenkung" 1 "Funktionseinschraenkung" ;
VAL_ 2549088453 VAS_R_Transport_Mode 0 "keine_Einschraenkung" 1 "Funktionseinschraenkung" ;
VAL_ 2549088453 VAS_R_Nachlauftyp 0 "Komm_bei_KL15_EIN" 1 "Komm_nach_KL15_AUS" 2 "Komm_bei_KL15_AUS" ;
VAL_ 2549088453 VAS_R_SNI 197 "VAS_R" ;
VAL_ 2549088453 KN_VAS_R_ECUKnockOutTimer 63 "ECUKnockOut_deaktiviert" ;
VAL_ 2549088453 KN_VAS_R_BusKnockOut 0 "Funktion_nicht_ausgeloest" 1 "Veto_aktiv" 2 "Funktion_ausgeloest" 3 "Funktion_deaktiviert" ;
VAL_ 2549088453 KN_VAS_R_BusKnockOutTimer 255 "BusKnockOut_deaktiviert" ;
VAL_ 2549088453 NM_VAS_R_Wakeup 0 "Peripherie_Wakeup_Ursache_nicht_bekannt" 1 "Bus_Wakeup" 2 "KL15_HW" ;
VAL_ 2549088453 KN_VAS_R_ECUKnockOut 0 "Funktion_nicht_ausgeloest" 1 "Veto_war_aktiv" 2 "Funktion_ausgeloest" 3 "Funktion_deaktiviert" ;
VAL_ 2549088453 NM_VAS_R_Lokalaktiv 0 "war_nicht_lokal_aktiv" 1 "war_lokal_aktiv" ;
VAL_ 2549088453 VAS_R_Subsystemaktiv 0 "Subsystem_war_nicht_lokalaktiv" 1 "war_lokalaktiv" ;
VAL_ 2549088453 VAS_R_KD_Fehler 0 "Kein KD_Fehler" 1 "KD_Fehler" ;
VAL_ 779 KBI_ABS_Lampe 0 "ABS Lampe aus" 1 "ABS Lampe ein" ;
VAL_ 779 KBI_ESP_Lampe 0 "ESP Lampe aus" 1 "ESP Lampe ein" ;
VAL_ 779 KBI_BKL_Lampe 0 "BKL aus" 1 "BKL ein" ;
VAL_ 779 KBI_Airbag_Lampe 0 "Airbag Lampe aus" 1 "Airbag Lampe ein" ;
VAL_ 779 KBI_SILA_gueltig 0 "ungueltig" 1 "gueltig" ;
VAL_ 779 KBI_Vorglueh_System_Lampe 0 "Lampe aus" 1 "Lampe ein" ;
VAL_ 779 KBI_NV_in_Anzeige 0 "NV_nicht_in_Anzeige" 1 "NV_in_Anzeige" ;
VAL_ 779 KBI_Anzeigestatus_ACC 0 "keine_ACC_Anzeige" 1 "ACC_Anzeige_aktiv" ;
VAL_ 779 KBI_Anzeigestatus_GRA 0 "nicht_vorhanden" 1 "Anzeigemoeglichkeit_vorhanden" 2 "reserviert" 3 "Fehler" ;
VAL_ 779 KBI_Tankwarnung 0 "Lampe aus" 1 "Lampe ein" ;
VAL_ 779 KBI_MFA_v_Einheit_01 0 "kmh" 1 "mph" ;
VAL_ 779 KBI_im_Stellgliedtest 0 "kein Stellgliedtest" 1 "Kombi im Stellgliedtest" ;
VAL_ 779 KBI_Anzeigefehler_LDW 0 "nicht vorhanden bzw. unterstützt" 1 "Anzeige iO" 2 "Anzeigefehler" 3 "nicht definiert" ;
VAL_ 779 KBI_Tankwarnung_ungueltig 0 "KBI_Tankwarnung_gueltig" 1 "KBI_Tankwarnung_ungueltig" ;
VAL_ 779 KBI_Handbremse 0 "nicht_angezogen" 1 "angezogen" ;
VAL_ 779 KBI_PLA_in_Anzeige 0 "PLA_nicht_in_Anzeige" 1 "PLA_in_Anzeige" ;
VAL_ 779 KBI_Anzeigefehler_NV 0 "kein_Anzeigefehler" 1 "Anzeigefehler" ;
VAL_ 779 KBI_Anzeigestatus_LIM 0 "nicht_vorhanden" 1 "Anzeigemoeglichkeit_vorhanden" 2 "reserviert" 3 "Fehler" ;
VAL_ 779 KBI_ARA_in_Anzeige 0 "ARA nicht in Anzeige" 1 "ARA in Anzeige" ;
VAL_ 779 KBI_Taster_Lift 0 "nicht_betaetigt" 1 "betaetigt" ;
VAL_ 779 KBI_Taster_Fahrwerk 0 "nicht_betaetigt" 1 "betaetigt" ;
VAL_ 779 KBI_GRA_Hauptschalter 0 "Init" 1 "Hauptschalter_aus" 2 "Hauptschalter_ein" 3 "Fehler" ;
VAL_ 779 KBI_Bestaetigung_ESP_Off 0 "ESP_off_nicht_quittiert" 1 "ESP_off_quittiert" 2 "Abbruch" ;
VAL_ 779 KBI_Einheit_Tacho 0 "km/h" 1 "mph" ;
VAL_ 779 KBI_Konsistenz_ACC 0 "ACC Botschaft konsistent" 1 "ACC Botschaft inkonsistent" ;
VAL_ 779 KBI_Fehler_Anzeige_ACC 0 " iO" 1 "Anzeigefehler ACC" ;
VAL_ 779 KBI_Anzeigefehler_SWA 0 "nicht vorhanden bzw. unterstützt" 1 "Anzeige iO" 2 "Anzeigefehler" 3 "nicht definiert" ;
VAL_ 779 KBI_Systemstatus 0 "KBI_IO" 1 "KBI_System_Failure" ;
VAL_ 1719 KBI_Kilometerstand 1048574 "Init" 1048575 "Fehler" ;
VAL_ 1719 KBI_Standzeit_02 131069 "nicht_verfuegbar" 131070 "Init" 131071 "Fehler" ;
VAL_ 1719 KBI_LVDS_Lock 0 "Init_LVDS_nicht_gelockt" 1 "LVDS_gelockt" ;
VAL_ 1719 KBI_Reserve_Warnung_Sek 0 "Keine_Warnung" 1 "Sekundaere_Reservewarnung" ;
VAL_ 1719 KBI_RDK_Kalibrier_Anf 0 "keine_Kalibrieranforderung" 1 "Kalibrieranforderung" ;
VAL_ 1719 KBI_Inhalt_Tank 126 "Init" 127 "Fehler" ;
VAL_ 1719 KBI_FStatus_Tank 0 "Tankfüllstand i.O." 1 "Tankfüllstand n.i.O" ;
VAL_ 1719 KBI_aktive_Laengsfunktion 0 "Init" 1 "Speedlimiter" 2 "GRA_oder_ACC" 3 "PACCh" 4 "HDC" 5 "p_GRA" 6 "p_Lim" 7 "Umschaltung_GRA_Limiter" ;
VAL_ 1719 KBI_TA_gewaehlt_Fahrer 0 "TA_nicht_gewaehlt_Kombi" 1 "TA_gewaehlt_Kombi" ;
VAL_ 1719 KBI_FoD_PopUP_Quittiert 0 "nicht_quittiert" 1 "Meldung_quittiert" ;
VAL_ 1719 KBI_GRA_im_ACC 0 "GRA_im_ACC_nicht_ausgewaehlt" 1 "GRA_im_ACC_ausgewaehlt" ;
VAL_ 1719 KBI_Oelwechsel_durchgefuehrt 0 "Oelwechsel_nicht_durchgefuehrt" 1 "Oelwechsel_durchgefuehrt" ;
VAL_ 1719 KBI_QBit_Aussen_Temp_gef 0 "gueltiger_Wert" 1 "Ersatz_Init_oder_Fehlerwert" ;
VAL_ 1719 KBI_Aussen_Temp_gef 253 "nicht verbaut" 254 "Init" 255 "Fehler" ;
VAL_ 919 LDW_Gong 0 "kein akustisches Signal" 1 "Gong_1" 2 "Gong_2" 3 "Gong_3" ;
VAL_ 919 LDW_Frueh_Spaet 0 "frueh_frueh_aktiv" 1 "frueh_spaet_aktiv" 2 "spaet_spaet_aktiv" 3 "Fehler" ;
VAL_ 919 LDW_Texte 0 "keine_Anzeige" 1 "Laneassist_zur_Zeit_n_verfuegbar" 2 "Laneassist_Systemfehler" 3 "Laneassist_zur_Zeit_keine_SSicht" 4 "Laneassist_Fahreruebernahme" 5 "Laneassist_n_verfuegbar_FoD" 6 "Emergency_Alert_Fahreruebernahme" 7 "Laneassist_FahreruebernahmeLeise" 8 "Laneassist_FahreruebernahmeStumm" 9 "EA_Fahrstreifenwechsel" 10 "Laneassist_Deaktiviert" 11 "Laneassist_Fahreruebernahme_hoch" 12 "Laneassist_mittig_fahren" 13 "Laneassist_adaptiv_aktiv" 14 "Laneassist_adaptiv_deaktiv" 15 "Systgr_Fzgfueh_sofort_uebernehm" ;
VAL_ 919 LDW_Seite_DLCTLC 0 "links" 1 "rechts" ;
VAL_ 919 LDW_Lernmodus 0 "Init_keine_Anzeige" 1 "Lenkeingriff" 2 "Deaktiviert" 3 "Passiv" 4 "Aktiv" 5 "Fehler" 6 "nicht definiert" 7 "nicht definiert" ;
VAL_ 919 LDW_Lernmodus_seitenabhaengig 0 "links_aus__rechts_aus" 1 "HCCA_links_an__rechts_an" 2 "HCCA_links_an__rechts_Warnung" 3 "HCCA_links_Warnung__rechts_an" 4 "links_gestrichelt_rechts_Warnung" 5 "links_outlined__rechts_outlined" 6 "links_outlined__rechts_an" 7 "links_outlined__rechts_Warnung" 8 "links_Warnung_rechts_gestrichel" 9 "links_an__rechts_outlined" 10 "links_an__rechts_an" 11 "links_an__rechts_Warnung" 12 "links_und_rechts_gestrichelt" 13 "links_Warnung__rechts_outlined" 14 "links_Warnung__rechts_an" 15 "links_Warnung__rechts_Warnung" ;
VAL_ 919 LDW_TLC 31 "Init" ;
VAL_ 919 HC_Uss_Anforderung 0 "Ultraschallsensoren Aus" 1 "Ultraschallsensoren An" ;
VAL_ 919 EA_Warnblinken 0 "aus" 1 "Statisch" 2 "Taster" 3 "Statisch_ohne_WBT" ;
VAL_ 919 aLDW_FoD_Status 0 "Init" 1 "Funktion_inaktiv" 2 "Funktion_aktiv" ;
VAL_ 919 LDW_Codierinfo_fuer_VLR 0 "ohne VLR, ohne Akustik" 1 "HMI-Variante VLR" 2 "HMI-Variante VLR + Akustik" 3 "HMI-Variante Akustik" ;
VAL_ 919 LDW_Status_LED_gelb 0 "LDW-Status gelb aus" 1 "LDW-Status gelb aktiv" ;
VAL_ 919 LDW_Status_LED_gruen 0 "LDW-Status gruen aus" 1 "LDW-Status gruen aktiv" ;
VAL_ 919 LKS_LED_an 0 "LED_aus" 1 "LED_ein" ;
VAL_ 810 EPS_SpannungsAnf 0 "keine_Anforderung" 1 "Anforderung_Stufe1" 2 "Anforderung_Stufe2" 3 "Anforderung_Stufe3" ;
VAL_ 810 EPS_Endanschlag 0 "Init_bzw_Defaultlenkhub" 1 "Lenkhubaufweitung_1" 2 "EA_nicht_angelernt_bzw_Initialisierung_nicht_abgeschlossen" 3 "Fehler" ;
VAL_ 810 EPS_Fehlerlampe 0 "Lampe_aus" 1 "Lampe_ein" ;
VAL_ 810 EPS_Warnungen 0 "kein_Text" 1 "Text_1" 2 "Text_2" 3 "Text_3" 4 "Text_4" 5 "Text_5" ;
VAL_ 810 EPS_PWR_Abbruch 0 "Init/Invalid" 1 "PWR beendet durch EPS-SG wegen vFzg" 2 "PWR beendet durch EPS-SG wegen HM" 3 "Lenkwinkeldifferenz zu groß" 4 "Gradient der Zielanforderung zu groß" 5 "reserviert" 6 "reserviert" 7 "reserviert" 8 "Falscher PLA-Status" 9 "Falscher ARA-Status" 10 "reserviert" 11 "reserviert" 12 "reserviert" 13 "reserviert" 14 "reserviert" 15 "reserviert" ;
VAL_ 810 EPS_PWR_Fehler 0 "Init/Invalid" 1 "Unterstützungsleistung zu gering" 2 "reserviert" 3 "Rotorwinkel nicht initialisiert" 4 "BCM1/Rückfahrlicht veraltet" 5 "reserviert" 6 "reserviert" 7 "Fehler ESP(vFzg)" 8 "Fehler ESP(Raddrehzahlen)" 9 "reserviert" 10 "reserviert" 11 "reserviert" 12 "reserviert" 13 "reserviert" 14 "EPS_ARA_Satus == 6" 15 "EPS_PLA_Satus == 6" ;
VAL_ 810 EPS_PLA_Status 0 "EPS_PLA_Deaktiv" 1 "EPS_PLA_Init" 2 "EPS_PLA_Fehler_mit_Eintrag" 3 "reserviert" 4 "reserviert" 5 "reserviert" 6 "EPS_PLA_Lenkwinkel_aktiv" 7 "EPS_PLA_Abgewiesen" 8 "EPS_PLA_Funktionsbereit" 9 "reserviert" 10 "EPS_PLA_Abbruch" 11 "reserviert" 12 "reserviert" 13 "reserviert" 14 "reserviert" 15 "reserviert" ;
VAL_ 810 EPS_Charisma_FahrPr 0 "keine_Funktion" 1 "Programm_1" 2 "Programm_2" 3 "Programm_3" 4 "Programm_4" 5 "Programm_5" 6 "Programm_6" 7 "Programm_7" 8 "Programm_8" 9 "Programm_9" 10 "Programm_10" 11 "Programm_11" 12 "Programm_12" 13 "Programm_13" 14 "Programm_14" 15 "Programm_15" ;
VAL_ 810 EPS_Charisma_Status 0 "Init" 1 "verfuegbar" 2 "nicht_verfuegbar" 3 "asynchron_durch_Fahrerwunsch" ;
VAL_ 810 EPS_Lenkerposition 0 "unbekannt" 1 "Linkslenker" 2 "Rechtslenker" ;
VAL_ 810 EPS_Anf_KL 0 "keine_Anforderung" 1 "Anforderung_Kuehlung" ;
VAL_ 810 EPS_ARA_Status 0 "EPS_ARA_Deaktiv" 1 "EPS_ARA_Init" 2 "EPS_ARA_Fehler_mit_Eintrag" 3 "reserviert" 4 "reserviert" 5 "reserviert" 6 "EPS_ARA_Lenkwinkel_aktiv" 7 "EPS_ARA_Abgewiesen" 8 "EPS_ARA_Funktionsbereit" 9 "reserviert" 10 "EPS_ARA_Abbruch" 11 "reserviert" 12 "reserviert" 13 "reserviert" 14 "reserviert" 15 "reserviert" ;
VAL_ 160 EPS_Lenkmoment_AbsReduz 13 "MAX" 14 "Init" 15 "Fehler" ;
VAL_ 160 EPS_FAS_Regelgroesse 62 "Init" 63 "Fehler" ;
VAL_ 160 EPS_FAS_VZ_Regelgroesse 0 "positiv" 1 "negativ" ;
VAL_ 160 EPS_Motormoment 0 "Not_in_use" 254 "Init" 255 "Fehler" ;
VAL_ 160 EPS_Zahnstangen_Pos 4094 "Init" 4095 "Fehler" ;
VAL_ 160 EPS_VZ_Zahnstangenposition 0 "pos_VZ" 1 "neg_VZ" ;
VAL_ 160 EPS_QBit_Zahnstangen_Pos 0 "gueltiger_Wert" 1 "Ersatz_Init_oder_Fehlerwert" ;
VAL_ 160 EPS_Versorgungsstatus 0 "kein_Fehler" 1 "Unterspannung" 2 "Ueberspannung" 3 "Stoerung" ;
VAL_ 160 EPS_Versorgungsspannung 254 "Init" 255 "Fehler" ;
VAL_ 160 EPS_AWA_Status 0 "AWA_deaktiviert" 1 "AWA_Anf_nicht_ausfuehrbar" 2 "Kom_AWA_gestoert" 3 "EPS_bzgl_AWA_funktionsbereit" 4 "AWA_Anf_abgew" 5 "AWA_Momeingriff_1_aktiv" 6 "reserviert" 7 "AWA_Momeingriff_2_aktiv" 8 "AWA_abgewiesen_aufgrund_Momentenpriorisierung" 9 "Anf_abgewiesen_Bedienueblich" 14 "Init" ;
VAL_ 160 EPS_STA_Status 0 "STA_bzw_STP_deaktiviert" 1 "Anf_nicht_ausfuehrbar" 2 "Kommunikationsfehler" 3 "EPS_bzgl_STA_bzw_STP_funktionsbereit" 4 "Anf_abgewiesen_Fehler" 5 "gesperrt" 6 "STA_bzw_STP_Winkeleingriff_aktiv" 7 "gesperrt" 8 "Anf_abgewiesen_Prio" 9 "Anf_abgewiesen_Bedienueblich" 10 "Winkeleingriff_abgebrochen" 11 "Rueckfallmodus_Winkeleingriff" 12 "Notlauf_Winkelregelung_aktiv" 13 "STA_STP_Winkeleingriff_aktiv_2" 14 "Init" 15 "Schnittstellendeaktiverung_UEF" ;
VAL_ 981 BCM1_Kurvenlicht_links_Anf 0 "linkes_Kurvenlicht/Abbiegelicht_durch_BCM1_nicht_angesteuert" 1 "linkes_Kurven/Abbiegelicht_durch_BCM1_angesteuert" ;
VAL_ 981 BCM1_Kurvenlicht_rechts_Anf 0 "rechtes_Kurvenlicht/Abbiegelicht_durch_BCM1_nicht_angesteuert" 1 "rechtes_Kurvenlicht/Abbiegelicht_durch_BCM1_angesteuert" ;
VAL_ 981 BCM1_Standlicht_Anf 0 "Licht_nicht_angefordert" 1 "Licht ist einzuschalten" ;
VAL_ 981 BCM1_Abblendlicht_Anf 0 "Licht_nicht_angefordert" 1 "Licht ist einzuschalten" ;
VAL_ 981 BCM1_Fernlicht_Anf 0 "Licht_nicht_angefordert" 1 "Licht ist einzuschalten" ;
VAL_ 981 BCM1_Nebellicht_Anf 0 "Licht_nicht_angefordert" 1 "Licht ist einzuschalten" ;
VAL_ 981 BCM1_Parklicht_li_Anf 0 "Licht_nicht_angefordert" 1 "Licht ist einzuschalten" ;
VAL_ 981 BCM1_Parklicht_re_Anf 0 "Licht_nicht_angefordert" 1 "Licht ist einzuschalten" ;
VAL_ 981 BCM1_Nebelschluss_Ahg_Anf 0 "Licht_nicht_angefordert" 1 "Licht ist einzuschalten" ;
VAL_ 981 BCM1_Nebelschluss_Fzg_Anf 0 "Licht_nicht_angefordert" 1 "Licht_ist_einzuschalten" ;
VAL_ 981 BCM1_Schlusslicht_Anf 0 "Licht_nicht_angefordert" 1 "Licht ist einzuschalten" ;
VAL_ 981 BCM_Rueckfahrlicht_Anf 0 "Licht_nicht_angefordert" 1 "Licht_angefordert" ;
VAL_ 981 BCM1_Signaturlicht_Anf 0 "Licht_nicht_angefordert" 1 "Licht_ist_einzuschalten" ;
VAL_ 981 BCM1_Umfeldleuchten_Anf 0 "Licht_nicht_angefordert" 1 "Licht_ist_einzuschalten" ;
VAL_ 981 BCM1_Tagfahrlicht_Anf 0 "Licht_nicht_angefordert" 1 "Licht ist einzuschalten" ;
VAL_ 981 BCM1_Regenlicht_Anf 0 "Licht_nicht_angefordert" 1 "Licht ist einzuschalten" ;
VAL_ 981 BCM1_Autobahnlicht_Anf 0 "Licht_nicht_angefordert" 1 "Licht ist einzuschalten" ;
VAL_ 981 BCM1_Touristen_Licht_Anf 0 "Licht_nicht_angefordert" 1 "Anforderung von Touristenlicht" ;
VAL_ 981 BCM1_CH_aktiv 0 "Inaktiv" 1 "Aktiv" ;
VAL_ 981 BCM1_LH_aktiv 0 "Inaktiv" 1 "Aktiv" ;
VAL_ 981 BCM1_Gleitende_Leuchtw_Anf 0 "Aus" 1 "Ein" ;
VAL_ 981 BCM1_GLW_Fernlicht_Anf 0 "Aus" 1 "Ein" ;
VAL_ 981 BCM1_Adaptive_Lichtvert_Anf 0 "Aus" 1 "Ein" ;
VAL_ 981 BCM1_FoD_Sperrung_WiBli 0 "Freigabe_WiBli" 1 "Sperrung_WiBli" 2 "Init" ;
VAL_ 981 BCM1_FOD_Sperrung_Animationen_HL 0 "Freigabe_Animationen" 1 "Sperrung_Animationen" 2 "Init" ;
VAL_ 981 BCM1_Animationssperrung 0 "keine_Sperrung" 1 "Sperrung" ;
VAL_ 981 BCM1_CH_LH_aktiv 0 "Comming_Home_Bzw._Leaving_Home_nicht_aktiv" 1 "Comming Home bzw. Leaving Home aktiv" ;
VAL_ 981 BCM1_Allwetterlicht_Anf 0 "Licht_nicht_angefordert" 1 "Licht_ist_einzuschalten" ;
VAL_ 981 BCM1_Schlusslicht_Signatur 0 "keine_Signatur" 1 "Signatur_1" 2 "Signatur_2" 3 "Signatur_3" 4 "Signatur_4" 5 "Signatur_5" 6 "Signatur_6" 7 "Signatur_7" 8 "Signatur_8" 9 "Signatur_9" 10 "Signatur_10" 11 "Signatur_11" 12 "Signatur_12" 13 "Signatur_13" 14 "Signatur_14" 15 "Signatur_15" ;
VAL_ 982 BCM2_Bremsl_durch_ECD 0 "Bremslicht_ist_aus" 1 "Bremslicht_durch_ECD_aktiv" ;
VAL_ 982 LH_Aussenlicht_def 0 "OK" 1 "defekt" ;
VAL_ 982 LH_Standlicht_H_aktiv 1 "Standlicht hinten aktiv" ;
VAL_ 982 LH_Parklicht_HL_aktiv 0 "nicht aktiv" 1 "Parklicht hinten links aktiv" ;
VAL_ 982 LH_Parklicht_HR_aktiv 0 "nicht aktiv" 1 "Parklicht hinten rechts aktiv" ;
VAL_ 982 LH_Bremslicht_H_aktiv 1 "Bremslicht hinten aktiv" ;
VAL_ 982 LH_Nebelschluss_aktiv 0 "nicht aktiv" 1 "aktiv" ;
VAL_ 982 LH_Rueckfahrlicht_aktiv 0 "nicht_aktiv" 1 "aktiv" ;
VAL_ 982 LH_Blinker_HL_akt 1 "Blinker hinten links aktiv" ;
VAL_ 982 LH_Blinker_HR_akt 1 "Blinker hinten rechts aktiv" ;
VAL_ 982 LH_Blinker_li_def 0 "OK" 1 "Blinker hinten links defekt" ;
VAL_ 982 LH_Bremsl_li_def 0 "OK" 1 "mindestens ein Bremslicht hinten links defekt" ;
VAL_ 982 LH_Schlusslicht_li_def 0 "OK" 1 "mindestens ein Schlusslicht hinten links defekt" ;
VAL_ 982 LH_Rueckf_li_def 0 "OK" 1 "Rückfahrlicht hinten links defekt" ;
VAL_ 982 LH_Nebel_li_def 0 "OK" 1 " Nebelschlusslicht hinten links defekt" ;
VAL_ 982 LH_Schluss_Brems_Nebel_li_def 0 "iO" 1 "defekt" ;
VAL_ 982 LH_Schluss_Brems_Nebel_re_def 0 "iO" 1 "defekt" ;
VAL_ 982 LH_Zusatzschlussl_def 0 "OK" 1 "mindestens_ein_Zusatzschlusslicht_defekt" ;
VAL_ 982 LH_Schluss_Brems_li_def 0 "OK" 1 "defekt" ;
VAL_ 982 LH_Schluss_Nebel_li_def 0 "OK" 1 "defekt" ;
VAL_ 982 LH_SL_BRL_BLK_li_def 0 "OK" 1 "defekt" ;
VAL_ 982 LH_Brems_Blk_li_def 0 "OK" 1 "defekt" ;
VAL_ 982 LH_Diag_Status_re_def 0 "OK" 1 "Aussenlict_Diagnose_Systemstoerung_rechts" ;
VAL_ 982 LH_Diag_Status_li_def 0 "OK" 1 "Aussenlicht_Diagnose_Systemstoerung_links" ;
VAL_ 982 LH_Diag_LED_li_def 0 "OK" 1 "Heckleuchte_links_defekt" ;
VAL_ 982 LH_Diag_LED_re_def 0 "OK" 1 "Heckleuchte_rechts_defekt" ;
VAL_ 982 LH_Blinker_re_def 0 "OK" 1 "Blinker hinten rechts defekt" ;
VAL_ 982 LH_Bremsl_re_def 0 "OK" 1 "mindestens ein Bremslicht hinten rechts defekt" ;
VAL_ 982 LH_Schlusslicht_re_def 0 "OK" 1 "mindestens ein Schlusslicht hinten rechts defekt" ;
VAL_ 982 LH_Rueckf_re_def 0 "OK" 1 "Rückfahrlicht hinten rechts defekt" ;
VAL_ 982 LH_Nebel_re_def 0 "OK" 1 "Nebelschlusslicht hinten rechts defekt" ;
VAL_ 982 LH_Schluss_Brems_mi_def 0 "OK" 1 "Defekt" ;
VAL_ 982 LH_Schluss_Brems_re_def 0 "OK" 1 "defekt" ;
VAL_ 982 LH_Schluss_Nebel_re_def 0 "OK" 1 "defekt" ;
VAL_ 982 LH_SL_BRL_BLK_re_def 0 "OK" 1 "defekt" ;
VAL_ 982 LH_Brems_Blk_re_def 0 "OK" 1 "defekt" ;
VAL_ 982 LH_Kennzl_def 0 "OK" 1 "Kennzeichenbeleuchtung hinten defekt" ;
VAL_ 982 LH_3_Bremsl_def 0 "OK" 1 "hochgesetzte  Bremsleuchte defekt" ;
VAL_ 982 LH_Nebel_mi_def 0 "OK" 1 " Nebelschlusslicht hinten Mitte defekt" ;
VAL_ 982 LH_Rueckf_mi_def 0 "OK" 1 "Rückfahllicht Mitte defekt" ;
VAL_ 982 LH_Schlusslicht_mi_def 0 "OK" 1 "defekt" ;
VAL_ 982 LH_Bremsl_mi_def 0 "OK" 1 "defekt" ;
VAL_ 982 LH_Bremsl_li_ges_def 0 "OK" 1 "Alle Bremslichter hinten links defekt" ;
VAL_ 982 LH_Bremsl_re_ges_def 0 "OK" 1 "Alle Bremslichter hinten rechts defekt" ;
